VERSION "FL_EP_CANFD"

NS_ :

BS_:

BU_: BMS CDU DCB EAC EVCC FLZCU LBMS RXCU

BO_ 258 BMS_1: 48 BMS
 SG_ BMS_1_CRC1 : 7|8@0+ (1,0) [0|255] "" RXCU
 SG_ BMS_1_RollgCntr1 : 11|4@0+ (1,0) [0|14] "" RXCU
 SG_ BMS_1_Resd1 : 15|4@0+ (1,0) [0|15] "" RXCU
 SG_ BMS_PackVoltage : 23|16@0+ (0.1,0) [0|1000] "volt(V)" RXCU
 SG_ BMS_PackCurrent : 39|16@0+ (0.1,-2047) [-2047|2047] "ampere(A)" RXCU
 SG_ BMS_HvBattSts : 51|4@0+ (1,0) [0|15] "" RXCU
 SG_ BMS_SysSelfCheck : 53|2@0+ (1,0) [0|3] "" RXCU
 SG_ BMS_HVBattThermRunaway : 55|2@0+ (1,0) [0|3] "" RXCU
 SG_ BMS_1_CRC2 : 71|8@0+ (1,0) [0|255] "" RXCU
 SG_ BMS_1_RollgCntr2 : 75|4@0+ (1,0) [0|14] "" RXCU
 SG_ BMS_1_Resd2 : 79|4@0+ (1,0) [0|15] "" RXCU
 SG_ BMS_ChargeVoltageReq : 87|14@0+ (0.1,0) [0|1024] "volt(V)" RXCU
 SG_ BMS_ChgCurrReq : 103|14@0+ (0.1,-1024) [-1024|0] "ampere(A)" RXCU
 SG_ BMS_InfraDcUActDc : 119|14@0+ (0.1,0) [0|1024] "volt(V)" RXCU
 SG_ BMS_1_CRC3 : 135|8@0+ (1,0) [0|255] "" RXCU
 SG_ BMS_1_RollgCntr3 : 139|4@0+ (1,0) [0|14] "" RXCU
 SG_ BMS_1_Resd3 : 143|4@0+ (1,0) [0|15] "" RXCU
 SG_ BMS_InfraDcIActDc : 151|14@0+ (0.1,-1024) [-1024|0] "ampere(A)" RXCU
 SG_ BMS_HvBattDynChrgnILim : 167|14@0+ (0.1,-1024) [-1024|0] "ampere(A)" RXCU
 SG_ BMS_HvBattUChrgnLim : 183|14@0+ (0.1,0) [0|1024] "volt(V)" RXCU
 SG_ BMS_1_CRC4 : 199|8@0+ (1,0) [0|255] "" RXCU
 SG_ BMS_1_RollgCntr4 : 203|4@0+ (1,0) [0|14] "" RXCU
 SG_ BMS_1_Resd4 : 207|4@0+ (1,0) [0|15] "" RXCU
 SG_ BMS_ChrgDcIAvl : 215|14@0+ (0.1,-1024) [-1024|0] "ampere(A)" RXCU
 SG_ BMS_DChrgAPlusSt : 217|1@0+ (1,0) [0|1] "" RXCU
 SG_ BMS_Insulation_R : 231|16@0+ (1,0) [0|60000] "kiloohm(kΩ)" RXCU
 SG_ BMS_ChrgDcCnctrDetd : 241|2@0+ (1,0) [0|3] "" RXCU
 SG_ BMS_DCChgMode : 244|3@0+ (1,0) [0|7] "" RXCU
 SG_ BMS_ChrgDcChrgnFltStopReas : 247|3@0+ (1,0) [0|7] "" RXCU
 SG_ BMS_1_CRC5 : 263|8@0+ (1,0) [0|255] "" RXCU
 SG_ BMS_1_RollgCntr5 : 267|4@0+ (1,0) [0|14] "" RXCU
 SG_ BMS_1_Resd5 : 271|4@0+ (1,0) [0|15] "" RXCU
 SG_ BMS_ChgRemTime : 279|11@0+ (1,0) [0|1440] "min" RXCU
 SG_ BMS_ChargeRequest_Mode : 284|4@0+ (1,0) [0|15] "" RXCU
 SG_ BMS_StateOfEnergy : 311|16@0+ (0.1,0) [0|999.9] "kWh" RXCU
 SG_ BMS_1_CRC6 : 327|8@0+ (1,0) [0|255] "" RXCU
 SG_ BMS_1_RollgCntr6 : 331|4@0+ (1,0) [0|14] "" RXCU
 SG_ BMS_1_Resd6 : 335|4@0+ (1,0) [0|15] "" RXCU
 SG_ BMS_StateOfHealth : 342|7@0+ (1,0) [0|100] "" RXCU
 SG_ BMS_BlanceState : 343|1@0+ (1,0) [0|1] "" RXCU
 SG_ BMS_IsolationFault : 345|2@0+ (1,0) [0|3] "" RXCU
 SG_ BMS_HVILFault_DC : 346|1@0+ (1,0) [0|1] "" RXCU
 SG_ BMS_SOCDis : 359|14@0+ (0.01,0) [0|100] "%" RXCU
 SG_ BMS_InfraDcIActDcMin : 375|14@0+ (0.1,-1024) [-1024|0] "ampere(A)" RXCU

BO_ 369 VCU_COM_1: 16 RXCU
 SG_ VCU_1_CRC1 : 7|8@0+ (1,0) [0|255] "" BMS
 SG_ VCU_1_RollgCntr1 : 11|4@0+ (1,0) [0|14] "" BMS
 SG_ VCU_1_Resd1 : 15|4@0+ (1,0) [0|15] "" BMS
 SG_ VCU_BMSPreheatKeepWarmAllow : 18|3@0+ (1,0) [0|7] "" BMS,CDU
 SG_ VCU_BMSAcChrgPerm : 19|1@0+ (1,0) [0|1] "" BMS,CDU
 SG_ VCU_BMSStsReq_Reserved : 23|4@0+ (1,0) [0|15] "" BMS
 SG_ VCU_ElectronicLockReq : 35|2@0+ (1,0) [0|3] "" Vector__XXX
 SG_ VCU_ErrLvl : 39|4@0+ (1,0) [0|15] "" Vector__XXX
 SG_ VCU_PwtCoolingLvl_171h : 42|3@0+ (1,0) [0|7] "" Vector__XXX
 SG_ HCU_BMSVehDcChrgnIDmd_171h : 55|14@0+ (0.1,-1024) [-1024|0] "A" BMS

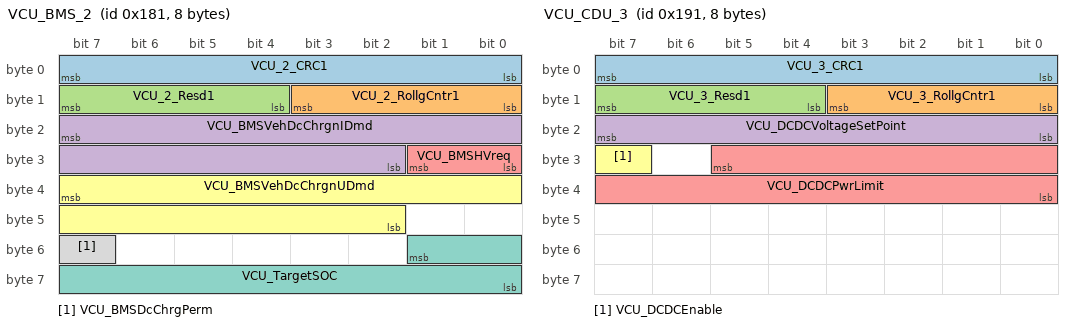
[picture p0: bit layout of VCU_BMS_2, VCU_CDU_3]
BO_ 385 VCU_BMS_2: 8 RXCU
 SG_ VCU_2_CRC1 : 7|8@0+ (1,0) [0|255] "" BMS,FLZCU
 SG_ VCU_2_RollgCntr1 : 11|4@0+ (1,0) [0|14] "" BMS,FLZCU
 SG_ VCU_2_Resd1 : 15|4@0+ (1,0) [0|15] "" BMS,FLZCU
 SG_ VCU_BMSVehDcChrgnIDmd : 23|14@0+ (0.1,-1024) [-1024|0] "ampere (A)" BMS,DCB,FLZCU
 SG_ VCU_BMSHVreq : 25|2@0+ (1,0) [0|3] "" BMS,FLZCU
 SG_ VCU_BMSVehDcChrgnUDmd : 39|14@0+ (0.1,0) [0|1024] "volt (V)" BMS,FLZCU
 SG_ VCU_TargetSOC : 49|10@0+ (0.1,0) [0|100] "%" BMS,FLZCU
 SG_ VCU_BMSDcChrgPerm : 55|1@0+ (1,0) [0|1] "" BMS,FLZCU

BO_ 401 VCU_CDU_3: 8 RXCU
 SG_ VCU_3_CRC1 : 7|8@0+ (1,0) [0|255] "" CDU
 SG_ VCU_3_RollgCntr1 : 11|4@0+ (1,0) [0|14] "" CDU
 SG_ VCU_3_Resd1 : 15|4@0+ (1,0) [0|15] "" CDU
 SG_ VCU_DCDCVoltageSetPoint : 23|8@0+ (0.1,0) [0|20] "V" CDU,LBMS
 SG_ VCU_DCDCPwrLimit : 29|14@0+ (1,0) [0|16382] "w" CDU
 SG_ VCU_DCDCEnable : 31|1@0+ (1,0) [0|1] "" CDU

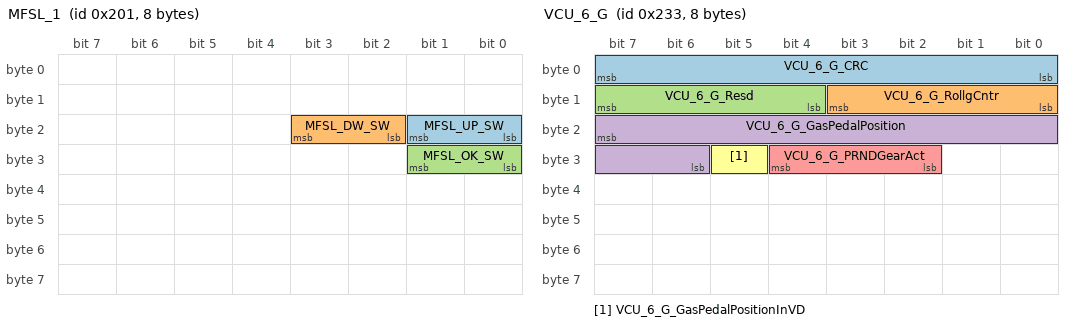
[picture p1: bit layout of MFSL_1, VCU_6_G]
BO_ 513 MFSL_1: 8 FLZCU
 SG_ MFSL_UP_SW : 17|2@0+ (1,0) [0|3] "" RXCU
 SG_ MFSL_DW_SW : 19|2@0+ (1,0) [0|3] "" RXCU
 SG_ MFSL_OK_SW : 25|2@0+ (1,0) [0|3] "" RXCU

BO_ 515 EVCC_1: 24 EVCC
 SG_ EVCC_1_CRC1 : 7|8@0+ (1,0) [0|255] "" RXCU
 SG_ EVCC_1_RollgCntr1 : 11|4@0+ (1,0) [0|14] "" RXCU
 SG_ EVCC_1_Resd1 : 15|4@0+ (1,0) [0|15] "" RXCU
 SG_ EVCC_ElectronicLockSts : 21|3@0+ (1,0) [0|7] "" RXCU
 SG_ EVCC_GunConnectSt_203h : 23|2@0+ (1,0) [0|3] "" RXCU
 SG_ EVCC_CC_RCR4_Sts : 30|13@0+ (1,0) [0|3400] "R" RXCU
 SG_ EVCC_COUNTRY_SUPPORT : 32|2@0+ (1,0) [0|3] "" RXCU
 SG_ EVCC_CP_DutyCycleFault : 33|1@0+ (1,0) [0|1] "" RXCU
 SG_ EVCC_CC_ConnectSts : 49|2@0+ (1,0) [0|3] "" RXCU
 SG_ EVCC_S2Swtsts : 51|2@0+ (1,0) [0|3] "" RXCU
 SG_ EVCC_CPSts : 54|3@0+ (1,0) [0|7] "" RXCU
 SG_ EVCC_ChargeType : 58|3@0+ (1,0) [0|7] "" RXCU
 SG_ EVCC_CC2_Alarm : 59|1@0+ (1,0) [0|1] "" RXCU
 SG_ EVCC_CC2_ConnectSts : 61|2@0+ (1,0) [0|3] "" RXCU
 SG_ EVCC_CC_ConnectDischarSts : 63|2@0+ (1,0) [0|3] "" RXCU
 SG_ EVCC_1_CRC2 : 71|8@0+ (1,0) [0|255] "" RXCU
 SG_ EVCC_1_RollgCntr2 : 75|4@0+ (1,0) [0|14] "" RXCU
 SG_ EVCC_1_Resd2 : 79|4@0+ (1,0) [0|15] "" RXCU
 SG_ EVCC_CPMaxVolt : 84|10@0+ (0.1,0) [0|102.2] "V" RXCU
 SG_ EVCC_FaultLevel : 87|3@0+ (1,0) [0|7] "" RXCU
 SG_ EVCC_DCPlusTemp : 90|8@0+ (1,-40) [-40|213] "℃" RXCU
 SG_ EVCC_DCMinusTemp : 98|8@0+ (1,-40) [-40|213] "℃" RXCU
 SG_ EVCC_TotalFaultNum : 106|8@0+ (1,0) [0|63] "" RXCU
 SG_ EVCC_FaultNum1 : 114|8@0+ (1,0) [0|255] "" RXCU
 SG_ EVCC_FaultNum2 : 151|8@0+ (1,0) [0|255] "" RXCU

BO_ 520 BMS_2: 48 BMS
 SG_ BMS_2_CRC1 : 7|8@0+ (1,0) [0|255] "" RXCU
 SG_ BMS_2_RollgCntr1 : 11|4@0+ (1,0) [0|14] "" RXCU
 SG_ BMS_2_Resd1 : 15|4@0+ (1,0) [0|15] "" RXCU
 SG_ BMS_C2Target_Chg_Voltage : 23|16@0+ (0.1,0) [0|1000] "V" RXCU
 SG_ BMS_CHGstation_MAXPwr : 39|8@0+ (2,0) [0|510] "KW" RXCU
 SG_ BMS_2_CRC2 : 71|8@0+ (1,0) [0|255] "" RXCU
 SG_ BMS_2_RollgCntr2 : 75|4@0+ (1,0) [0|14] "" RXCU
 SG_ BMS_2_Resd2 : 79|4@0+ (1,0) [0|15] "" RXCU
 SG_ BMS_HvBattThermReqLevel : 81|4@0+ (1,0) [0|15] "" RXCU
 SG_ BMS_NV_relay_Sts : 84|3@0+ (1,0) [0|7] "" RXCU
 SG_ BMS_PV_relay_Sts : 87|3@0+ (1,0) [0|7] "" RXCU
 SG_ BMS_QCP_relay_Sts : 90|3@0+ (1,0) [0|7] "" RXCU
 SG_ BMS_QCN_relay_Sts : 93|3@0+ (1,0) [0|7] "" RXCU
 SG_ BMS_Prechage_relay_Sts : 98|3@0+ (1,0) [0|7] "" RXCU
 SG_ BMS_HvBattThermReqMode : 103|4@0+ (1,0) [0|15] "" RXCU
 SG_ BMS_ClntTHvBattIn : 111|8@0+ (1,-40) [-40|120] "gradcelsius(°C)" RXCU
 SG_ BMS_ClntTHvBattOut : 119|8@0+ (1,-40) [-40|120] "gradcelsius(°C)" RXCU
 SG_ BMS_HvBattClntInTReq : 127|7@0+ (1,-40) [-40|53] "gradcelsius(°C)" RXCU
 SG_ BMS_2_CRC3 : 135|8@0+ (1,0) [0|255] "" RXCU
 SG_ BMS_2_RollgCntr3 : 139|4@0+ (1,0) [0|14] "" RXCU
 SG_ BMS_2_Resd3 : 143|4@0+ (1,0) [0|15] "" RXCU
 SG_ BMS_HvBattClntFlowReq : 151|7@0+ (0.25,0) [0|31] "flow-rate(l/min)" RXCU
 SG_ BMS_HvBattAvgT : 159|8@0+ (1,-40) [-40|120] "gradcelsius(°C)" RXCU
 SG_ BMS_HvBattMaxT : 167|8@0+ (1,-40) [-40|210] "gradcelsius(°C)" RXCU
 SG_ BMS_HvBattMinT : 175|8@0+ (1,-40) [-40|210] "gradcelsius(°C)" RXCU
 SG_ BMS_HvBattTdiff : 183|7@0+ (1,0) [0|127] "gradcelsius(°C)" RXCU
 SG_ BMS_2_CRC4 : 199|8@0+ (1,0) [0|255] "" RXCU
 SG_ BMS_2_RollgCntr4 : 203|4@0+ (1,0) [0|14] "" RXCU
 SG_ BMS_2_Resd4 : 207|4@0+ (1,0) [0|15] "" RXCU
 SG_ BMS_OutPosU : 223|14@0+ (0.1,0) [0|1023.0] "volt(V)" RXCU
 SG_ BMS_OutNegU : 239|14@0+ (0.1,0) [0|1023.0] "volt(V)" RXCU
 SG_ BMS_2_CRC5 : 263|8@0+ (1,0) [0|255] "" RXCU
 SG_ BMS_2_RollgCntr5 : 267|4@0+ (1,0) [0|14] "" RXCU
 SG_ BMS_2_Resd5 : 271|4@0+ (1,0) [0|15] "" RXCU
 SG_ BMS_outQCPosU : 279|14@0+ (0.1,0) [0|1023.0] "volt(V)" RXCU
 SG_ BMS_outQCNegU : 295|14@0+ (0.1,0) [0|1023.0] "volt(V)" RXCU
 SG_ BMS_Middlesplit_relay_Sts : 311|3@0+ (1,0) [0|7] "" RXCU

BO_ 523 BMS_3: 48 BMS
 SG_ BMS_3_CRC1 : 7|8@0+ (1,0) [0|255] "" RXCU
 SG_ BMS_3_RollgCntr1 : 11|4@0+ (1,0) [0|14] "" RXCU
 SG_ BMS_3_Resd1 : 15|4@0+ (1,0) [0|15] "" RXCU
 SG_ BMS_HvBattPMaxReChrgLim : 39|14@0+ (0.1,0) [0|1024] "kW" RXCU
 SG_ BMS_3_CRC2 : 71|8@0+ (1,0) [0|255] "" RXCU
 SG_ BMS_3_RollgCntr2 : 75|4@0+ (1,0) [0|14] "" RXCU
 SG_ BMS_3_Resd2 : 79|4@0+ (1,0) [0|15] "" RXCU
 SG_ BMS_HvBattIMaxReChrgLim : 87|11@0+ (1,-2047) [-2047|0] "ampere(A)" RXCU
 SG_ BMS_HvBattPMaxDchaLim : 119|14@0+ (0.1,0) [0|1024] "kW" RXCU
 SG_ BMS_3_CRC3 : 135|8@0+ (1,0) [0|255] "" RXCU
 SG_ BMS_3_RollgCntr3 : 139|4@0+ (1,0) [0|14] "" RXCU
 SG_ BMS_3_Resd3 : 143|4@0+ (1,0) [0|15] "" RXCU
 SG_ BMS_HvBattIMaxDchaLim : 167|11@0+ (1,0) [0|2047] "ampere(A)" RXCU
 SG_ BMS_3_CRC4 : 199|8@0+ (1,0) [0|255] "" RXCU
 SG_ BMS_3_RollgCntr4 : 203|4@0+ (1,0) [0|14] "" RXCU
 SG_ BMS_3_Resd4 : 207|4@0+ (1,0) [0|15] "" RXCU
 SG_ BMS_3_CRC5 : 263|8@0+ (1,0) [0|255] "" RXCU
 SG_ BMS_3_RollgCntr5 : 267|4@0+ (1,0) [0|14] "" RXCU
 SG_ BMS_3_Resd5 : 271|4@0+ (1,0) [0|15] "" RXCU
 SG_ BMS_KL30Volt : 279|11@0+ (0.01,0) [0|20] "volt(V)" RXCU
 SG_ BMS_kL87Volt : 295|11@0+ (0.01,0) [0|20] "volt(V)" RXCU
 SG_ BMS_HvBattUDchaLim : 311|14@0+ (0.1,0) [0|1024] "volt(V)" RXCU
 SG_ BMS_3_CRC6 : 327|8@0+ (1,0) [0|255] "" RXCU
 SG_ BMS_3_RollgCntr6 : 331|4@0+ (1,0) [0|14] "" RXCU
 SG_ BMS_3_Resd6 : 335|4@0+ (1,0) [0|15] "" RXCU
 SG_ BMSH_MaxChgPwrPeak : 343|12@0+ (0.1,0) [0|320] "KW" RXCU
 SG_ BMSH_MaxDchgPwrPeak : 347|12@0+ (0.1,0) [0|320] "KW" RXCU

BO_ 563 VCU_6_G: 8 RXCU
 SG_ VCU_6_G_CRC : 7|8@0+ (1,0) [0|255] "" FLZCU
 SG_ VCU_6_G_RollgCntr : 11|4@0+ (1,0) [0|14] "" FLZCU
 SG_ VCU_6_G_Resd : 15|4@0+ (1,0) [0|15] "" FLZCU
 SG_ VCU_6_G_GasPedalPosition : 23|10@0+ (0.1,0) [0|100] "%" FLZCU
 SG_ VCU_6_G_PRNDGearAct : 28|3@0+ (1,0) [0|7] "" FLZCU
 SG_ VCU_6_G_GasPedalPositionInVD : 29|1@0+ (1,0) [0|1] "" FLZCU

BO_ 638 FRZCU_9: 16 FLZCU
 SG_ FRZCU_HoodSts : 45|2@0+ (1,0) [0|3] "" RXCU

BO_ 644 ICC_REEV_17: 8 FLZCU
 SG_ ICM_5_FuelLevel_284h : 23|8@0+ (1,0) [0|100] "%" RXCU

BO_ 683 FRZCU_1: 8 FLZCU
 SG_ PassDoorSts_2ABh : 22|2@0+ (1,0) [0|3] "" RXCU
 SG_ PassRearDoorSts_2ABh : 49|2@0+ (1,0) [0|3] "" RXCU

BO_ 745 DCB_1: 32 DCB
 SG_ DCB_1_HVILSts : 17|2@0+ (1,0) [0|3] "" RXCU
 SG_ DCB_1_BoostNegRelaySts : 20|3@0+ (1,0) [0|7] "" RXCU
 SG_ DCB_1_WorkingSts : 23|3@0+ (1,0) [0|7] "" RXCU
 SG_ DCB_1_NegFastChgRelaySts : 28|3@0+ (1,0) [0|7] "" RXCU
 SG_ DCB_1_C2RelaySts : 31|3@0+ (1,0) [0|7] "" RXCU
 SG_ DCB_1_ErrorLevel : 36|3@0+ (1,0) [0|7] "" RXCU
 SG_ DCB_1_PosFastChgRelaySts : 39|3@0+ (1,0) [0|7] "" RXCU
 SG_ DCB_1_ChrgDerate : 63|8@0+ (1,0) [0|100] "%" RXCU
 SG_ DCB_1_C2RearVolt : 103|16@0+ (0.05,0) [0|1000] "V" RXCU
 SG_ DCB_1_InputVolt : 119|16@0+ (0.05,0) [0|1000] "V" RXCU
 SG_ DCB_1_BoostNegFrontVolt : 151|16@0+ (0.05,0) [0|1000] "V" RXCU
 SG_ DCB_1_NegFastChgFrontVolt : 167|16@0+ (0.05,0) [0|1000] "V" RXCU
 SG_ DCB_1_BoostPosFastChgRearVolt : 183|16@0+ (0.05,0) [0|1000] "V" RXCU
 SG_ DCB_1_BoostPosRelaySts : 223|3@0+ (1,0) [0|7] "" RXCU

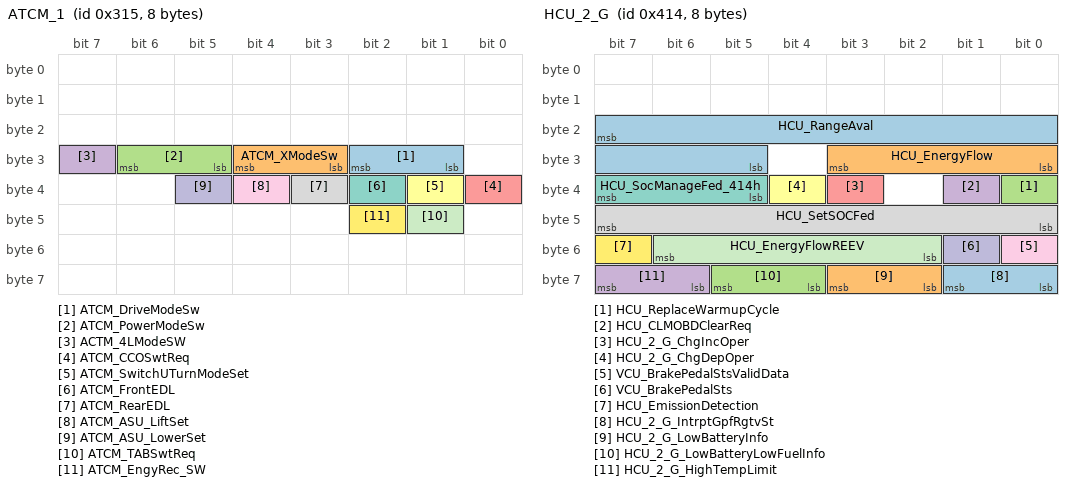
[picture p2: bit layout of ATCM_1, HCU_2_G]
BO_ 789 ATCM_1: 8 FLZCU
 SG_ ATCM_DriveModeSw : 26|2@0+ (1,0) [0|3] "" RXCU
 SG_ ATCM_XModeSw : 28|2@0+ (1,0) [0|3] "" RXCU
 SG_ ATCM_PowerModeSw : 30|2@0+ (1,0) [0|3] "" RXCU
 SG_ ACTM_4LModeSW : 31|1@0+ (1,0) [0|1] "" RXCU
 SG_ ATCM_CCOSwtReq : 32|1@0+ (1,0) [0|1] "" RXCU
 SG_ ATCM_SwitchUTurnModeSet : 33|1@0+ (1,0) [0|1] "" RXCU
 SG_ ATCM_FrontEDL : 34|1@0+ (1,0) [0|1] "" RXCU
 SG_ ATCM_RearEDL : 35|1@0+ (1,0) [0|1] "" RXCU
 SG_ ATCM_ASU_LiftSet : 36|1@0+ (1,0) [0|1] "" RXCU
 SG_ ATCM_ASU_LowerSet : 37|1@0+ (1,0) [0|1] "" RXCU
 SG_ ATCM_TABSwtReq : 41|1@0+ (1,0) [0|1] "" RXCU
 SG_ ATCM_EngyRec_SW : 42|1@0+ (1,0) [0|1] "" RXCU

BO_ 859 FLZCU_5: 8 FLZCU
 SG_ FLZCU_IRCHV_Req : 31|2@0+ (1,0) [0|3] "" RXCU

BO_ 961 IMMO_VCU_1: 8 FLZCU
 SG_ IMMO_Auth_VCU : 7|64@0+ (1,0) [0|18446744073709551615] "" RXCU

BO_ 962 VCU_IMMO_1: 8 RXCU
 SG_ VCU_Chall_IMMO : 7|64@0+ (1,0) [0|18446744073709551615] "" FLZCU

BO_ 964 IMMO_VCU_3: 8 FLZCU
 SG_ IMMO_Teach_VCU : 7|64@0+ (1,0) [0|18446744073709551615] "" RXCU

BO_ 966 VCU_IMMO_3: 8 RXCU
 SG_ VCU_Teach_IMMO : 7|64@0+ (1,0) [0|18446744073709551615] "" FLZCU

BO_ 991 TMS_2: 24 FLZCU
 SG_ ErrorLevel : 91|2@0+ (1,0) [0|3] "" RXCU
 SG_ TMS_HV_Req : 94|2@0+ (1,0) [0|3] "" RXCU
 SG_ TMS_EngingstartReq : 127|1@0+ (1,0) [0|1] "" RXCU

BO_ 1024 FRZCU_13: 64 FLZCU
 SG_ FRZCU_OnekeyHVoffSwtst : 41|2@0+ (1,0) [0|3] "" RXCU

BO_ 1029 LBMS_SysSt1: 32 LBMS
 SG_ LBMS_PackExtU : 91|15@0+ (0.001,0) [0|20] "V" RXCU
 SG_ LBMS_PackT1 : 106|8@0+ (1,-40) [-40|125] "degC" RXCU
 SG_ LBMS_PackExtUVld : 107|1@0+ (1,0) [0|1] "" RXCU
 SG_ LBMS_PackT2 : 114|8@0+ (1,-40) [-40|125] "degC" RXCU
 SG_ LBMS_PackT3 : 122|8@0+ (1,-40) [-40|125] "degC" RXCU
 SG_ LBMS_PackTVld : 130|1@0+ (1,0) [0|1] "" RXCU

BO_ 1034 HCU_1_G: 8 RXCU
 SG_ HCU_1_G_CRC1 : 7|8@0+ (1,0) [0|255] "" Vector__XXX
 SG_ HCU_1_G_RollgCntr1 : 11|4@0+ (1,0) [0|14] "" Vector__XXX
 SG_ HCU_1_G_Resd1 : 15|4@0+ (1,0) [0|15] "" Vector__XXX
 SG_ HCU_EmPwr : 23|8@0+ (1,-128) [-100|100] "%" Vector__XXX
 SG_ HCU_VehicleState : 27|4@0+ (1,0) [0|15] "" Vector__XXX
 SG_ HCU_RunMode : 29|2@0+ (1,0) [0|3] "" Vector__XXX
 SG_ HCU_TMNumber : 31|2@0+ (1,0) [0|3] "" Vector__XXX
 SG_ HCU_PwrTrnModeDisp : 34|3@0+ (1,0) [0|7] "" Vector__XXX
 SG_ HCU_IntelligentPowerSupply : 37|3@0+ (1,0) [0|7] "" Vector__XXX
 SG_ HCU_PowerModeFed : 39|2@0+ (1,0) [0|3] "" BMS
 SG_ HCU_LimpHomeMode : 41|2@0+ (1,0) [0|3] "" Vector__XXX
 SG_ HCU_ISGRegenerateSts : 42|1@0+ (1,0) [0|1] "" Vector__XXX
 SG_ HCU_EmOverSpdWarn : 43|1@0+ (1,0) [0|1] "" Vector__XXX
 SG_ HCU_PowertrainFault : 44|1@0+ (1,0) [0|1] "" Vector__XXX
 SG_ HCU_PrePTReady : 45|1@0+ (1,0) [0|1] "" Vector__XXX
 SG_ HCU_PowerModeChangeFail : 46|1@0+ (1,0) [0|1] "" Vector__XXX
 SG_ BMSH_MILReq : 47|1@0+ (1,0) [0|1] "" Vector__XXX
 SG_ TMF_EngMilLampReq : 48|1@0+ (1,0) [0|1] "" Vector__XXX
 SG_ TMR_EngMilLampReq : 49|1@0+ (1,0) [0|1] "" Vector__XXX
 SG_ HCU_MILReq : 50|1@0+ (1,0) [0|1] "" Vector__XXX
 SG_ HCU_HVReady : 51|1@0+ (1,0) [0|1] "" BMS
 SG_ HCU_PTReady : 52|1@0+ (1,0) [0|1] "" BMS
 SG_ HCU_ChargingSts : 54|2@0+ (1,0) [0|3] "" Vector__XXX
 SG_ HCU_PtSts : 59|4@0+ (1,0) [0|15] "" Vector__XXX
 SG_ HCU_InHbStrtRes : 63|4@0+ (1,0) [0|15] "" Vector__XXX

BO_ 1035 VCC_1: 8 FLZCU
 SG_ VCC_1_OTASts : 17|2@0+ (1,0) [0|3] "" RXCU

BO_ 1038 LBMS_SysSt2: 48 LBMS
 SG_ LBMS_SOC : 31|7@0+ (1,0) [0|100] "%" RXCU
 SG_ LBMS_ReChrgReq : 33|3@0+ (1,0) [0|7] "" RXCU
 SG_ LBMS_ReqChrgU : 80|15@0+ (0.001,0) [0|20] "V" RXCU

BO_ 1039 LBMS_SysSt3: 32 LBMS
 SG_ LBMS_ChargeSts : 48|4@0+ (1,0) [0|15] "" RXCU
 SG_ LBMS_ChargeFlt : 49|1@0+ (1,0) [0|1] "" RXCU
 SG_ LBMS_ChargeEnable : 51|1@0+ (1,0) [0|1] "" RXCU

BO_ 1043 FLZCU_8: 8 FLZCU
 SG_ EBS_U_BATT : 7|14@0+ (0.0009765625,3) [3|18] "V" RXCU

BO_ 1044 HCU_2_G: 8 RXCU
 SG_ HCU_RangeAval : 23|11@0+ (1,0) [0|2046] "KM" FLZCU
 SG_ HCU_EnergyFlow : 27|4@0+ (1,0) [0|15] "" FLZCU
 SG_ HCU_ReplaceWarmupCycle : 32|1@0+ (1,0) [0|1] "" BMS,FLZCU
 SG_ HCU_CLMOBDClearReq : 33|1@0+ (1,0) [0|1] "" FLZCU
 SG_ HCU_2_G_ChgIncOper : 35|1@0+ (1,0) [0|1] "" FLZCU
 SG_ HCU_2_G_ChgDepOper : 36|1@0+ (1,0) [0|1] "" FLZCU
 SG_ HCU_SocManageFed_414h : 39|3@0+ (1,0) [0|7] "" FLZCU
 SG_ HCU_SetSOCFed : 47|8@0+ (1,0) [0|100] "" FLZCU
 SG_ VCU_BrakePedalStsValidData : 48|1@0+ (1,0) [0|1] "" FLZCU
 SG_ VCU_BrakePedalSts : 49|1@0+ (1,0) [0|1] "" FLZCU
 SG_ HCU_EnergyFlowREEV : 54|5@0+ (1,0) [0|31] "" FLZCU
 SG_ HCU_EmissionDetection : 55|1@0+ (1,0) [0|1] "" FLZCU
 SG_ HCU_2_G_IntrptGpfRgtvSt : 57|2@0+ (1,0) [0|3] "" FLZCU
 SG_ HCU_2_G_LowBatteryInfo : 59|2@0+ (1,0) [0|3] "" FLZCU
 SG_ HCU_2_G_LowBatteryLowFuelInfo : 61|2@0+ (1,0) [0|3] "" FLZCU
 SG_ HCU_2_G_HighTempLimit : 63|2@0+ (1,0) [0|3] "" FLZCU

BO_ 1045 TBOX_HW_415h: 32 FLZCU
 SG_ TBOX_OTAHV_Req_415h : 20|2@0+ (1,0) [0|3] "" RXCU

BO_ 1055 BMS_4: 16 BMS
 SG_ BMS_4_CRC1 : 7|8@0+ (1,0) [0|255] "" RXCU
 SG_ BMS_4_RollgCntr1 : 11|4@0+ (1,0) [0|14] "" RXCU
 SG_ BMS_4_Resd1 : 15|4@0+ (1,0) [0|15] "" RXCU
 SG_ BMS_ErrorNumber : 47|8@0+ (1,0) [0|255] "" RXCU
 SG_ BMS_ErrorCode : 55|16@0+ (1,0) [0|65535] "" RXCU
 SG_ BMS_4_CRC2 : 71|8@0+ (1,0) [0|255] "" RXCU
 SG_ BMS_4_RollgCntr2 : 75|4@0+ (1,0) [0|14] "" RXCU
 SG_ BMS_4_Resd2 : 79|4@0+ (1,0) [0|15] "" RXCU
 SG_ BMSH_MILReq_41Fh : 80|1@0+ (1,0) [0|1] "" RXCU
 SG_ BMS_HvBattUnderTemperature : 83|1@0+ (1,0) [0|1] "" RXCU
 SG_ BMS_ErrorLevel : 87|4@0+ (1,0) [0|15] "" RXCU
 SG_ BMS_ThermRunCode : 95|8@0+ (1,0) [0|255] "" RXCU
 SG_ BMS_DChrgEndCode : 103|8@0+ (1,0) [0|255] "" RXCU
 SG_ BMS_PwrDerateFlg : 111|2@0+ (1,0) [0|3] "" RXCU

BO_ 1057 VCU_7_G: 32 RXCU
 SG_ VCU_shfChk : 16|1@0+ (1,0) [0|1] "" FLZCU
 SG_ VCU_PowerLimitSOCLow : 19|3@0+ (1,0) [0|7] "" FLZCU
 SG_ VCU_MCU_MilLampReq : 20|1@0+ (1,0) [0|1] "" FLZCU
 SG_ VCU_OPDinfo : 23|3@0+ (1,0) [0|7] "" FLZCU
 SG_ VCU_ePTDrvPowerPcent : 31|8@0+ (1,-100) [-100|100] "%" FLZCU
 SG_ VCU_TowingMode : 33|2@0+ (1,0) [0|3] "" FLZCU
 SG_ VCU_EgyRegenLevelHighAllowed : 35|2@0+ (1,0) [0|3] "" FLZCU
 SG_ VCU_SportDriveModeAvailable : 36|1@0+ (1,0) [0|1] "" FLZCU
 SG_ VCU_RainSnowDriveModeAvailable : 37|1@0+ (1,0) [0|1] "" FLZCU
 SG_ VCU_OffRoadDriveModeAvailable : 38|1@0+ (1,0) [0|1] "" FLZCU
 SG_ VCU_CampAvailable : 39|1@0+ (1,0) [0|1] "" FLZCU
 SG_ VCU_DisChgSOCHighLim : 47|8@0+ (1,0) [1|100] "%" FLZCU
 SG_ VCU_DisChgSOCLowLim : 55|8@0+ (1,0) [1|50] "%" FLZCU
 SG_ VCU_ChgSocSetFed : 63|8@0+ (1,0) [50|100] "%" FLZCU
 SG_ VCU_EngyConsuPer10Km : 87|12@0+ (0.1,-100) [-100|100] "" FLZCU
 SG_ VCU_EngyConsuPer25Km : 91|12@0+ (0.1,-100) [-100|100] "" FLZCU
 SG_ VCU_EngyConsuPer50Km : 111|12@0+ (0.1,-100) [-100|100] "" FLZCU
 SG_ VCU_EngyConsuPer100m : 115|12@0+ (0.1,-100) [-100|100] "" FLZCU
 SG_ VCU_DisChrgPwr : 151|8@0+ (0.1,0) [0|25.5] "kW" FLZCU
 SG_ VCU_BookChrgSetFailRes : 154|3@0+ (1,0) [0|7] "" FLZCU
 SG_ VCU_BookChrgFailRes : 158|4@0+ (1,0) [0|15] "" FLZCU
 SG_ VCU_HVILFault : 159|1@0+ (1,0) [0|1] "" FLZCU
 SG_ VCUExtendRang : 167|10@0+ (1,0) [0|1022] "KM" FLZCU
 SG_ VCU_KeepWarmFailReason : 171|4@0+ (1,0) [0|15] "" FLZCU
 SG_ VCU_ExtremeEnergySavingModeAv : 173|1@0+ (1,0) [0|1] "" FLZCU
 SG_ VCU_TowModeAvailable : 176|1@0+ (1,0) [0|1] "" FLZCU
 SG_ VCU_StopModeSWStsResp : 178|2@0+ (1,0) [0|3] "" FLZCU
 SG_ VCU_StopModeSWAllowed : 179|1@0+ (1,0) [0|1] "" FLZCU
 SG_ VCU_ChgDisChgLedCtrl : 183|4@0+ (1,0) [0|15] "" FLZCU
 SG_ VCU_CPMaxVolt : 191|8@0+ (0.1,0) [0|20] "V" FLZCU
 SG_ VCUExtremeEnergySavingModeReq : 211|2@0+ (1,0) [0|3] "" FLZCU
 SG_ VCU_EpedalModeSts : 213|1@0+ (1,0) [0|1] "" FLZCU
 SG_ VCU_BookChrgStsFb : 215|2@0+ (1,0) [0|3] "" FLZCU
 SG_ VCU_HVNM : 219|2@0+ (1,0) [0|3] "" FLZCU
 SG_ VCU_DriveMode : 223|3@0+ (1,0) [0|7] "" FLZCU
 SG_ HCU_EnterForceEVFailRes : 229|3@0+ (1,0) [0|7] "" FLZCU
 SG_ HCU_EngineSelfMaintain : 231|2@0+ (1,0) [0|3] "" FLZCU
 SG_ HCU_EnterForceChrgFailRes : 234|3@0+ (1,0) [0|7] "" FLZCU
 SG_ HCU_InStartRes : 242|3@0+ (1,0) [0|7] "" FLZCU
 SG_ HCU_EnergyRegSetFed : 255|8@0+ (1,0) [0|100] "%" FLZCU

BO_ 1078 PLG_1: 8 FLZCU
 SG_ PLG_LatchSts : 33|2@0+ (1,0) [0|3] "" RXCU

BO_ 1086 VCU_CDU_8: 16 RXCU
 SG_ VCU_8_CRC1 : 7|8@0+ (1,0) [0|255] "" CDU
 SG_ VCU_8_RollgCntr1 : 11|4@0+ (1,0) [0|14] "" CDU
 SG_ VCU_8_Resd1 : 15|4@0+ (1,0) [0|15] "" CDU
 SG_ VCU_OBCChgCurrentReq : 23|16@0+ (0.1,0) [0|400] "A" CDU
 SG_ VCU_OBCChgVoltageReq : 39|16@0+ (0.1,0) [0|1000] "V" CDU
 SG_ VCU_OBCDischgPwrLimit : 55|8@0+ (0.1,0) [0|20] "kw" CDU
 SG_ VCU_OBCDischgReq : 63|1@0+ (1,0) [0|1] "" CDU
 SG_ VCU_8_CRC2 : 71|8@0+ (1,0) [0|255] "" CDU
 SG_ VCU_8_RollgCntr2 : 75|4@0+ (1,0) [0|14] "" CDU
 SG_ VCU_8_Resd2 : 79|4@0+ (1,0) [0|15] "" CDU
 SG_ VCU_OBCInnerDischgPwrLimit : 87|8@0+ (0.1,0) [0|20] "kw" CDU
 SG_ VCU_OBCInnerDischgAllow : 88|1@0+ (1,0) [0|1] "" CDU
 SG_ VCU_CLMSystemPowerLimit_43Eh : 119|10@0+ (0.04,0) [0|40] "Kw" Vector__XXX
 SG_ VCU_CLMEACAllow_43Eh : 123|1@0+ (1,0) [0|1] "" Vector__XXX
 SG_ VCU_CLMHVHAllow_43Eh : 124|1@0+ (1,0) [0|1] "" Vector__XXX
 SG_ VCU_CLMHVReady_43Eh : 125|1@0+ (1,0) [0|1] "" Vector__XXX

BO_ 1092 BNCM_11: 8 FLZCU
 SG_ BNCM_11_EVSEConnectSts : 17|2@0+ (1,0) [0|3] "" RXCU

BO_ 1096 TMS_11: 32 FLZCU
 SG_ TMS_ICAstsFed_448h : 111|2@0+ (1,0) [0|3] "" RXCU
 SG_ TMS_RemotekeyReq : 148|3@0+ (1,0) [0|7] "" RXCU
 SG_ TMS_TimedVentilationReq : 151|3@0+ (1,0) [0|7] "" RXCU

BO_ 1111 EAC_Rsp_1: 16 EAC
 SG_ EAC_HVILSts : 41|2@0+ (1,0) [0|3] "" RXCU
 SG_ EAC_ErrorLevel : 122|3@0+ (1,0) [0|7] "" RXCU

BO_ 1117 HVH_Rsp_1: 8 FLZCU
 SG_ HVH_ErrorLevel : 63|3@0+ (1,0) [0|7] "" RXCU

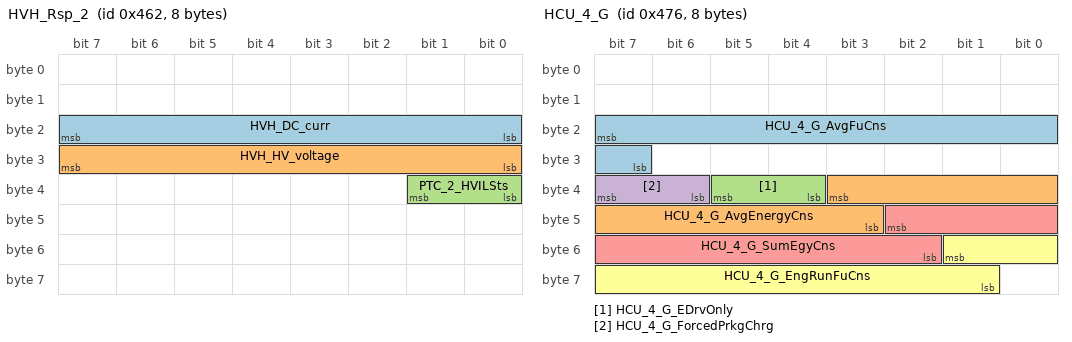
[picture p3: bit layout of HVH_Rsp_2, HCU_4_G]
BO_ 1122 HVH_Rsp_2: 8 FLZCU
 SG_ HVH_DC_curr : 23|8@0+ (0.25,0) [0|50] "A" RXCU
 SG_ HVH_HV_voltage : 31|8@0+ (4,0) [0|1016] "V" RXCU
 SG_ PTC_2_HVILSts : 33|2@0+ (1,0) [0|3] "" RXCU

BO_ 1127 CDU_DCDC_1: 24 CDU
 SG_ CDU_1_CRC1 : 7|8@0+ (1,0) [0|255] "" RXCU
 SG_ CDU_1_RollgCntr1 : 11|4@0+ (1,0) [0|14] "" RXCU
 SG_ CDU_1_Resd1 : 15|4@0+ (1,0) [0|15] "" RXCU
 SG_ DCDC_HvVolt : 23|16@0+ (0.1,0) [0|1000] "V" RXCU
 SG_ DCDC_HVCurr : 39|16@0+ (0.1,0) [0|1000] "A" RXCU
 SG_ DCDC_FaultCode : 55|8@0+ (1,0) [0|255] "" RXCU
 SG_ CDU_1_CRC2 : 71|8@0+ (1,0) [0|255] "" RXCU
 SG_ CDU_1_RollgCntr2 : 75|4@0+ (1,0) [0|14] "" RXCU
 SG_ CDU_1_Resd2 : 79|4@0+ (1,0) [0|15] "" RXCU
 SG_ DCDC_LvSideCurr : 87|12@0+ (1,0) [0|510] "A" RXCU
 SG_ DCDC_OverTemp : 88|1@0+ (1,0) [0|1] "" RXCU
 SG_ DCDC_LvSideVolt : 103|11@0+ (0.1,0) [0|25.3] "V" RXCU
 SG_ DCDC_EnableSts : 104|1@0+ (1,0) [0|1] "" RXCU
 SG_ DCDC_FaultLevelSts : 107|3@0+ (1,0) [0|7] "" RXCU
 SG_ DCDC_LvSideCurrMax : 119|12@0+ (1,0) [0|510] "A" RXCU

BO_ 1137 ICC_TBOX_27: 32 FLZCU
 SG_ ICC_BookChrgSetReq : 23|2@0+ (1,0) [0|3] "" RXCU
 SG_ ICC_BkChrgStartTimeYear : 31|16@0+ (1,1900) [1900|9999] "年" RXCU
 SG_ ICC_BkChrgStartTimeDay : 47|5@0+ (1,0) [1|31] "日" RXCU
 SG_ ICC_BkChrgStartTimeHour : 55|5@0+ (1,0) [0|23] "小时" RXCU
 SG_ ICC_BkChrgStartTimemMin : 63|6@0+ (1,0) [0|59] "分钟" RXCU
 SG_ ICC_BkChrgDuration : 83|11@0+ (1,0) [0|1440] "min" RXCU
 SG_ ICC_BkChrgStartTimeMonth : 87|4@0+ (1,0) [1|12] "月" RXCU
 SG_ ICC_BkChrgCycleMon : 98|2@0+ (1,0) [0|3] "" RXCU
 SG_ ICC_StopChrgReq : 100|2@0+ (1,0) [0|3] "" RXCU
 SG_ ICC_BkChrgCycleType : 103|3@0+ (1,0) [0|7] "" RXCU
 SG_ ICC_BkChrgCycleFri : 105|2@0+ (1,0) [0|3] "" RXCU
 SG_ ICC_BkChrgCycleThur : 107|2@0+ (1,0) [0|3] "" RXCU
 SG_ ICC_BkChrgCycleWen : 109|2@0+ (1,0) [0|3] "" RXCU
 SG_ ICC_BkChrgCycleTues : 111|2@0+ (1,0) [0|3] "" RXCU
 SG_ ICC_BkChrgCycleSun : 117|2@0+ (1,0) [0|3] "" RXCU
 SG_ ICC_BkChrgCycleSat : 119|2@0+ (1,0) [0|3] "" RXCU
 SG_ ICC_KeepWarmStrt : 124|5@0+ (1,0) [1|31] "日" RXCU
 SG_ ICC_KeepWarmStrtHour : 148|5@0+ (1,0) [0|23] "小时" RXCU
 SG_ ICC_KeepWarmStrtMin : 157|6@0+ (1,0) [0|59] "分钟" RXCU
 SG_ ICC_PetmodeFb : 159|2@0+ (1,0) [0|3] "" RXCU
 SG_ ICC_SentinelModeFaultSts : 161|2@0+ (1,0) [0|3] "" RXCU
 SG_ ICC_SentinelModeWorkingSts : 165|4@0+ (1,0) [0|15] "" RXCU
 SG_ ICC_SentinelModeSwitchSts : 167|2@0+ (1,0) [0|3] "" RXCU
 SG_ ICC_SentinelModeExitReason : 173|3@0+ (1,0) [0|7] "" RXCU
 SG_ ICC_SentinelModeAlarmSts : 175|2@0+ (1,0) [0|3] "" RXCU
 SG_ ICC_PetModeWarn_2 : 183|5@0+ (1,0) [0|31] "" RXCU
 SG_ ICM_FuelLevel : 215|8@0+ (1,0) [0|255] "L" RXCU
 SG_ ICM_AverageVehicleSpeed : 223|8@0+ (1,0) [0|255] "Km/h" RXCU
 SG_ ICM_DistenceToEmpty_Km : 231|11@0+ (1,0) [0|2047] "km" RXCU
 SG_ ICM_Maintenance_tips : 234|1@0+ (1,0) [0|1] "" RXCU
 SG_ ICM_FuelLevelFailSts : 235|1@0+ (1,0) [0|1] "" RXCU
 SG_ ICM_SumTrip : 247|14@0+ (1,0) [0|16383] "km" RXCU

BO_ 1142 HCU_4_G: 8 RXCU
 SG_ HCU_4_G_AvgFuCns : 23|9@0+ (0.1,0) [0|50] "L/100km" FLZCU
 SG_ HCU_4_G_AvgEnergyCns : 35|9@0+ (0.1,0) [0|50] "L/100km" FLZCU
 SG_ HCU_4_G_EDrvOnly : 37|2@0+ (1,0) [0|3] "" FLZCU
 SG_ HCU_4_G_ForcedPrkgChrg : 39|2@0+ (1,0) [0|3] "" FLZCU
 SG_ HCU_4_G_SumEgyCns : 42|9@0+ (0.1,0) [0|50] "L/100km" FLZCU
 SG_ HCU_4_G_EngRunFuCns : 49|9@0+ (0.1,0) [0|50] "L/100km" FLZCU

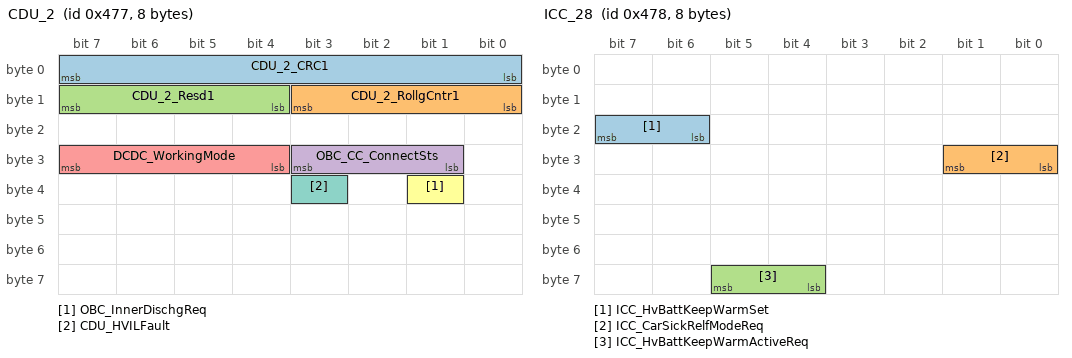
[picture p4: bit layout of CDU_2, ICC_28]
BO_ 1143 CDU_2: 8 CDU
 SG_ CDU_2_CRC1 : 7|8@0+ (1,0) [0|255] "" RXCU
 SG_ CDU_2_RollgCntr1 : 11|4@0+ (1,0) [0|14] "" RXCU
 SG_ CDU_2_Resd1 : 15|4@0+ (1,0) [0|15] "" RXCU
 SG_ OBC_CC_ConnectSts : 27|3@0+ (1,0) [0|7] "" RXCU
 SG_ DCDC_WorkingMode : 31|4@0+ (1,0) [0|15] "" RXCU
 SG_ OBC_InnerDischgReq : 33|1@0+ (1,0) [0|1] "" RXCU
 SG_ CDU_HVILFault : 35|1@0+ (1,0) [0|1] "" RXCU

BO_ 1144 ICC_28: 8 FLZCU
 SG_ ICC_HvBattKeepWarmSet : 23|2@0+ (1,0) [0|3] "" RXCU
 SG_ ICC_CarSickRelfModeReq : 25|2@0+ (1,0) [0|3] "" RXCU
 SG_ ICC_HvBattKeepWarmActiveReq : 61|2@0+ (1,0) [0|3] "" RXCU

BO_ 1155 ASU_3: 16 FLZCU
 SG_ ASU_3_LvlAdj_Restriction : 47|2@0+ (1,0) [0|3] "" RXCU

BO_ 1167 ICC_35: 32 FLZCU
 SG_ ICC_KeyDriveModememory : 17|2@0+ (1,0) [0|3] "" RXCU
 SG_ ICC_DriveModeSet : 22|5@0+ (1,0) [0|31] "" RXCU
 SG_ ICC_DRIFTModeSetReq : 25|2@0+ (1,0) [0|3] "" RXCU
 SG_ ICC_EXPERTEIPBESPSet : 27|2@0+ (1,0) [0|3] "" RXCU
 SG_ ICC_EXPERTEcoSet : 29|2@0+ (1,0) [0|3] "" RXCU
 SG_ ICC_EXPERTNormSet : 31|2@0+ (1,0) [0|3] "" RXCU
 SG_ ICC_EXPERTSportSet : 33|2@0+ (1,0) [0|3] "" RXCU
 SG_ ICC_CrossaxisSet : 35|2@0+ (1,0) [0|3] "" RXCU
 SG_ ICC_EXPERTRWDSet : 37|2@0+ (1,0) [0|3] "" RXCU
 SG_ ICC_EXPERTAWDSet : 39|2@0+ (1,0) [0|3] "" RXCU
 SG_ ICC_EXPERTAutoSet : 41|2@0+ (1,0) [0|3] "" RXCU
 SG_ ICC_CLIMBSet : 43|2@0+ (1,0) [0|3] "" RXCU
 SG_ ICC_DriveModeExitSet : 45|2@0+ (1,0) [0|3] "" RXCU
 SG_ ICC_CCOSwtReq : 49|2@0+ (1,0) [0|3] "" RXCU
 SG_ ICC_TABSwtReq : 51|2@0+ (1,0) [0|3] "" RXCU
 SG_ ICC_Confidencelevel : 62|7@0+ (1,-1) [0|100] "%" RXCU
 SG_ ICC_V2L_IntlDisChg : 81|2@0+ (1,0) [0|3] "" RXCU
 SG_ ICC_ExhibitionModeSwitch : 83|2@0+ (1,0) [0|3] "" RXCU
 SG_ ICC_TrailerMode : 85|2@0+ (1,0) [0|3] "" RXCU
 SG_ ICC_V2L_DisChgMem : 87|2@0+ (1,0) [0|3] "" RXCU
 SG_ ICC_DrivePowerDispSet : 89|2@0+ (1,0) [0|3] "" RXCU
 SG_ ICC_WLTC_to_CLTC_Mode : 91|2@0+ (1,0) [0|3] "" RXCU
 SG_ ICC_StopChrgnSwitch : 93|2@0+ (1,0) [0|3] "" RXCU
 SG_ ICC_StopChrgnMode : 95|2@0+ (1,0) [0|3] "" RXCU
 SG_ ICC_RegenerateLevelCtrl : 98|3@0+ (1,0) [0|7] "" RXCU
 SG_ ICC_SinglePedalMem : 100|2@0+ (1,0) [0|3] "" RXCU
 SG_ ICC_FuelDetnSwt : 102|2@0+ (1,0) [0|3] "" RXCU
 SG_ ICC_FuelDetnState : 105|2@0+ (1,0) [0|3] "" RXCU
 SG_ ICC_FuelDetnOpDefeated : 107|2@0+ (1,0) [0|3] "" RXCU
 SG_ ICC_HVDownRepairMode : 109|2@0+ (1,0) [0|3] "" RXCU
 SG_ ICC_UTURNSnowSet : 111|2@0+ (1,0) [0|3] "" RXCU
 SG_ ICC_UTURNSandSet : 113|2@0+ (1,0) [0|3] "" RXCU
 SG_ ICC_UTURNMudSet : 115|2@0+ (1,0) [0|3] "" RXCU
 SG_ ICC_UTURNGrassSet : 117|2@0+ (1,0) [0|3] "" RXCU
 SG_ ICC_DeepSnowSet_48Fh : 121|2@0+ (1,0) [0|3] "" RXCU
 SG_ ICC_LTCDispSet2 : 124|2@0+ (1,0) [0|3] "" RXCU
 SG_ ICC_SetSocManage : 127|3@0+ (1,0) [0|7] "" RXCU
 SG_ ICC_WadeModeSet_48Fh : 146|3@0+ (1,0) [0|7] "" RXCU
 SG_ ICC_LightSandSet_48Fh : 149|2@0+ (1,0) [0|3] "" RXCU

CM_ BO_ 745 "该报文为5.1平台上捷途申请";
CM_ BO_ 991 "VCU测试报文";
CM_ BO_ 1043 "LIN转CAN";
CM_ BO_ 1117 "捷途新增（WPTC发）";
CM_ BO_ 1122 "捷途新增(WPTC发)";
CM_ BO_ 1167 "捷途新增ID开始";
CM_ SG_ 258 BMS_1_CRC1 "Profile1A:E2E CRC (SAE J1850 CRC-8) for 8 Bytes
DataID:0x0014";
CM_ SG_ 258 BMS_1_RollgCntr1 "Profile1A:E2E Rolling message counter(the maximum value of Alive counter is 14)";
CM_ SG_ 258 BMS_1_Resd1 "Profile1A:E2E Reserved";
CM_ SG_ 258 BMS_PackVoltage "电池包电压（实际电压）
Battery Voltage";
CM_ SG_ 258 BMS_PackCurrent "电池包电流
Baattery Current(direction:discharge+ charge -)";
CM_ SG_ 258 BMS_HvBattSts "BMS实际状态
Battery State
拆帧至GL 网段
ID 0x397(FLZCU_16)20-23Bit";
CM_ SG_ 258 BMS_SysSelfCheck "系统自检
BMS Self Check State";
CM_ SG_ 258 BMS_HVBattThermRunaway "热失控
Thermal Run-away
拆帧至ID 0x397(FLZCU_16)18-19Bit";
CM_ SG_ 258 BMS_1_CRC2 "Profile1A:E2E CRC (SAE J1850 CRC-8) for 8 Bytes
DataID:No ASIL requirements.Not configure
CRC Reserved.";
CM_ SG_ 258 BMS_1_RollgCntr2 "Profile1A:E2E Rolling message counter(the maximum value of Alive counter is 14)";
CM_ SG_ 258 BMS_1_Resd2 "Profile1A:E2E Reserved";
CM_ SG_ 258 BMS_ChargeVoltageReq "充电请求电压（快充）
Chagre Voltage Request indiction(only for BMS internal analysis)";
CM_ SG_ 258 BMS_ChgCurrReq "充电请求电流（快充）
Chagre Current Request t indiction(only for BMS internal analysis)";
CM_ SG_ 258 BMS_InfraDcUActDc "快充桩的实际输出电压
DC-charge station actual ouput voltage(only for BMS internal analysis)";
CM_ SG_ 258 BMS_1_CRC3 "Profile1A:E2E CRC (SAE J1850 CRC-8) for 8 Bytes
DataID:0x0015";
CM_ SG_ 258 BMS_1_RollgCntr3 "Profile1A:E2E Rolling message counter(the maximum value of Alive counter is 14)";
CM_ SG_ 258 BMS_1_Resd3 "Profile1A:E2E Reserved";
CM_ SG_ 258 BMS_InfraDcIActDc "快充桩的实际输出电流
DC-charge station actual ouput current(only for BMS internal analysis)";
CM_ SG_ 258 BMS_HvBattDynChrgnILim "最大允许充电电流（快慢充共用）
battery chagre current limit";
CM_ SG_ 258 BMS_HvBattUChrgnLim "最大允许充电电压（快慢充共用）
battery chagre voltage limit";
CM_ SG_ 258 BMS_1_CRC4 "Profile1A:E2E CRC (SAE J1850 CRC-8) for 8 Bytes
DataID:0x0016";
CM_ SG_ 258 BMS_1_RollgCntr4 "Profile1A:E2E Rolling message counter(the maximum value of Alive counter is 14)";
CM_ SG_ 258 BMS_1_Resd4 "Profile1A:E2E Reserved";
CM_ SG_ 258 BMS_ChrgDcIAvl "桩最大输出电流
DC-charge station charging current limit";
CM_ SG_ 258 BMS_DChrgAPlusSt "A+状态  边沿检测
DC A+ status";
CM_ SG_ 258 BMS_Insulation_R "绝缘阻值(取双边中较小值)
insulation resistance";
CM_ SG_ 258 BMS_ChrgDcCnctrDetd "CC2连接状态
CC2 connect state
拆帧至DK 网段ID 0x4E9(FLZCU_28)14-15Bit";
CM_ SG_ 258 BMS_DCChgMode "快充模式
DC charge mode
0x0:Default 默认值
0x1:HandOver 握手
0x2:ParaConfig充电配置
0x3:Chging充电中
0x4:ChgEnd充电结束
0x5:ChgWaring充电警告
0x6:ChgFault充电错误
CATL无0x5状态，可以不进行配置。";
CM_ SG_ 258 BMS_ChrgDcChrgnFltStopReas "Dc charge stop reason";
CM_ SG_ 258 BMS_1_CRC5 "Profile1A:E2E CRC (SAE J1850 CRC-8) for 8 Bytes
DataID:0x0017";
CM_ SG_ 258 BMS_1_RollgCntr5 "Profile1A:E2E Rolling message counter(the maximum value of Alive counter is 14)";
CM_ SG_ 258 BMS_1_Resd5 "Profile1A:E2E Reserved";
CM_ SG_ 258 BMS_ChgRemTime "剩余充电时间
remain charging time
BMS以实际充电电流进行测算剩余充电时间，快慢充共用信号。充电状态发正常计算值，非充电状态发0。";
CM_ SG_ 258 BMS_ChargeRequest_Mode "充电模式请求
charge request mode
0x0:没有请求
0x1: 慢充请求
0x2:升压模式请求
0x3:快充请求
0x4:充电预充请求
0x5~0xE:Reserved预留
0xF:init无效值
快充与慢充流程需使用该信号
0x2，0x4，0xF无定义";
CM_ SG_ 258 BMS_StateOfEnergy "电池SOEbattery SOE";
CM_ SG_ 258 BMS_1_CRC6 "Profile1A:E2E CRC (SAE J1850 CRC-8) for 8 Bytes
DataID:0x0018";
CM_ SG_ 258 BMS_1_RollgCntr6 "Profile1A:E2E Rolling message counter(the maximum value of Alive counter is 14)";
CM_ SG_ 258 BMS_1_Resd6 "Profile1A:E2E Reserved";
CM_ SG_ 258 BMS_StateOfHealth "电池SOH
battery SOH
0x7E: Error
0x7F: Init";
CM_ SG_ 258 BMS_BlanceState "电池均衡状态
battery balance state";
CM_ SG_ 258 BMS_IsolationFault "电池绝缘故障
battery insulation fault state";
CM_ SG_ 258 BMS_HVILFault_DC "DC internal HVIL fault
捷途使用该信号发送BMS电池包内部高压互锁故障状态";
CM_ SG_ 258 BMS_SOCDis "发送显示SOC
battery indication SOC";
CM_ SG_ 258 BMS_InfraDcIActDcMin "桩最小输出电流
DC-charge station actual ouput current(only for BMS internal analysis)";
CM_ SG_ 369 VCU_1_CRC1 "Profile1A:E2E CRC (SAE J1850 CRC-8) for 8 Bytes
DataID:0x005E";
CM_ SG_ 369 VCU_1_RollgCntr1 "Profile1A:E2E Rolling message counter(the maximum value of Alive counter is 14)";
CM_ SG_ 369 VCU_1_Resd1 "Profile1A:E2E Reserved";
CM_ SG_ 369 VCU_BMSPreheatKeepWarmAllow "Preheating and Keep warm request from VCU";
CM_ SG_ 369 VCU_BMSAcChrgPerm "VCU enable AC charge";
CM_ SG_ 369 VCU_BMSStsReq_Reserved "VCU request BMS sates";
CM_ SG_ 369 VCU_ElectronicLockReq "ElectronicLockReq";
CM_ SG_ 369 VCU_ErrLvl "Error Level";
CM_ SG_ 369 VCU_PwtCoolingLvl_171h "electric drive Cooling level";
CM_ SG_ 369 HCU_BMSVehDcChrgnIDmd_171h "Fast chagring current request（battery power limitation and accessary comsumption）";
CM_ SG_ 385 VCU_2_CRC1 "Profile1A:E2E CRC (SAE J1850 CRC-8) for 8 Bytes
DataID:0x005F";
CM_ SG_ 385 VCU_2_RollgCntr1 "Profile1A:E2E Rolling message counter(the maximum value of Alive counter is 14)";
CM_ SG_ 385 VCU_2_Resd1 "Profile1A:E2E Reserved";
CM_ SG_ 385 VCU_BMSVehDcChrgnIDmd "Fast chagring current request（battery power limitation and accessary comsumption）";
CM_ SG_ 385 VCU_BMSHVreq "Battery Main Cycle Rely connection request from  VCU";
CM_ SG_ 385 VCU_BMSVehDcChrgnUDmd "Fast chagring voltage request（battery power limitation and accessary comsumption）";
CM_ SG_ 385 VCU_TargetSOC "VCU target SOC";
CM_ SG_ 385 VCU_BMSDcChrgPerm "VCU enable DC charge";
CM_ SG_ 401 VCU_3_CRC1 "Profile1A:E2E CRC (SAE J1850 CRC-8) for 8 Bytes
DataID:0x0060";
CM_ SG_ 401 VCU_3_RollgCntr1 "Profile1A:E2E Rolling message counter(the maximum value of Alive counter is 14)";
CM_ SG_ 401 VCU_3_Resd1 "Profile1A:E2E Reserved";
CM_ SG_ 401 VCU_DCDCVoltageSetPoint "DCDC output voltage set";
CM_ SG_ 401 VCU_DCDCPwrLimit "Maximum Power limit for DCDC（股份为12个Bit,捷途调整为14个BIt）";
CM_ SG_ 513 MFSL_UP_SW "上调节开关";
CM_ SG_ 513 MFSL_DW_SW "下调节开关";
CM_ SG_ 513 MFSL_OK_SW "确认";
CM_ SG_ 515 EVCC_1_CRC1 "Profile1A:E2E CRC (SAE J1850 CRC-8) for 8 Bytes
DataID:0x007B";
CM_ SG_ 515 EVCC_1_RollgCntr1 "Profile1A:E2E Rolling message counter(the maximum value of Alive counter is 14)";
CM_ SG_ 515 EVCC_1_Resd1 "Profile1A:E2E Reserved";
CM_ SG_ 515 EVCC_GunConnectSt_203h "充电枪连接状态
0-未连接
1-已连接
2-连接异常";
CM_ SG_ 515 EVCC_COUNTRY_SUPPORT "欧标美标充电支持";
CM_ SG_ 515 EVCC_CP_DutyCycleFault "CP pwm fault";
CM_ SG_ 515 EVCC_CC_ConnectSts "CC连接状态
 0x0:CC未连接
0x1:CC已连接
0x2:CC半连接
0x3:无效";
CM_ SG_ 515 EVCC_S2Swtsts "S2状态
0-断开，1-闭合";
CM_ SG_ 515 EVCC_CPSts "CP类型";
CM_ SG_ 515 EVCC_ChargeType "充电类型
1-交流基础信号充电
2-15118交流充电
3-15118直流充电
4-70121直流充电
5-交流放电";
CM_ SG_ 515 EVCC_CC2_Alarm "CC2连接故障
0x0:无故障
0x1:有故障";
CM_ SG_ 515 EVCC_CC2_ConnectSts "CC2 connect state";
CM_ SG_ 515 EVCC_CC_ConnectDischarSts "V2L 放电枪connect states
0x0:CC未连接
0x1:CC已连接
0x2:CC半连接
0x3:无效";
CM_ SG_ 515 EVCC_1_CRC2 "Profile1A:E2E CRC (SAE J1850 CRC-8) for 8 Bytes
DataID:0x007C";
CM_ SG_ 515 EVCC_1_RollgCntr2 "Profile1A:E2E Rolling message counter(the maximum value of Alive counter is 14)";
CM_ SG_ 515 EVCC_1_Resd2 "Profile1A:E2E Reserved";
CM_ SG_ 515 EVCC_CPMaxVolt "charger CP MaxVolt value";
CM_ SG_ 515 EVCC_FaultLevel "故障等级";
CM_ SG_ 515 EVCC_DCPlusTemp "DC+ temperature";
CM_ SG_ 515 EVCC_DCMinusTemp "DC-temperature";
CM_ SG_ 515 EVCC_TotalFaultNum "故障数";
CM_ SG_ 515 EVCC_FaultNum1 "故障代码";
CM_ SG_ 515 EVCC_FaultNum2 "故障代码";
CM_ SG_ 520 BMS_2_CRC1 "Profile1A:E2E CRC (SAE J1850 CRC-8) for 8 Bytes
DataID:0x007E";
CM_ SG_ 520 BMS_2_RollgCntr1 "Profile1A:E2E Rolling message counter(the maximum value of Alive counter is 14)";
CM_ SG_ 520 BMS_2_Resd1 "Profile1A:E2E Reserved";
CM_ SG_ 520 BMS_C2Target_Chg_Voltage "BMS_C2Target_Chg_Voltage";
CM_ SG_ 520 BMS_CHGstation_MAXPwr "快充桩最大输出功率
BMS_CHGstation_MAXPwr";
CM_ SG_ 520 BMS_2_CRC2 "Profile1A:E2E CRC (SAE J1850 CRC-8) for 8 Bytes
DataID:0x0019";
CM_ SG_ 520 BMS_2_RollgCntr2 "Profile1A:E2E Rolling message counter(the maximum value of Alive counter is 14)";
CM_ SG_ 520 BMS_2_Resd2 "Profile1A:E2E Reserved";
CM_ SG_ 520 BMS_HvBattThermReqLevel "拆帧至GL CAN 0x397(bit32)";
CM_ SG_ 520 BMS_NV_relay_Sts "上报主负继电器状态
Main NEG Rely State";
CM_ SG_ 520 BMS_PV_relay_Sts "上报主正继电器状态
Main POS Rely State";
CM_ SG_ 520 BMS_QCP_relay_Sts "上报充正继电器状态
DC-CHG POS Rely State";
CM_ SG_ 520 BMS_QCN_relay_Sts "上报充负继电器状态
DC-CHG NEG Rely State";
CM_ SG_ 520 BMS_Prechage_relay_Sts "上报预充继电器状态
Pre-Charge Rely State";
CM_ SG_ 520 BMS_HvBattThermReqMode "电池热管理请求
Battery Thermal Management Request
拆帧至GL网段 (ID 0x397)Bit36-39";
CM_ SG_ 520 BMS_ClntTHvBattIn "battery inlet temperature
拆帧至GL网段 (ID 0x397)Bit40-47";
CM_ SG_ 520 BMS_ClntTHvBattOut "battery oulet temperature
拆帧至GL网段 (ID 0x397)Bit48-55";
CM_ SG_ 520 BMS_HvBattClntInTReq "电池进水口温度请求
battery inlet teperature request
拆帧至GL网段 (ID 0x397)Bit56-62";
CM_ SG_ 520 BMS_2_CRC3 "Profile1A:E2E CRC (SAE J1850 CRC-8) for 8 Bytes
DataID:0x001A";
CM_ SG_ 520 BMS_2_RollgCntr3 "Profile1A:E2E Rolling message counter(the maximum value of Alive counter is 14)";
CM_ SG_ 520 BMS_2_Resd3 "Profile1A:E2E Reserved";
CM_ SG_ 520 BMS_HvBattClntFlowReq "流量请求water flow request
拆帧至GL网段 (ID 0x397)Bit80-86";
CM_ SG_ 520 BMS_HvBattAvgT "电池平均温度battery average temperature
拆帧至GL网段 (ID 0x397)Bit88-95";
CM_ SG_ 520 BMS_HvBattMaxT "电池最高温度battery max temperature
发送逻辑做如下处理：
当温度值>=0，则CAN发送至向上取整（例如内部温度19.5℃则发送20℃)
当温度值<0，则CAN发送至向下取整（例如内部温度是-19.5℃则发送-20℃）
拆帧至GL网段 (ID 0x397)Bit96-103";
CM_ SG_ 520 BMS_HvBattMinT "电池最低温度battery min temperature
定义：电池最低温度  ，发送逻辑做如下处理：
当温度值>=0，则CAN发送至向上取整（例如内部温度19.5℃则发送20℃）
当温度值<0，则CAN发送至向下取整（例如内部温度是-19.5℃则发送-20℃）
拆帧至GL网段 (ID 0x397)Bit104-111";
CM_ SG_ 520 BMS_HvBattTdiff "电池温差battery temperature differences
0x7E: Init
0x7F: Error";
CM_ SG_ 520 BMS_2_CRC4 "Profile1A:E2E CRC (SAE J1850 CRC-8) for 8 Bytes
DataID:0x001B";
CM_ SG_ 520 BMS_2_RollgCntr4 "Profile1A:E2E Rolling message counter(the maximum value of Alive counter is 14)";
CM_ SG_ 520 BMS_2_Resd4 "Profile1A:E2E Reserved";
CM_ SG_ 520 BMS_OutPosU "主正继电器外侧电压对主负继电器内侧电压
POS Mian-rely outside voltage";
CM_ SG_ 520 BMS_OutNegU "主负继电器外侧电压对主正继电器外侧电压
NEG Mian-rely outside voltage";
CM_ SG_ 520 BMS_2_CRC5 "Profile1A:E2E CRC (SAE J1850 CRC-8) for 8 Bytes
DataID:0x001C";
CM_ SG_ 520 BMS_2_RollgCntr5 "Profile1A:E2E Rolling message counter(the maximum value of Alive counter is 14)";
CM_ SG_ 520 BMS_2_Resd5 "Profile1A:E2E Reserved";
CM_ SG_ 520 BMS_outQCPosU "快充正继电器外侧电压对主负继电器内侧电压
POS DC rely outside voltage";
CM_ SG_ 520 BMS_outQCNegU "快充负继电器外侧电压对主正继电器外侧电压
NEG DC rely outside voltage";
CM_ SG_ 520 BMS_Middlesplit_relay_Sts "Middlesplit Rely State";
CM_ SG_ 523 BMS_3_CRC1 "Profile1A:E2E CRC (SAE J1850 CRC-8) for 8 Bytes
DataID:0x001D";
CM_ SG_ 523 BMS_3_RollgCntr1 "Profile1A:E2E Rolling message counter(the maximum value of Alive counter is 14)";
CM_ SG_ 523 BMS_3_Resd1 "Profile1A:E2E Reserved";
CM_ SG_ 523 BMS_HvBattPMaxReChrgLim "BMS max recharge power (10s)";
CM_ SG_ 523 BMS_3_CRC2 "Profile1A:E2E CRC (SAE J1850 CRC-8) for 8 Bytes
DataID:0x001E";
CM_ SG_ 523 BMS_3_RollgCntr2 "Profile1A:E2E Rolling message counter(the maximum value of Alive counter is 14)";
CM_ SG_ 523 BMS_3_Resd2 "Profile1A:E2E Reserved";
CM_ SG_ 523 BMS_HvBattIMaxReChrgLim "BMS max recharge current  (10s)
0x7FE: Error
0x7FF: Init";
CM_ SG_ 523 BMS_HvBattPMaxDchaLim "BMS max discharge power (10s)";
CM_ SG_ 523 BMS_3_CRC3 "Profile1A:E2E CRC (SAE J1850 CRC-8) for 8 Bytes
DataID:0x001F";
CM_ SG_ 523 BMS_3_RollgCntr3 "Profile1A:E2E Rolling message counter(the maximum value of Alive counter is 14)";
CM_ SG_ 523 BMS_3_Resd3 "Profile1A:E2E Reserved";
CM_ SG_ 523 BMS_HvBattIMaxDchaLim "BMS max discharge current (10s)
0x7FE: Error";
CM_ SG_ 523 BMS_3_CRC4 "Profile1A:E2E CRC (SAE J1850 CRC-8) for 8 Bytes
DataID:No ASIL requirements.Not configure
CRC Reserved.";
CM_ SG_ 523 BMS_3_RollgCntr4 "Profile1A:E2E Rolling message counter(the maximum value of Alive counter is 14)";
CM_ SG_ 523 BMS_3_Resd4 "Profile1A:E2E Reserved";
CM_ SG_ 523 BMS_3_CRC5 "Profile1A:E2E CRC (SAE J1850 CRC-8) for 8 Bytes
DataID:0x0020";
CM_ SG_ 523 BMS_3_RollgCntr5 "Profile1A:E2E Rolling message counter(the maximum value of Alive counter is 14)";
CM_ SG_ 523 BMS_3_Resd5 "Profile1A:E2E Reserved";
CM_ SG_ 523 BMS_KL30Volt "KL30电压12V voltage";
CM_ SG_ 523 BMS_kL87Volt "继电器驱动电压KL87 voltage";
CM_ SG_ 523 BMS_HvBattUDchaLim "pack总电压截止电压lowest discharge voltage limitation";
CM_ SG_ 523 BMS_3_CRC6 "Profile1A:E2E CRC (SAE J1850 CRC-8) for 8 Bytes
DataID:No ASIL requirements.Not configure
CRC Reserved.";
CM_ SG_ 523 BMS_3_RollgCntr6 "Profile1A:E2E Rolling message counter(the maximum value of Alive counter is 14)";
CM_ SG_ 523 BMS_3_Resd6 "Profile1A:E2E Reserved";
CM_ SG_ 523 BMSH_MaxChgPwrPeak "Maximum Charge Power Peak
拆帧至IC CAN 0x3FC（bit52）";
CM_ SG_ 523 BMSH_MaxDchgPwrPeak "Maximum Discharge Power Peak
拆帧至IC CAN 0x3FC（bit56）";
CM_ SG_ 563 VCU_6_G_CRC "Profile1A:E2E CRC (SAE J1850 CRC-8) for 8 Bytes
DataID:No ASIL requirements.Not configure
CRC Reserved.";
CM_ SG_ 563 VCU_6_G_RollgCntr "Profile1A:E2E Rolling message counter(the maximum value of Alive counter is 14)";
CM_ SG_ 563 VCU_6_G_Resd "Profile1A:E2E Reserved";
CM_ SG_ 563 VCU_6_G_GasPedalPosition "Driver/Cruise control
This signal including compositive informations which are actual gas pedal position and dummy Cruise control gas pedal position";
CM_ SG_ 563 VCU_6_G_PRNDGearAct "Gear indication";
CM_ SG_ 638 FRZCU_HoodSts "前舱盖状态
源头FRZCU_HoodSts";
CM_ SG_ 644 ICM_5_FuelLevel_284h "国六项目EMS收，滤波后的燃油液位信息";
CM_ SG_ 683 PassDoorSts_2ABh "副驾门状态
RHFDoorSts";
CM_ SG_ 683 PassRearDoorSts_2ABh "副驾后门状态
RHRDoorSts";
CM_ SG_ 745 DCB_1_HVILSts "高压互锁状态";
CM_ SG_ 745 DCB_1_BoostNegRelaySts "升压负极接触器状态(K5)";
CM_ SG_ 745 DCB_1_WorkingSts "DCB工作状态";
CM_ SG_ 745 DCB_1_NegFastChgRelaySts "快充负极接触器状态(K7)";
CM_ SG_ 745 DCB_1_C2RelaySts "C2电容接触器状态";
CM_ SG_ 745 DCB_1_ErrorLevel "故障等级";
CM_ SG_ 745 DCB_1_PosFastChgRelaySts "快充正极接触器状态(K8)";
CM_ SG_ 745 DCB_1_ChrgDerate "充电降额百分比";
CM_ SG_ 745 DCB_1_C2RearVolt "C2电容后端电压";
CM_ SG_ 745 DCB_1_InputVolt "DCB输入母线电压";
CM_ SG_ 745 DCB_1_BoostNegFrontVolt "升压负极接触器前端电压";
CM_ SG_ 745 DCB_1_NegFastChgFrontVolt "快充负极接触电器前端电压";
CM_ SG_ 745 DCB_1_BoostPosFastChgRearVolt "快充正极接触电器后端电压";
CM_ SG_ 745 DCB_1_BoostPosRelaySts "升压正极接触器状态（K6）";
CM_ SG_ 789 ATCM_DriveModeSw "驾驶模式状态
";
CM_ SG_ 789 ATCM_XModeSw "X模式状态";
CM_ SG_ 789 ATCM_PowerModeSw "动力模式
";
CM_ SG_ 789 ACTM_4LModeSW "低速四驱
";
CM_ SG_ 789 ATCM_CCOSwtReq "蠕行模式
";
CM_ SG_ 789 ATCM_SwitchUTurnModeSet "极限掉头开关/坦克掉头
";
CM_ SG_ 789 ATCM_FrontEDL "前差速锁
";
CM_ SG_ 789 ATCM_RearEDL "后差速锁";
CM_ SG_ 789 ATCM_ASU_LiftSet "悬架升高";
CM_ SG_ 789 ATCM_ASU_LowerSet "悬架降低";
CM_ SG_ 789 ATCM_TABSwtReq "TAB开关";
CM_ SG_ 789 ATCM_EngyRec_SW "能量回收开关信号";
CM_ SG_ 859 FLZCU_IRCHV_Req "高压上下电";
CM_ SG_ 991 ErrorLevel "Error_Level
故障等级";
CM_ SG_ 991 TMS_HV_Req "Request_VCU_Ready
请求VCU上高压";
CM_ SG_ 991 TMS_EngingstartReq "Enging_Start_Request
发动机启动请求";
CM_ SG_ 1024 FRZCU_OnekeyHVoffSwtst "紧急下电开关状态反馈（法规要求，执行下高压，低压不变）";
CM_ SG_ 1029 LBMS_PackExtU "Pack电压(MOS外侧电压)";
CM_ SG_ 1029 LBMS_PackT1 "Pack温度1";
CM_ SG_ 1029 LBMS_PackExtUVld "Pack电压是否有效";
CM_ SG_ 1029 LBMS_PackT2 "Pack温度2";
CM_ SG_ 1029 LBMS_PackT3 "Pack温度3";
CM_ SG_ 1029 LBMS_PackTVld "Pack温度是否有效";
CM_ SG_ 1034 HCU_1_G_CRC1 "Profile1A:E2E CRC (SAE J1850 CRC-8) for 8 Bytes
DataID:0x009A";
CM_ SG_ 1034 HCU_1_G_RollgCntr1 "Profile1A:E2E Rolling message counter(the maximum value of Alive counter is 14)";
CM_ SG_ 1034 HCU_1_G_Resd1 "Profile1A:E2E Reserved";
CM_ SG_ 1034 HCU_EmPwr "E-Motor power indication";
CM_ SG_ 1034 HCU_PwrTrnModeDisp "Powertrain mode for displaying energy flow";
CM_ SG_ 1034 HCU_IntelligentPowerSupply "Intelligent Power Supply For small battery";
CM_ SG_ 1034 HCU_PowerModeFed "Power mode Feedback";
CM_ SG_ 1034 HCU_LimpHomeMode "HCU sends limphome function indication to ICM   REEV Only, for dual-clutch problem";
CM_ SG_ 1034 HCU_PowertrainFault "Powertrain fault";
CM_ SG_ 1034 HCU_PowerModeChangeFail "(Once triggered,send 5 frames 'Active 'immediately, then send 'No active')";
CM_ SG_ 1034 BMSH_MILReq "0x40A MIL request";
CM_ SG_ 1034 TMF_EngMilLampReq "MIL lamp on request(TMF)";
CM_ SG_ 1034 TMR_EngMilLampReq "MIL lamp on request(TMR)";
CM_ SG_ 1034 HCU_MILReq "MIL lamp on request(HCU)";
CM_ SG_ 1034 HCU_HVReady "HV Ready indication";
CM_ SG_ 1034 HCU_PTReady "Drive Ready indication";
CM_ SG_ 1034 HCU_ChargingSts "charge status";
CM_ SG_ 1034 HCU_PtSts "动力运行状态";
CM_ SG_ 1034 HCU_InHbStrtRes "禁止启动的原因";
CM_ SG_ 1035 VCC_1_OTASts "OTA status";
CM_ SG_ 1038 LBMS_SOC "SOC";
CM_ SG_ 1038 LBMS_ReChrgReq "低压蓄电池补电请求";
CM_ SG_ 1038 LBMS_ReqChrgU "充电请求电压";
CM_ SG_ 1039 LBMS_ChargeSts "智能补电状态";
CM_ SG_ 1039 LBMS_ChargeFlt "存在充电故障或断充放电MOS故障，则发1";
CM_ SG_ 1039 LBMS_ChargeEnable "智能补电使能";
CM_ SG_ 1043 EBS_U_BATT "Current measured battery voltage, max value is 18V.Invalid Raw Value:16383.";
CM_ SG_ 1044 HCU_RangeAval "Range Available";
CM_ SG_ 1044 HCU_EnergyFlow "Energy Flow（股份信号D01不使用)";
CM_ SG_ 1044 HCU_ReplaceWarmupCycle "Replace warm-up cycle 替代暖机循环（股份信号D01不使用)";
CM_ SG_ 1044 HCU_CLMOBDClearReq "Mode $04 clear OBD information request flag
当有$04 清故障码服务时，HCU周期发送0x1 Request，当收到CLM反馈的清故障码状态完成时，再发0x0 No Request（股份信号D01不使用)";
CM_ SG_ 1044 HCU_2_G_ChgIncOper "Charge Increasing Operation";
CM_ SG_ 1044 HCU_2_G_ChgDepOper "Charge Depleting Operation";
CM_ SG_ 1044 HCU_SocManageFed_414h "Soc Manage Feedback（股份信号D01不使用)";
CM_ SG_ 1044 HCU_SetSOCFed "Set SOC Feedback";
CM_ SG_ 1044 HCU_EnergyFlowREEV "REEV Energy Flow增程器能量流";
CM_ SG_ 1044 HCU_EmissionDetection "排放检测模式状态";
CM_ SG_ 1044 HCU_2_G_IntrptGpfRgtvSt "Interrupt GPF Regenerativestate";
CM_ SG_ 1044 HCU_2_G_LowBatteryInfo "0x1:No Request  无需显示
0x2:Request  弹窗提示动力电池电量过低，请立即插枪充电或切换到Ready充电（股份信号D01不使用)
0x3:Sail Request 航行模式下的低电量提示";
CM_ SG_ 1044 HCU_2_G_LowBatteryLowFuelInfo "No Request 无需显示
Request 弹窗提示“油量电量均过低，请立即加油或充电”（股份信号D01不使用)";
CM_ SG_ 1044 HCU_2_G_HighTempLimit "未限速
高温限速（股份信号D01不使用)";
CM_ SG_ 1055 BMS_4_CRC1 "Profile1A:E2E CRC (SAE J1850 CRC-8) for 8 Bytes
DataID:No ASIL requirements.Not configure
CRC Reserved.";
CM_ SG_ 1055 BMS_4_RollgCntr1 "Profile1A:E2E Rolling message counter(the maximum value of Alive counter is 14)";
CM_ SG_ 1055 BMS_4_Resd1 "Profile1A:E2E Reserved";
CM_ SG_ 1055 BMS_ErrorNumber "故障数（当前存在故障的数目）
BMS Error Numbers";
CM_ SG_ 1055 BMS_ErrorCode "BMS Error Code
BMS故障代码（内部故障）
若有多个故障，轮询发送。若故障触发后恢复，该故障信号还是需要发出。";
CM_ SG_ 1055 BMS_4_CRC2 "Profile1A:E2E CRC (SAE J1850 CRC-8) for 8 Bytes
DataID:0x0021";
CM_ SG_ 1055 BMS_4_RollgCntr2 "Profile1A:E2E Rolling message counter(the maximum value of Alive counter is 14)";
CM_ SG_ 1055 BMS_4_Resd2 "Profile1A:E2E Reserved";
CM_ SG_ 1055 BMSH_MILReq_41Fh "MIL request";
CM_ SG_ 1055 BMS_HvBattUnderTemperature "battery under temperature flag
当最低模组温度小于-30℃时该信号置1，最低模组温度大于等于-29℃时该信号置0；
Note：
1、所有温度都无效时，该信号维持上一时刻值；
2、-29℃到-30℃之间该信号维持上一状态；";
CM_ SG_ 1055 BMS_ErrorLevel "故障等级BMS Error Levels";
CM_ SG_ 1055 BMS_ThermRunCode "热失控原因编码
thermal runaway reason flag
将热失控诊断方案，即触发热失控的组合条件编码发送到这个信号。
发送诊断热失控组合条件编码对应的CaseMask（ScTRDM_ThermalRunawayFltCaseMask）的bit号，bit0置1则发1，bit1置1则发2，.......bit30置1则发31，最大发31。";
CM_ SG_ 1055 BMS_DChrgEndCode "DC charge end reason flag
快慢充共用，按平台内部充电停止原因编码发送。";
CM_ SG_ 1055 BMS_PwrDerateFlg "BMS功率闭环策略限功率标志位";
CM_ SG_ 1057 VCU_shfChk "上报N档文字提醒信息";
CM_ SG_ 1057 VCU_PowerLimitSOCLow "上报低电量提醒信息";
CM_ SG_ 1057 VCU_MCU_MilLampReq "上报防盗认证提醒信息";
CM_ SG_ 1057 VCU_OPDinfo "上报单踏板退出信息";
CM_ SG_ 1057 VCU_ePTDrvPowerPcent "上报功率占比信息";
CM_ SG_ 1057 VCU_TowingMode "上报拖车模式提醒信息";
CM_ SG_ 1057 VCU_EgyRegenLevelHighAllowed "强回收按钮是否可用";
CM_ SG_ 1057 VCU_SportDriveModeAvailable "运动驾驶模式是否可用";
CM_ SG_ 1057 VCU_RainSnowDriveModeAvailable "雨雪驾驶模式是否可用";
CM_ SG_ 1057 VCU_OffRoadDriveModeAvailable "越野模式是否可用";
CM_ SG_ 1057 VCU_CampAvailable "露营模式可用状态";
CM_ SG_ 1057 VCU_DisChgSOCHighLim "提供整车对外放电SOC调节上限";
CM_ SG_ 1057 VCU_DisChgSOCLowLim "提供整车对外放电SOC调节下限";
CM_ SG_ 1057 VCU_ChgSocSetFed "SOC设置反馈";
CM_ SG_ 1057 VCU_EngyConsuPer10Km "最近行驶10Km换算的平均百公里电耗";
CM_ SG_ 1057 VCU_EngyConsuPer25Km "最近行驶25Km换算的平均百公里电耗";
CM_ SG_ 1057 VCU_EngyConsuPer50Km "最近行驶50Km换算的平均百公里电耗";
CM_ SG_ 1057 VCU_EngyConsuPer100m "最近行驶100m换算的平均百公里电耗";
CM_ SG_ 1057 VCU_DisChrgPwr "对外供电功率";
CM_ SG_ 1057 VCU_BookChrgSetFailRes "预约失败原因反馈";
CM_ SG_ 1057 VCU_BookChrgFailRes "无法进入预约充电原因反馈";
CM_ SG_ 1057 VCU_HVILFault "高压互锁状态";
CM_ SG_ 1057 VCUExtendRang "极致节能模式增加里程值";
CM_ SG_ 1057 VCU_KeepWarmFailReason "保温失败原因";
CM_ SG_ 1057 VCU_ExtremeEnergySavingModeAv "极致节能模式状态";
CM_ SG_ 1057 VCU_TowModeAvailable "拖车模式是否可用";
CM_ SG_ 1057 VCU_StopModeSWStsResp "停止模式状态开关反馈";
CM_ SG_ 1057 VCU_StopModeSWAllowed "停止模式状态开关是否可用反馈";
CM_ SG_ 1057 VCU_ChgDisChgLedCtrl "车辆充电指示灯控制状态";
CM_ SG_ 1057 VCU_CPMaxVolt "慢充桩CP电压";
CM_ SG_ 1057 VCUExtremeEnergySavingModeReq "极致节能模式请求";
CM_ SG_ 1057 VCU_EpedalModeSts "E-Pedal实际开启/关闭状态";
CM_ SG_ 1057 VCU_BookChrgStsFb "预约充电状态";
CM_ SG_ 1057 VCU_HVNM "高压维持网络";
CM_ SG_ 1057 VCU_DriveMode "Driving modes";
CM_ SG_ 1057 HCU_EnterForceEVFailRes "不允许进入强制纯电模式原因";
CM_ SG_ 1057 HCU_EngineSelfMaintain "增程发动机自启维护";
CM_ SG_ 1057 HCU_EnterForceChrgFailRes "不允许进入强制发电模式原因";
CM_ SG_ 1057 HCU_InStartRes "无法启动的原因";
CM_ SG_ 1057 HCU_EnergyRegSetFed "能量回收强度调节设置反馈";
CM_ SG_ 1078 PLG_LatchSts "尾门门锁状态";
CM_ SG_ 1086 VCU_8_CRC1 "Profile1A:E2E CRC (SAE J1850 CRC-8) for 8 Bytes
DataID:0x0067";
CM_ SG_ 1086 VCU_8_RollgCntr1 "Profile1A:E2E Rolling message counter(the maximum value of Alive counter is 14)";
CM_ SG_ 1086 VCU_8_Resd1 "Profile1A:E2E Reserved";
CM_ SG_ 1086 VCU_OBCDischgPwrLimit "VCU request OBC discharge power";
CM_ SG_ 1086 VCU_OBCDischgReq "VCU request OBC discharge";
CM_ SG_ 1086 VCU_8_CRC2 "Profile1A:E2E CRC (SAE J1850 CRC-8) for 8 Bytes
DataID:No ASIL requirements.Not configure
CRC Reserved.";
CM_ SG_ 1086 VCU_8_RollgCntr2 "Profile1A:E2E Rolling message counter(the maximum value of Alive counter is 14)";
CM_ SG_ 1086 VCU_8_Resd2 "Profile1A:E2E Reserved";
CM_ SG_ 1086 VCU_OBCInnerDischgPwrLimit "VCU request OBC Internal discharge power";
CM_ SG_ 1086 VCU_OBCInnerDischgAllow "VCU Internal discharge allow";
CM_ SG_ 1086 VCU_CLMSystemPowerLimit_43Eh "HVH power limit股份新增该信号
T1J FL3/T1YA/G500 PHEV项目不发此信号";
CM_ SG_ 1086 VCU_CLMEACAllow_43Eh "Before?HV?power?off,VCU?will?send?Unable,EAC?will?prepare?for?HV?shut?down股份新增该信号
T1J FL3/T1YA/G500 PHEV项目不发此信号";
CM_ SG_ 1086 VCU_CLMHVHAllow_43Eh "Before?HV?power?off,VCU?will?send?Unable,HVH?will?prepare?for?HV?shut?down股份新增该信号";
CM_ SG_ 1086 VCU_CLMHVReady_43Eh "HV Ready股份新增该信号";
CM_ SG_ 1092 BNCM_11_EVSEConnectSts "BNCM与私有桩连接状态反馈,
BNCM发,VCU收（FLZCU CAN转ETH）";
CM_ SG_ 1096 TMS_ICAstsFed_448h "空调防水执行器状态反馈";
CM_ SG_ 1096 TMS_RemotekeyReq "遥控钥匙开空调请求信号";
CM_ SG_ 1096 TMS_TimedVentilationReq "定时换气功能请求信号";
CM_ SG_ 1111 EAC_HVILSts "压缩机高压互锁故障状态-捷途新增";
CM_ SG_ 1111 EAC_ErrorLevel "故障等级";
CM_ SG_ 1122 PTC_2_HVILSts "PTC高压互锁故障状态";
CM_ SG_ 1127 CDU_1_CRC1 "Profile1A:E2E CRC (SAE J1850 CRC-8) for 8 Bytes
DataID:No ASIL requirements.Not configure
CRC Reserved.";
CM_ SG_ 1127 CDU_1_RollgCntr1 "Profile1A:E2E Rolling message counter(the maximum value of Alive counter is 14)";
CM_ SG_ 1127 CDU_1_Resd1 "Profile1A:E2E Reserved";
CM_ SG_ 1127 DCDC_HvVolt "DCDC input voltage";
CM_ SG_ 1127 DCDC_FaultCode "Fault Code";
CM_ SG_ 1127 CDU_1_CRC2 "Profile1A:E2E CRC (SAE J1850 CRC-8) for 8 Bytes
DataID:0x0025";
CM_ SG_ 1127 CDU_1_RollgCntr2 "Profile1A:E2E Rolling message counter(the maximum value of Alive counter is 14)";
CM_ SG_ 1127 CDU_1_Resd2 "Profile1A:E2E Reserved";
CM_ SG_ 1127 DCDC_LvSideCurr "DCDC output current";
CM_ SG_ 1127 DCDC_OverTemp "DCDC over temperature";
CM_ SG_ 1127 DCDC_LvSideVolt "DCDC output voltage";
CM_ SG_ 1127 DCDC_EnableSts "DCDC enable states feedback";
CM_ SG_ 1127 DCDC_FaultLevelSts "DCDC故障等级状态（捷途新增等级4）";
CM_ SG_ 1127 DCDC_LvSideCurrMax "DCDC output current";
CM_ SG_ 1137 ICC_BookChrgSetReq "预约充电开启/取消设置请求";
CM_ SG_ 1137 ICC_BkChrgStartTimeYear "预约充电开始时间设置-年";
CM_ SG_ 1137 ICC_BkChrgStartTimeDay "预约充电开始时间设置-日";
CM_ SG_ 1137 ICC_BkChrgStartTimeHour "预约充电开始时间设置-时";
CM_ SG_ 1137 ICC_BkChrgStartTimemMin "预约充电开始时间设置-分";
CM_ SG_ 1137 ICC_BkChrgDuration "本地预约充电时长设置";
CM_ SG_ 1137 ICC_BkChrgStartTimeMonth "预约充电开始时间设置-月";
CM_ SG_ 1137 ICC_BkChrgCycleMon "预约充电周期循环_每周一循环";
CM_ SG_ 1137 ICC_StopChrgReq "结束充电请求";
CM_ SG_ 1137 ICC_BkChrgCycleType "本地预约充电周期循环方式";
CM_ SG_ 1137 ICC_BkChrgCycleFri "预约充电周期循环_每周五循环";
CM_ SG_ 1137 ICC_BkChrgCycleThur "预约充电周期循环_每周四循环";
CM_ SG_ 1137 ICC_BkChrgCycleWen "预约充电周期循环_每周三循环";
CM_ SG_ 1137 ICC_BkChrgCycleTues "预约充电周期循环_每周二循环";
CM_ SG_ 1137 ICC_BkChrgCycleSun "预约充电周期循环_每周日循环";
CM_ SG_ 1137 ICC_BkChrgCycleSat "预约充电周期循环_每周六循环";
CM_ SG_ 1137 ICC_KeepWarmStrt "插枪保温开始时间设置-日";
CM_ SG_ 1137 ICC_KeepWarmStrtHour "插枪保温开始时间设置-时";
CM_ SG_ 1137 ICC_KeepWarmStrtMin "插枪保温开始时间设置-分";
CM_ SG_ 1137 ICC_PetmodeFb "宠物模式反馈信号";
CM_ SG_ 1137 ICC_SentinelModeFaultSts "哨兵故障状态（摄像头被遮挡）
0x0:Not Warming
0x1:Artificial occlusion摄像头被人为遮挡
0x2 :Rain and snow cover摄像头被雨雪遮挡";
CM_ SG_ 1137 ICC_SentinelModeWorkingSts "哨兵工作状态
0x0: NoActive，哨兵模式未进入或未激活
0x1: Active，哨兵模式已进入或激活
0x2: LowSOC 动力电池 电量低
0x3:HVNotReady，高压系统未上电
0x4: HVFault，高压系统故障
0x5: MirrorUnFold，后视镜未展开
0x6: CameraFault，摄像头故障
0x7:LowBatVolt，蓄电池电压低
0x8:ICC主机OTA升级安装中";
CM_ SG_ 1137 ICC_SentinelModeSwitchSts "哨兵开关状态";
CM_ SG_ 1137 ICC_SentinelModeExitReason "哨兵模式异常退出原因
0x0: Normal正常
0x1:LowSOC动力电池电量低
0x2:HVNotReady高压系统未上电
0x3:HVFault高压系统故障
0x4:MirrorUnFold后视镜未展开
0x5:CameraFault，摄像头故障
0x6:LowBatVolt蓄电池电压低
0x7:ICC主机OTA升级安装中";
CM_ SG_ 1137 ICC_SentinelModeAlarmSts "哨兵模式报警状态
0x1: Level 1待命
0x2: Level 2警惕
0x3: Level 3警报";
CM_ SG_ 1137 ICC_PetModeWarn_2 "宠物模式异常关闭
0x0:Not Active
0x1:高压电池电量低
0x2:空调异常
0x3:高压异常
0x4:低压电池电量低
0x5:高压电池电量低于15%
0x6:高压电池电量低于12%
0x7:时间过长预警
0x8:车辆充电中
0x9:车辆未设防
0xA:车辆档位为非P档";
CM_ SG_ 1137 ICM_FuelLevel "燃油量";
CM_ SG_ 1137 ICM_AverageVehicleSpeed "平均车速 (仪表计算)";
CM_ SG_ 1137 ICM_DistenceToEmpty_Km "燃油续航里程";
CM_ SG_ 1137 ICM_Maintenance_tips "保养提示（仪表计算，可能上传到平台）";
CM_ SG_ 1137 ICM_FuelLevelFailSts "燃油故障";
CM_ SG_ 1137 ICM_SumTrip "小计里程";
CM_ SG_ 1142 HCU_4_G_AvgFuCns "Avg Fuel Consumption
近50km平均百公里油耗 L/100km";
CM_ SG_ 1142 HCU_4_G_AvgEnergyCns "Avg Energy Consumption
近50km平均百公里能耗 L/100km";
CM_ SG_ 1142 HCU_4_G_EDrvOnly "EDriveOnly";
CM_ SG_ 1142 HCU_4_G_ForcedPrkgChrg "Forced Parking Charge";
CM_ SG_ 1142 HCU_4_G_SumEgyCns "Sum Energy Consumption
自清零后累计百公里能耗 L/100km";
CM_ SG_ 1142 HCU_4_G_EngRunFuCns "Eng Run Fuel Consumption
近100km燃油里程平均油耗 L/100km";
CM_ SG_ 1143 CDU_2_CRC1 "Profile1A:E2E CRC (SAE J1850 CRC-8) for 8 Bytes
DataID:0x0028";
CM_ SG_ 1143 CDU_2_RollgCntr1 "Profile1A:E2E Rolling message counter(the maximum value of Alive counter is 14)";
CM_ SG_ 1143 CDU_2_Resd1 "Profile1A:E2E Reserved";
CM_ SG_ 1143 OBC_CC_ConnectSts "CC connect states";
CM_ SG_ 1143 OBC_InnerDischgReq "Internal discharge request";
CM_ SG_ 1143 CDU_HVILFault "CDU HVIL fault";
CM_ SG_ 1144 ICC_HvBattKeepWarmSet "中控插枪保温开关";
CM_ SG_ 1144 ICC_CarSickRelfModeReq "晕车舒缓模式
触发一次快发三帧有效，之后返回0x0:Not Active";
CM_ SG_ 1144 ICC_HvBattKeepWarmActiveReq "插枪保温开始请求";
CM_ SG_ 1155 ASU_3_LvlAdj_Restriction "禁止高度调节";
CM_ SG_ 1167 ICC_KeyDriveModememory "驾驶模式记忆开关";
CM_ SG_ 1167 ICC_DriveModeSet "大屏越野模式设置
0x1：经济
0x2：标准
0x3：运动
0x4：雪/草地
0x5: 泥地
0x6: 越野
0x7: 沙地
0x8: 岩石
0x9: 专家
0xA: 智能
0xB: 涉水
0xC: 极限掉头
0xD: 漂移
0xE: 拖挂
0xF: 越野竞速
0x10:攀爬";
CM_ SG_ 1167 ICC_DRIFTModeSetReq "通过大屏设置漂移模式灵敏度
0x0：不动作
0x1：入门
0x2：大师
0x3：专家";
CM_ SG_ 1167 ICC_EXPERTEIPBESPSet "关闭牵引力控制系统&车身稳定控制系统（TCS&VDC OFF）
全开（TCS、VDC等与ESP有关功能全部开启）
全关（TCS、VDC及RMI放侧翻、DTC发动机拖滞力矩管理）";
CM_ SG_ 1167 ICC_EXPERTEcoSet "专家模式动力设置柔和模式开关";
CM_ SG_ 1167 ICC_EXPERTNormSet "专家模式动力设置标准模式开关";
CM_ SG_ 1167 ICC_EXPERTSportSet "专家模式动力设置激进模式开关";
CM_ SG_ 1167 ICC_CrossaxisSet "专家模式交叉轴模式设置";
CM_ SG_ 1167 ICC_EXPERTRWDSet "专家模式驱动形式后驱设置";
CM_ SG_ 1167 ICC_EXPERTAWDSet "专家模式驱动形式四驱设置";
CM_ SG_ 1167 ICC_EXPERTAutoSet "专家模式驱动形式Auto设置";
CM_ SG_ 1167 ICC_CLIMBSet "防溜设置开关";
CM_ SG_ 1167 ICC_DriveModeExitSet "越野模式退出开关";
CM_ SG_ 1167 ICC_CCOSwtReq "ICC越野蠕行（CCO）软开关
0x0:Not Active 使能位
0x1:ON 开启
0x2:OFF 关闭";
CM_ SG_ 1167 ICC_TABSwtReq "ICC坦克转向（TAB）软开关
0x0:Not Active 使能位
0x1:ON 开启
0x2:OFF 关闭";
CM_ SG_ 1167 ICC_Confidencelevel "x模式的前端地形感知置信度（可靠度）";
CM_ SG_ 1167 ICC_V2L_IntlDisChg "放电记忆开关";
CM_ SG_ 1167 ICC_ExhibitionModeSwitch "展车模式开关";
CM_ SG_ 1167 ICC_TrailerMode "被拖模式开关";
CM_ SG_ 1167 ICC_V2L_DisChgMem "放电记忆开关";
CM_ SG_ 1167 ICC_DrivePowerDispSet "驱动系统功率显示方式开关";
CM_ SG_ 1167 ICC_WLTC_to_CLTC_Mode "驱动系统功率显示方式开关";
CM_ SG_ 1167 ICC_StopChrgnSwitch "驻车发电开关";
CM_ SG_ 1167 ICC_StopChrgnMode "驻车发电模式开关
0x1:静谧补电
0x2:快速补电";
CM_ SG_ 1167 ICC_RegenerateLevelCtrl "能量回馈设置开关
0x0:无效值
0x1:弱
0x2:强
0x3:中
0x4:单踏板";
CM_ SG_ 1167 ICC_SinglePedalMem "单踏板记忆开关";
CM_ SG_ 1167 ICC_FuelDetnSwt "燃油检测开关";
CM_ SG_ 1167 ICC_FuelDetnState "燃油检测模式状态";
CM_ SG_ 1167 ICC_FuelDetnOpDefeated "燃油检测开启失败提示";
CM_ SG_ 1167 ICC_HVDownRepairMode "断高压维修模式开关";
CM_ SG_ 1167 ICC_UTURNSnowSet "极限调头雪地场景开关";
CM_ SG_ 1167 ICC_UTURNSandSet "极限调头泥地场景开关";
CM_ SG_ 1167 ICC_UTURNMudSet "极限调头沙地场景开关";
CM_ SG_ 1167 ICC_UTURNGrassSet "极限调头草地场景开关";
CM_ SG_ 1167 ICC_DeepSnowSet_48Fh "深雪模式请求";
CM_ SG_ 1167 ICC_LTCDispSet2 "续航里程选择开关显示";
CM_ SG_ 1167 ICC_WadeModeSet_48Fh "ICC航行模式软开关
0x0:未使能
0x1:陆地模式开启
0x2:涉水状态开启
0x3:航行状态开启
0x4:上滩状态开启
0x5:应急浮水状态开启
0x6~0x7:预留";
CM_ SG_ 1167 ICC_LightSandSet_48Fh "0x0:Not Active 非使能
0x1:ON 浅沙模式开启
0x2:OFF 浅沙模式关闭
0x3:reserved 预留";

BA_DEF_ BU_ "ILused" ENUM "No","Yes";
BA_DEF_ BU_ "NodeLayerModules" STRING ;
BA_DEF_ "Baudrate" INT 0 1000000;
BA_DEF_ "BaudrateCANFD" INT 1000000 10000000;
BA_DEF_ "BusType" STRING ;
BA_DEF_ "DBName" STRING ;
BA_DEF_ "NmBaseAddress" HEX 1536 1663;
BA_DEF_ "NmMessageCount" INT 0 255;
BA_DEF_ "ProtocolType" STRING ;
BA_DEF_ SG_ "ASIL" ENUM "QM","A","B","C","D";
BA_DEF_ SG_ "E2EDataLength" INT 0 65535;
BA_DEF_ SG_ "GenSigInactiveValue" HEX 0 80000000;
BA_DEF_ SG_ "GenSigInvalidValue" HEX 0 281474976710655;
BA_DEF_ SG_ "GenSigStartValue" HEX 0 80000000;
BA_DEF_ SG_ "GenSigSendType" ENUM "Cyclic","OnWrite","OnWriteWithRepetition","OnChange","OnChangeWithRepetition","IfActive","IfActiveWithRepetition","NoSigSendType";
BA_DEF_ BO_ "CANFD_BRS" ENUM "0","1";
BA_DEF_ BO_ "DiagUudtResponse" ENUM "True","False";
BA_DEF_ BO_ "GRC_History" STRING ;
BA_DEF_ BO_ "GenMsgCycleTime" INT 0 65535;
BA_DEF_ BO_ "GenMsgCycleTimeFast" INT 0 65535;
BA_DEF_ BO_ "GenMsgDelayTime" INT 0 65535;
BA_DEF_ BO_ "GenMsgILSupport" ENUM "No","Yes";
BA_DEF_ BO_ "GenMsgNrOfRepetition" INT 0 255;
BA_DEF_ BO_ "GenMsgSendType" ENUM "Cyclic","Event","IfActive","CE","CA","NoMsgSendType";
BA_DEF_ BO_ "GenMsgStartDelayTime" INT 0 65535;
BA_DEF_ BO_ "MsgType" ENUM "IL","NM","DIAG","APPL";
BA_DEF_ BO_ "Msg_ASIL" ENUM "vector_leerstring","QM","A","B","C","D";
BA_DEF_ BO_ "NmAsrMessage" ENUM "No","Yes";
BA_DEF_ BO_ "NmMessage" ENUM "No","Yes";
BA_DEF_ BO_ "SCP_AuthInfoTxLength" INT 9 512;
BA_DEF_ BO_ "SCP_FreshnessValueLength" INT 0 512;
BA_DEF_ BO_ "SCP_FreshnessValueTxLength" INT 0 512;
BA_DEF_ BO_ "VFrameFormat" ENUM "StandardCAN","ExtendedCAN","reserved","J1939PG","reserved","reserved","reserved","reserved","reserved","reserved","reserved","reserved","reserved","reserved","StandardCAN_FD","ExtendedCAN_FD";
BA_DEF_DEF_ "ILused" "Yes";
BA_DEF_DEF_ "NodeLayerModules" "CANoeILNLSPA.dll";
BA_DEF_DEF_ "Baudrate" 500000;
BA_DEF_DEF_ "BaudrateCANFD" 2000000;
BA_DEF_DEF_ "BusType" "CAN";
BA_DEF_DEF_ "DBName" "CAN";
BA_DEF_DEF_ "NmBaseAddress" 1536;
BA_DEF_DEF_ "NmMessageCount" 128;
BA_DEF_DEF_ "ProtocolType" "CAN";
BA_DEF_DEF_ "ASIL" "QM";
BA_DEF_DEF_ "E2EDataLength" 64;
BA_DEF_DEF_ "GenSigInactiveValue" 0;
BA_DEF_DEF_ "GenSigInvalidValue" 0;
BA_DEF_DEF_ "GenSigStartValue" 0;
BA_DEF_DEF_ "GenSigSendType" "NoSigSendType";
BA_DEF_DEF_ "CANFD_BRS" "1";
BA_DEF_DEF_ "DiagUudtResponse" "True";
BA_DEF_DEF_ "GRC_History" "";
BA_DEF_DEF_ "GenMsgCycleTime" 0;
BA_DEF_DEF_ "GenMsgCycleTimeFast" 0;
BA_DEF_DEF_ "GenMsgDelayTime" 0;
BA_DEF_DEF_ "GenMsgILSupport" "Yes";
BA_DEF_DEF_ "GenMsgNrOfRepetition" 0;
BA_DEF_DEF_ "GenMsgSendType" "Cyclic";
BA_DEF_DEF_ "GenMsgStartDelayTime" 0;
BA_DEF_DEF_ "MsgType" "IL";
BA_DEF_DEF_ "Msg_ASIL" "vector_leerstring";
BA_DEF_DEF_ "NmAsrMessage" "No";
BA_DEF_DEF_ "NmMessage" "No";
BA_DEF_DEF_ "SCP_AuthInfoTxLength" 28;
BA_DEF_DEF_ "SCP_FreshnessValueLength" 48;
BA_DEF_DEF_ "SCP_FreshnessValueTxLength" 4;
BA_DEF_DEF_ "VFrameFormat" "J1939PG";
BA_ "BusType" "CAN FD";
BA_ "DBName" "FL_EP_CANFD";
BA_ "ILused" BU_ BMS 0;
BA_ "ILused" BU_ CDU 0;
BA_ "ILused" BU_ DCB 0;
BA_ "ILused" BU_ EAC 0;
BA_ "ILused" BU_ EVCC 0;
BA_ "ILused" BU_ FLZCU 0;
BA_ "ILused" BU_ LBMS 0;
BA_ "ILused" BU_ RXCU 0;
BA_ "GenMsgCycleTime" BO_ 258 10;
BA_ "VFrameFormat" BO_ 258 14;
BA_ "GenMsgCycleTime" BO_ 369 10;
BA_ "VFrameFormat" BO_ 369 14;
BA_ "GenMsgCycleTime" BO_ 385 10;
BA_ "VFrameFormat" BO_ 385 14;
BA_ "GenMsgCycleTime" BO_ 401 10;
BA_ "VFrameFormat" BO_ 401 14;
BA_ "GenMsgCycleTime" BO_ 513 20;
BA_ "VFrameFormat" BO_ 513 14;
BA_ "GenMsgCycleTime" BO_ 515 20;
BA_ "VFrameFormat" BO_ 515 14;
BA_ "GenMsgCycleTime" BO_ 520 20;
BA_ "VFrameFormat" BO_ 520 14;
BA_ "GenMsgCycleTime" BO_ 523 20;
BA_ "VFrameFormat" BO_ 523 14;
BA_ "GenMsgCycleTime" BO_ 563 20;
BA_ "VFrameFormat" BO_ 563 14;
BA_ "GenMsgCycleTime" BO_ 638 20;
BA_ "VFrameFormat" BO_ 638 14;
BA_ "GenMsgCycleTime" BO_ 644 20;
BA_ "VFrameFormat" BO_ 644 14;
BA_ "GenMsgCycleTime" BO_ 683 20;
BA_ "VFrameFormat" BO_ 683 14;
BA_ "GenMsgCycleTime" BO_ 745 20;
BA_ "VFrameFormat" BO_ 745 14;
BA_ "GenMsgNrOfRepetition" BO_ 789 3;
BA_ "GenMsgDelayTime" BO_ 789 5;
BA_ "GenMsgCycleTimeFast" BO_ 789 20;
BA_ "GenMsgSendType" BO_ 789 1;
BA_ "VFrameFormat" BO_ 789 14;
BA_ "GenMsgCycleTime" BO_ 859 50;
BA_ "VFrameFormat" BO_ 859 14;
BA_ "GenMsgSendType" BO_ 961 1;
BA_ "VFrameFormat" BO_ 961 14;
BA_ "GenMsgSendType" BO_ 962 1;
BA_ "VFrameFormat" BO_ 962 14;
BA_ "GenMsgSendType" BO_ 964 1;
BA_ "VFrameFormat" BO_ 964 14;
BA_ "GenMsgSendType" BO_ 966 1;
BA_ "VFrameFormat" BO_ 966 14;
BA_ "GenMsgCycleTime" BO_ 991 50;
BA_ "VFrameFormat" BO_ 991 14;
BA_ "GenMsgCycleTime" BO_ 1024 100;
BA_ "VFrameFormat" BO_ 1024 14;
BA_ "GenMsgCycleTime" BO_ 1029 100;
BA_ "VFrameFormat" BO_ 1029 14;
BA_ "GenMsgCycleTime" BO_ 1034 100;
BA_ "VFrameFormat" BO_ 1034 14;
BA_ "GenMsgCycleTime" BO_ 1035 100;
BA_ "VFrameFormat" BO_ 1035 14;
BA_ "GenMsgCycleTime" BO_ 1038 100;
BA_ "VFrameFormat" BO_ 1038 14;
BA_ "GenMsgCycleTime" BO_ 1039 100;
BA_ "VFrameFormat" BO_ 1039 14;
BA_ "GenMsgCycleTime" BO_ 1043 100;
BA_ "VFrameFormat" BO_ 1043 14;
BA_ "GenMsgCycleTime" BO_ 1044 100;
BA_ "VFrameFormat" BO_ 1044 14;
BA_ "GenMsgCycleTime" BO_ 1045 100;
BA_ "VFrameFormat" BO_ 1045 14;
BA_ "GenMsgCycleTime" BO_ 1055 100;
BA_ "VFrameFormat" BO_ 1055 14;
BA_ "GenMsgCycleTime" BO_ 1057 100;
BA_ "VFrameFormat" BO_ 1057 14;
BA_ "GenMsgCycleTime" BO_ 1078 100;
BA_ "VFrameFormat" BO_ 1078 14;
BA_ "GenMsgCycleTime" BO_ 1086 100;
BA_ "VFrameFormat" BO_ 1086 14;
BA_ "GenMsgCycleTime" BO_ 1092 100;
BA_ "VFrameFormat" BO_ 1092 14;
BA_ "GenMsgCycleTime" BO_ 1096 100;
BA_ "VFrameFormat" BO_ 1096 14;
BA_ "GenMsgCycleTime" BO_ 1111 100;
BA_ "VFrameFormat" BO_ 1111 14;
BA_ "GenMsgCycleTime" BO_ 1117 100;
BA_ "VFrameFormat" BO_ 1117 14;
BA_ "GenMsgCycleTime" BO_ 1122 100;
BA_ "VFrameFormat" BO_ 1122 14;
BA_ "GenMsgCycleTime" BO_ 1127 100;
BA_ "VFrameFormat" BO_ 1127 14;
BA_ "GenMsgNrOfRepetition" BO_ 1137 3;
BA_ "GenMsgCycleTime" BO_ 1137 100;
BA_ "GenMsgDelayTime" BO_ 1137 5;
BA_ "GenMsgCycleTimeFast" BO_ 1137 100;
BA_ "GenMsgSendType" BO_ 1137 3;
BA_ "VFrameFormat" BO_ 1137 14;
BA_ "GenMsgCycleTime" BO_ 1142 100;
BA_ "VFrameFormat" BO_ 1142 14;
BA_ "GenMsgCycleTime" BO_ 1143 100;
BA_ "VFrameFormat" BO_ 1143 14;
BA_ "GenMsgNrOfRepetition" BO_ 1144 3;
BA_ "GenMsgCycleTime" BO_ 1144 100;
BA_ "GenMsgDelayTime" BO_ 1144 5;
BA_ "GenMsgCycleTimeFast" BO_ 1144 100;
BA_ "GenMsgSendType" BO_ 1144 3;
BA_ "VFrameFormat" BO_ 1144 14;
BA_ "GenMsgCycleTime" BO_ 1155 100;
BA_ "VFrameFormat" BO_ 1155 14;
BA_ "GenMsgNrOfRepetition" BO_ 1167 3;
BA_ "GenMsgDelayTime" BO_ 1167 5;
BA_ "GenMsgCycleTimeFast" BO_ 1167 50;
BA_ "GenMsgSendType" BO_ 1167 1;
BA_ "VFrameFormat" BO_ 1167 14;
BA_ "GenSigSendType" SG_ 258 BMS_1_CRC1 0;
BA_ "GenSigSendType" SG_ 258 BMS_1_RollgCntr1 0;
BA_ "GenSigSendType" SG_ 258 BMS_1_Resd1 0;
BA_ "GenSigInvalidValue" SG_ 258 BMS_PackVoltage 65535;
BA_ "GenSigStartValue" SG_ 258 BMS_PackVoltage 65535;
BA_ "GenSigSendType" SG_ 258 BMS_PackVoltage 0;
BA_ "GenSigInvalidValue" SG_ 258 BMS_PackCurrent 65535;
BA_ "GenSigStartValue" SG_ 258 BMS_PackCurrent 65535;
BA_ "GenSigSendType" SG_ 258 BMS_PackCurrent 0;
BA_ "GenSigSendType" SG_ 258 BMS_HvBattSts 0;
BA_ "GenSigSendType" SG_ 258 BMS_SysSelfCheck 0;
BA_ "GenSigInvalidValue" SG_ 258 BMS_HVBattThermRunaway 2;
BA_ "GenSigSendType" SG_ 258 BMS_HVBattThermRunaway 0;
BA_ "GenSigSendType" SG_ 258 BMS_1_CRC2 0;
BA_ "GenSigSendType" SG_ 258 BMS_1_RollgCntr2 0;
BA_ "GenSigSendType" SG_ 258 BMS_1_Resd2 0;
BA_ "GenSigStartValue" SG_ 258 BMS_ChargeVoltageReq 16382;
BA_ "GenSigSendType" SG_ 258 BMS_ChargeVoltageReq 0;
BA_ "GenSigStartValue" SG_ 258 BMS_ChgCurrReq 16382;
BA_ "GenSigSendType" SG_ 258 BMS_ChgCurrReq 0;
BA_ "GenSigStartValue" SG_ 258 BMS_InfraDcUActDc 16382;
BA_ "GenSigSendType" SG_ 258 BMS_InfraDcUActDc 0;
BA_ "GenSigSendType" SG_ 258 BMS_1_CRC3 0;
BA_ "GenSigSendType" SG_ 258 BMS_1_RollgCntr3 0;
BA_ "GenSigSendType" SG_ 258 BMS_1_Resd3 0;
BA_ "GenSigStartValue" SG_ 258 BMS_InfraDcIActDc 16382;
BA_ "GenSigSendType" SG_ 258 BMS_InfraDcIActDc 0;
BA_ "GenSigStartValue" SG_ 258 BMS_HvBattDynChrgnILim 16382;
BA_ "GenSigSendType" SG_ 258 BMS_HvBattDynChrgnILim 0;
BA_ "GenSigStartValue" SG_ 258 BMS_HvBattUChrgnLim 16382;
BA_ "GenSigSendType" SG_ 258 BMS_HvBattUChrgnLim 0;
BA_ "GenSigSendType" SG_ 258 BMS_1_CRC4 0;
BA_ "GenSigSendType" SG_ 258 BMS_1_RollgCntr4 0;
BA_ "GenSigSendType" SG_ 258 BMS_1_Resd4 0;
BA_ "GenSigStartValue" SG_ 258 BMS_ChrgDcIAvl 16382;
BA_ "GenSigSendType" SG_ 258 BMS_ChrgDcIAvl 0;
BA_ "GenSigSendType" SG_ 258 BMS_DChrgAPlusSt 0;
BA_ "GenSigSendType" SG_ 258 BMS_Insulation_R 0;
BA_ "GenSigSendType" SG_ 258 BMS_ChrgDcCnctrDetd 0;
BA_ "GenSigSendType" SG_ 258 BMS_DCChgMode 0;
BA_ "GenSigSendType" SG_ 258 BMS_ChrgDcChrgnFltStopReas 0;
BA_ "GenSigSendType" SG_ 258 BMS_1_CRC5 0;
BA_ "GenSigSendType" SG_ 258 BMS_1_RollgCntr5 0;
BA_ "GenSigSendType" SG_ 258 BMS_1_Resd5 0;
BA_ "GenSigStartValue" SG_ 258 BMS_ChgRemTime 2047;
BA_ "GenSigSendType" SG_ 258 BMS_ChgRemTime 0;
BA_ "GenSigStartValue" SG_ 258 BMS_ChargeRequest_Mode 15;
BA_ "GenSigSendType" SG_ 258 BMS_ChargeRequest_Mode 0;
BA_ "GenSigInvalidValue" SG_ 258 BMS_StateOfEnergy 65535;
BA_ "GenSigStartValue" SG_ 258 BMS_StateOfEnergy 65535;
BA_ "GenSigSendType" SG_ 258 BMS_StateOfEnergy 0;
BA_ "GenSigSendType" SG_ 258 BMS_1_CRC6 0;
BA_ "GenSigSendType" SG_ 258 BMS_1_RollgCntr6 0;
BA_ "GenSigSendType" SG_ 258 BMS_1_Resd6 0;
BA_ "GenSigSendType" SG_ 258 BMS_StateOfHealth 0;
BA_ "GenSigSendType" SG_ 258 BMS_BlanceState 0;
BA_ "GenSigSendType" SG_ 258 BMS_IsolationFault 0;
BA_ "GenSigSendType" SG_ 258 BMS_HVILFault_DC 0;
BA_ "GenSigInvalidValue" SG_ 258 BMS_SOCDis 16383;
BA_ "GenSigStartValue" SG_ 258 BMS_SOCDis 16383;
BA_ "GenSigSendType" SG_ 258 BMS_SOCDis 0;
BA_ "GenSigStartValue" SG_ 258 BMS_InfraDcIActDcMin 16383;
BA_ "GenSigSendType" SG_ 258 BMS_InfraDcIActDcMin 0;
BA_ "GenSigSendType" SG_ 369 VCU_1_CRC1 0;
BA_ "GenSigSendType" SG_ 369 VCU_1_RollgCntr1 0;
BA_ "GenSigSendType" SG_ 369 VCU_1_Resd1 0;
BA_ "GenSigSendType" SG_ 369 VCU_BMSPreheatKeepWarmAllow 0;
BA_ "GenSigSendType" SG_ 369 VCU_BMSAcChrgPerm 0;
BA_ "GenSigSendType" SG_ 369 VCU_BMSStsReq_Reserved 0;
BA_ "GenSigSendType" SG_ 369 VCU_ElectronicLockReq 0;
BA_ "GenSigSendType" SG_ 369 VCU_ErrLvl 0;
BA_ "GenSigSendType" SG_ 369 VCU_PwtCoolingLvl_171h 0;
BA_ "GenSigInvalidValue" SG_ 369 HCU_BMSVehDcChrgnIDmd_171h 16383;
BA_ "GenSigStartValue" SG_ 369 HCU_BMSVehDcChrgnIDmd_171h 10240;
BA_ "GenSigSendType" SG_ 369 HCU_BMSVehDcChrgnIDmd_171h 0;
BA_ "GenSigSendType" SG_ 385 VCU_2_CRC1 0;
BA_ "GenSigSendType" SG_ 385 VCU_2_RollgCntr1 0;
BA_ "GenSigSendType" SG_ 385 VCU_2_Resd1 0;
BA_ "GenSigInvalidValue" SG_ 385 VCU_BMSVehDcChrgnIDmd 16383;
BA_ "GenSigStartValue" SG_ 385 VCU_BMSVehDcChrgnIDmd 10240;
BA_ "GenSigSendType" SG_ 385 VCU_BMSVehDcChrgnIDmd 0;
BA_ "GenSigSendType" SG_ 385 VCU_BMSHVreq 0;
BA_ "GenSigInvalidValue" SG_ 385 VCU_BMSVehDcChrgnUDmd 16383;
BA_ "GenSigSendType" SG_ 385 VCU_BMSVehDcChrgnUDmd 0;
BA_ "GenSigInvalidValue" SG_ 385 VCU_TargetSOC 1023;
BA_ "GenSigSendType" SG_ 385 VCU_TargetSOC 0;
BA_ "GenSigSendType" SG_ 385 VCU_BMSDcChrgPerm 0;
BA_ "GenSigSendType" SG_ 401 VCU_3_CRC1 0;
BA_ "GenSigSendType" SG_ 401 VCU_3_RollgCntr1 0;
BA_ "GenSigSendType" SG_ 401 VCU_3_Resd1 0;
BA_ "GenSigStartValue" SG_ 401 VCU_DCDCVoltageSetPoint 135;
BA_ "GenSigSendType" SG_ 401 VCU_DCDCVoltageSetPoint 0;
BA_ "GenSigSendType" SG_ 401 VCU_DCDCPwrLimit 0;
BA_ "GenSigSendType" SG_ 401 VCU_DCDCEnable 0;
BA_ "ASIL" SG_ 513 MFSL_UP_SW 2;
BA_ "GenSigSendType" SG_ 513 MFSL_UP_SW 0;
BA_ "ASIL" SG_ 513 MFSL_DW_SW 2;
BA_ "GenSigSendType" SG_ 513 MFSL_DW_SW 0;
BA_ "GenSigSendType" SG_ 513 MFSL_OK_SW 0;
BA_ "GenSigSendType" SG_ 515 EVCC_1_CRC1 0;
BA_ "GenSigSendType" SG_ 515 EVCC_1_RollgCntr1 0;
BA_ "GenSigSendType" SG_ 515 EVCC_1_Resd1 0;
BA_ "GenSigSendType" SG_ 515 EVCC_ElectronicLockSts 0;
BA_ "GenSigInvalidValue" SG_ 515 EVCC_GunConnectSt_203h 3;
BA_ "GenSigSendType" SG_ 515 EVCC_GunConnectSt_203h 0;
BA_ "GenSigSendType" SG_ 515 EVCC_CC_RCR4_Sts 0;
BA_ "GenSigSendType" SG_ 515 EVCC_COUNTRY_SUPPORT 0;
BA_ "GenSigSendType" SG_ 515 EVCC_CP_DutyCycleFault 0;
BA_ "GenSigInvalidValue" SG_ 515 EVCC_CC_ConnectSts 3;
BA_ "GenSigSendType" SG_ 515 EVCC_CC_ConnectSts 0;
BA_ "GenSigSendType" SG_ 515 EVCC_S2Swtsts 0;
BA_ "GenSigSendType" SG_ 515 EVCC_CPSts 0;
BA_ "GenSigSendType" SG_ 515 EVCC_ChargeType 0;
BA_ "GenSigSendType" SG_ 515 EVCC_CC2_Alarm 0;
BA_ "GenSigInvalidValue" SG_ 515 EVCC_CC2_ConnectSts 3;
BA_ "GenSigSendType" SG_ 515 EVCC_CC2_ConnectSts 0;
BA_ "GenSigInvalidValue" SG_ 515 EVCC_CC_ConnectDischarSts 3;
BA_ "GenSigSendType" SG_ 515 EVCC_CC_ConnectDischarSts 0;
BA_ "GenSigSendType" SG_ 515 EVCC_1_CRC2 0;
BA_ "GenSigSendType" SG_ 515 EVCC_1_RollgCntr2 0;
BA_ "GenSigSendType" SG_ 515 EVCC_1_Resd2 0;
BA_ "GenSigInvalidValue" SG_ 515 EVCC_CPMaxVolt 1023;
BA_ "GenSigSendType" SG_ 515 EVCC_CPMaxVolt 0;
BA_ "GenSigSendType" SG_ 515 EVCC_FaultLevel 0;
BA_ "GenSigInvalidValue" SG_ 515 EVCC_DCPlusTemp 255;
BA_ "GenSigStartValue" SG_ 515 EVCC_DCPlusTemp 254;
BA_ "GenSigSendType" SG_ 515 EVCC_DCPlusTemp 0;
BA_ "GenSigInvalidValue" SG_ 515 EVCC_DCMinusTemp 255;
BA_ "GenSigStartValue" SG_ 515 EVCC_DCMinusTemp 254;
BA_ "GenSigSendType" SG_ 515 EVCC_DCMinusTemp 0;
BA_ "GenSigSendType" SG_ 515 EVCC_TotalFaultNum 0;
BA_ "GenSigSendType" SG_ 515 EVCC_FaultNum1 0;
BA_ "GenSigSendType" SG_ 515 EVCC_FaultNum2 0;
BA_ "GenSigSendType" SG_ 520 BMS_2_CRC1 0;
BA_ "GenSigSendType" SG_ 520 BMS_2_RollgCntr1 0;
BA_ "GenSigSendType" SG_ 520 BMS_2_Resd1 0;
BA_ "GenSigInvalidValue" SG_ 520 BMS_C2Target_Chg_Voltage 65535;
BA_ "GenSigSendType" SG_ 520 BMS_C2Target_Chg_Voltage 0;
BA_ "GenSigInvalidValue" SG_ 520 BMS_CHGstation_MAXPwr 255;
BA_ "GenSigSendType" SG_ 520 BMS_CHGstation_MAXPwr 0;
BA_ "GenSigSendType" SG_ 520 BMS_2_CRC2 0;
BA_ "GenSigSendType" SG_ 520 BMS_2_RollgCntr2 0;
BA_ "GenSigSendType" SG_ 520 BMS_2_Resd2 0;
BA_ "GenSigSendType" SG_ 520 BMS_HvBattThermReqLevel 0;
BA_ "GenSigSendType" SG_ 520 BMS_NV_relay_Sts 0;
BA_ "GenSigSendType" SG_ 520 BMS_PV_relay_Sts 0;
BA_ "GenSigSendType" SG_ 520 BMS_QCP_relay_Sts 0;
BA_ "GenSigSendType" SG_ 520 BMS_QCN_relay_Sts 0;
BA_ "GenSigSendType" SG_ 520 BMS_Prechage_relay_Sts 0;
BA_ "GenSigSendType" SG_ 520 BMS_HvBattThermReqMode 0;
BA_ "GenSigStartValue" SG_ 520 BMS_ClntTHvBattIn 254;
BA_ "GenSigSendType" SG_ 520 BMS_ClntTHvBattIn 0;
BA_ "GenSigStartValue" SG_ 520 BMS_ClntTHvBattOut 254;
BA_ "GenSigSendType" SG_ 520 BMS_ClntTHvBattOut 0;
BA_ "GenSigStartValue" SG_ 520 BMS_HvBattClntInTReq 126;
BA_ "GenSigSendType" SG_ 520 BMS_HvBattClntInTReq 0;
BA_ "GenSigSendType" SG_ 520 BMS_2_CRC3 0;
BA_ "GenSigSendType" SG_ 520 BMS_2_RollgCntr3 0;
BA_ "GenSigSendType" SG_ 520 BMS_2_Resd3 0;
BA_ "GenSigStartValue" SG_ 520 BMS_HvBattClntFlowReq 126;
BA_ "GenSigSendType" SG_ 520 BMS_HvBattClntFlowReq 0;
BA_ "GenSigStartValue" SG_ 520 BMS_HvBattAvgT 254;
BA_ "GenSigSendType" SG_ 520 BMS_HvBattAvgT 0;
BA_ "GenSigInvalidValue" SG_ 520 BMS_HvBattMaxT 255;
BA_ "GenSigStartValue" SG_ 520 BMS_HvBattMaxT 255;
BA_ "GenSigSendType" SG_ 520 BMS_HvBattMaxT 0;
BA_ "GenSigInvalidValue" SG_ 520 BMS_HvBattMinT 255;
BA_ "GenSigStartValue" SG_ 520 BMS_HvBattMinT 255;
BA_ "GenSigSendType" SG_ 520 BMS_HvBattMinT 0;
BA_ "GenSigStartValue" SG_ 520 BMS_HvBattTdiff 126;
BA_ "GenSigSendType" SG_ 520 BMS_HvBattTdiff 0;
BA_ "GenSigSendType" SG_ 520 BMS_2_CRC4 0;
BA_ "GenSigSendType" SG_ 520 BMS_2_RollgCntr4 0;
BA_ "GenSigSendType" SG_ 520 BMS_2_Resd4 0;
BA_ "GenSigInvalidValue" SG_ 520 BMS_OutPosU 16383;
BA_ "GenSigStartValue" SG_ 520 BMS_OutPosU 16382;
BA_ "GenSigSendType" SG_ 520 BMS_OutPosU 0;
BA_ "GenSigInvalidValue" SG_ 520 BMS_OutNegU 16383;
BA_ "GenSigStartValue" SG_ 520 BMS_OutNegU 16382;
BA_ "GenSigSendType" SG_ 520 BMS_OutNegU 0;
BA_ "GenSigSendType" SG_ 520 BMS_2_CRC5 0;
BA_ "GenSigSendType" SG_ 520 BMS_2_RollgCntr5 0;
BA_ "GenSigSendType" SG_ 520 BMS_2_Resd5 0;
BA_ "GenSigInvalidValue" SG_ 520 BMS_outQCPosU 16383;
BA_ "GenSigStartValue" SG_ 520 BMS_outQCPosU 16382;
BA_ "GenSigSendType" SG_ 520 BMS_outQCPosU 0;
BA_ "GenSigInvalidValue" SG_ 520 BMS_outQCNegU 16383;
BA_ "GenSigStartValue" SG_ 520 BMS_outQCNegU 16382;
BA_ "GenSigSendType" SG_ 520 BMS_outQCNegU 0;
BA_ "GenSigSendType" SG_ 520 BMS_Middlesplit_relay_Sts 0;
BA_ "GenSigSendType" SG_ 523 BMS_3_CRC1 0;
BA_ "GenSigSendType" SG_ 523 BMS_3_RollgCntr1 0;
BA_ "GenSigSendType" SG_ 523 BMS_3_Resd1 0;
BA_ "GenSigStartValue" SG_ 523 BMS_HvBattPMaxReChrgLim 16382;
BA_ "GenSigSendType" SG_ 523 BMS_HvBattPMaxReChrgLim 0;
BA_ "GenSigSendType" SG_ 523 BMS_3_CRC2 0;
BA_ "GenSigSendType" SG_ 523 BMS_3_RollgCntr2 0;
BA_ "GenSigSendType" SG_ 523 BMS_3_Resd2 0;
BA_ "GenSigStartValue" SG_ 523 BMS_HvBattIMaxReChrgLim 2047;
BA_ "GenSigSendType" SG_ 523 BMS_HvBattIMaxReChrgLim 0;
BA_ "GenSigStartValue" SG_ 523 BMS_HvBattPMaxDchaLim 16382;
BA_ "GenSigSendType" SG_ 523 BMS_HvBattPMaxDchaLim 0;
BA_ "GenSigSendType" SG_ 523 BMS_3_CRC3 0;
BA_ "GenSigSendType" SG_ 523 BMS_3_RollgCntr3 0;
BA_ "GenSigSendType" SG_ 523 BMS_3_Resd3 0;
BA_ "GenSigStartValue" SG_ 523 BMS_HvBattIMaxDchaLim 2047;
BA_ "GenSigSendType" SG_ 523 BMS_HvBattIMaxDchaLim 0;
BA_ "GenSigSendType" SG_ 523 BMS_3_CRC4 0;
BA_ "GenSigSendType" SG_ 523 BMS_3_RollgCntr4 0;
BA_ "GenSigSendType" SG_ 523 BMS_3_Resd4 0;
BA_ "GenSigSendType" SG_ 523 BMS_3_CRC5 0;
BA_ "GenSigSendType" SG_ 523 BMS_3_RollgCntr5 0;
BA_ "GenSigSendType" SG_ 523 BMS_3_Resd5 0;
BA_ "GenSigInvalidValue" SG_ 523 BMS_KL30Volt 2047;
BA_ "GenSigSendType" SG_ 523 BMS_KL30Volt 0;
BA_ "GenSigInvalidValue" SG_ 523 BMS_kL87Volt 2047;
BA_ "GenSigSendType" SG_ 523 BMS_kL87Volt 0;
BA_ "GenSigStartValue" SG_ 523 BMS_HvBattUDchaLim 16382;
BA_ "GenSigSendType" SG_ 523 BMS_HvBattUDchaLim 0;
BA_ "GenSigSendType" SG_ 523 BMS_3_CRC6 0;
BA_ "GenSigSendType" SG_ 523 BMS_3_RollgCntr6 0;
BA_ "GenSigSendType" SG_ 523 BMS_3_Resd6 0;
BA_ "GenSigInvalidValue" SG_ 523 BMSH_MaxChgPwrPeak 4095;
BA_ "GenSigSendType" SG_ 523 BMSH_MaxChgPwrPeak 0;
BA_ "GenSigInvalidValue" SG_ 523 BMSH_MaxDchgPwrPeak 4095;
BA_ "GenSigSendType" SG_ 523 BMSH_MaxDchgPwrPeak 0;
BA_ "GenSigSendType" SG_ 563 VCU_6_G_CRC 0;
BA_ "GenSigSendType" SG_ 563 VCU_6_G_RollgCntr 0;
BA_ "GenSigSendType" SG_ 563 VCU_6_G_Resd 0;
BA_ "GenSigSendType" SG_ 563 VCU_6_G_GasPedalPosition 0;
BA_ "GenSigSendType" SG_ 563 VCU_6_G_PRNDGearAct 0;
BA_ "GenSigSendType" SG_ 563 VCU_6_G_GasPedalPositionInVD 0;
BA_ "ASIL" SG_ 638 FRZCU_HoodSts 1;
BA_ "GenSigSendType" SG_ 638 FRZCU_HoodSts 0;
BA_ "GenSigSendType" SG_ 644 ICM_5_FuelLevel_284h 0;
BA_ "ASIL" SG_ 683 PassDoorSts_2ABh 1;
BA_ "GenSigSendType" SG_ 683 PassDoorSts_2ABh 0;
BA_ "ASIL" SG_ 683 PassRearDoorSts_2ABh 1;
BA_ "GenSigSendType" SG_ 683 PassRearDoorSts_2ABh 0;
BA_ "GenSigSendType" SG_ 745 DCB_1_HVILSts 0;
BA_ "GenSigSendType" SG_ 745 DCB_1_BoostNegRelaySts 0;
BA_ "GenSigSendType" SG_ 745 DCB_1_WorkingSts 0;
BA_ "GenSigSendType" SG_ 745 DCB_1_NegFastChgRelaySts 0;
BA_ "GenSigSendType" SG_ 745 DCB_1_C2RelaySts 0;
BA_ "GenSigSendType" SG_ 745 DCB_1_ErrorLevel 0;
BA_ "GenSigSendType" SG_ 745 DCB_1_PosFastChgRelaySts 0;
BA_ "GenSigInvalidValue" SG_ 745 DCB_1_ChrgDerate 255;
BA_ "GenSigSendType" SG_ 745 DCB_1_ChrgDerate 0;
BA_ "GenSigInvalidValue" SG_ 745 DCB_1_C2RearVolt 65535;
BA_ "GenSigSendType" SG_ 745 DCB_1_C2RearVolt 0;
BA_ "GenSigInvalidValue" SG_ 745 DCB_1_InputVolt 65535;
BA_ "GenSigSendType" SG_ 745 DCB_1_InputVolt 0;
BA_ "GenSigInvalidValue" SG_ 745 DCB_1_BoostNegFrontVolt 65535;
BA_ "GenSigSendType" SG_ 745 DCB_1_BoostNegFrontVolt 0;
BA_ "GenSigInvalidValue" SG_ 745 DCB_1_NegFastChgFrontVolt 65535;
BA_ "GenSigSendType" SG_ 745 DCB_1_NegFastChgFrontVolt 0;
BA_ "GenSigInvalidValue" SG_ 745 DCB_1_BoostPosFastChgRearVolt 65535;
BA_ "GenSigSendType" SG_ 745 DCB_1_BoostPosFastChgRearVolt 0;
BA_ "GenSigSendType" SG_ 745 DCB_1_BoostPosRelaySts 0;
BA_ "GenSigSendType" SG_ 789 ATCM_DriveModeSw 2;
BA_ "GenSigSendType" SG_ 789 ATCM_XModeSw 2;
BA_ "GenSigSendType" SG_ 789 ATCM_PowerModeSw 2;
BA_ "GenSigSendType" SG_ 789 ACTM_4LModeSW 2;
BA_ "GenSigSendType" SG_ 789 ATCM_CCOSwtReq 2;
BA_ "GenSigSendType" SG_ 789 ATCM_SwitchUTurnModeSet 2;
BA_ "GenSigSendType" SG_ 789 ATCM_FrontEDL 2;
BA_ "GenSigSendType" SG_ 789 ATCM_RearEDL 2;
BA_ "GenSigSendType" SG_ 789 ATCM_ASU_LiftSet 2;
BA_ "GenSigSendType" SG_ 789 ATCM_ASU_LowerSet 2;
BA_ "GenSigSendType" SG_ 789 ATCM_TABSwtReq 2;
BA_ "GenSigSendType" SG_ 789 ATCM_EngyRec_SW 2;
BA_ "GenSigSendType" SG_ 859 FLZCU_IRCHV_Req 0;
BA_ "GenSigSendType" SG_ 961 IMMO_Auth_VCU 1;
BA_ "GenSigSendType" SG_ 962 VCU_Chall_IMMO 1;
BA_ "GenSigSendType" SG_ 964 IMMO_Teach_VCU 1;
BA_ "GenSigSendType" SG_ 966 VCU_Teach_IMMO 1;
BA_ "GenSigSendType" SG_ 991 ErrorLevel 0;
BA_ "GenSigSendType" SG_ 991 TMS_HV_Req 0;
BA_ "GenSigSendType" SG_ 991 TMS_EngingstartReq 0;
BA_ "GenSigSendType" SG_ 1024 FRZCU_OnekeyHVoffSwtst 0;
BA_ "GenSigInvalidValue" SG_ 1029 LBMS_PackExtU 32767;
BA_ "GenSigStartValue" SG_ 1029 LBMS_PackExtU 32766;
BA_ "GenSigSendType" SG_ 1029 LBMS_PackExtU 0;
BA_ "GenSigInvalidValue" SG_ 1029 LBMS_PackT1 255;
BA_ "GenSigStartValue" SG_ 1029 LBMS_PackT1 254;
BA_ "GenSigSendType" SG_ 1029 LBMS_PackT1 0;
BA_ "GenSigSendType" SG_ 1029 LBMS_PackExtUVld 0;
BA_ "GenSigInvalidValue" SG_ 1029 LBMS_PackT2 255;
BA_ "GenSigStartValue" SG_ 1029 LBMS_PackT2 254;
BA_ "GenSigSendType" SG_ 1029 LBMS_PackT2 0;
BA_ "GenSigInvalidValue" SG_ 1029 LBMS_PackT3 255;
BA_ "GenSigStartValue" SG_ 1029 LBMS_PackT3 254;
BA_ "GenSigSendType" SG_ 1029 LBMS_PackT3 0;
BA_ "GenSigSendType" SG_ 1029 LBMS_PackTVld 0;
BA_ "GenSigSendType" SG_ 1034 HCU_1_G_CRC1 0;
BA_ "GenSigSendType" SG_ 1034 HCU_1_G_RollgCntr1 0;
BA_ "GenSigSendType" SG_ 1034 HCU_1_G_Resd1 0;
BA_ "GenSigInvalidValue" SG_ 1034 HCU_EmPwr 255;
BA_ "GenSigStartValue" SG_ 1034 HCU_EmPwr 128;
BA_ "GenSigSendType" SG_ 1034 HCU_EmPwr 0;
BA_ "ASIL" SG_ 1034 HCU_VehicleState 1;
BA_ "GenSigSendType" SG_ 1034 HCU_VehicleState 0;
BA_ "GenSigSendType" SG_ 1034 HCU_RunMode 0;
BA_ "GenSigSendType" SG_ 1034 HCU_TMNumber 0;
BA_ "GenSigSendType" SG_ 1034 HCU_PwrTrnModeDisp 0;
BA_ "GenSigSendType" SG_ 1034 HCU_IntelligentPowerSupply 0;
BA_ "ASIL" SG_ 1034 HCU_PowerModeFed 1;
BA_ "GenSigSendType" SG_ 1034 HCU_PowerModeFed 0;
BA_ "ASIL" SG_ 1034 HCU_LimpHomeMode 1;
BA_ "GenSigSendType" SG_ 1034 HCU_LimpHomeMode 0;
BA_ "GenSigSendType" SG_ 1034 HCU_ISGRegenerateSts 0;
BA_ "GenSigSendType" SG_ 1034 HCU_EmOverSpdWarn 0;
BA_ "GenSigSendType" SG_ 1034 HCU_PowertrainFault 0;
BA_ "ASIL" SG_ 1034 HCU_PrePTReady 1;
BA_ "GenSigSendType" SG_ 1034 HCU_PrePTReady 0;
BA_ "GenSigSendType" SG_ 1034 HCU_PowerModeChangeFail 0;
BA_ "GenSigSendType" SG_ 1034 BMSH_MILReq 0;
BA_ "ASIL" SG_ 1034 TMF_EngMilLampReq 1;
BA_ "GenSigSendType" SG_ 1034 TMF_EngMilLampReq 0;
BA_ "ASIL" SG_ 1034 TMR_EngMilLampReq 1;
BA_ "GenSigSendType" SG_ 1034 TMR_EngMilLampReq 0;
BA_ "ASIL" SG_ 1034 HCU_MILReq 1;
BA_ "GenSigSendType" SG_ 1034 HCU_MILReq 0;
BA_ "ASIL" SG_ 1034 HCU_HVReady 1;
BA_ "GenSigSendType" SG_ 1034 HCU_HVReady 0;
BA_ "ASIL" SG_ 1034 HCU_PTReady 1;
BA_ "GenSigSendType" SG_ 1034 HCU_PTReady 0;
BA_ "GenSigSendType" SG_ 1034 HCU_ChargingSts 0;
BA_ "GenSigSendType" SG_ 1034 HCU_PtSts 0;
BA_ "GenSigSendType" SG_ 1034 HCU_InHbStrtRes 0;
BA_ "GenSigSendType" SG_ 1035 VCC_1_OTASts 0;
BA_ "GenSigInvalidValue" SG_ 1038 LBMS_SOC 127;
BA_ "GenSigStartValue" SG_ 1038 LBMS_SOC 126;
BA_ "ASIL" SG_ 1038 LBMS_SOC 2;
BA_ "GenSigSendType" SG_ 1038 LBMS_SOC 0;
BA_ "GenSigInvalidValue" SG_ 1038 LBMS_ReChrgReq 7;
BA_ "ASIL" SG_ 1038 LBMS_ReChrgReq 2;
BA_ "GenSigSendType" SG_ 1038 LBMS_ReChrgReq 0;
BA_ "GenSigInvalidValue" SG_ 1038 LBMS_ReqChrgU 32767;
BA_ "GenSigStartValue" SG_ 1038 LBMS_ReqChrgU 32766;
BA_ "GenSigSendType" SG_ 1038 LBMS_ReqChrgU 0;
BA_ "GenSigInvalidValue" SG_ 1039 LBMS_ChargeSts 15;
BA_ "GenSigSendType" SG_ 1039 LBMS_ChargeSts 0;
BA_ "GenSigSendType" SG_ 1039 LBMS_ChargeFlt 0;
BA_ "GenSigSendType" SG_ 1039 LBMS_ChargeEnable 0;
BA_ "GenSigInvalidValue" SG_ 1043 EBS_U_BATT 16383;
BA_ "GenSigStartValue" SG_ 1043 EBS_U_BATT 16383;
BA_ "GenSigSendType" SG_ 1043 EBS_U_BATT 0;
BA_ "GenSigInvalidValue" SG_ 1044 HCU_RangeAval 2047;
BA_ "GenSigSendType" SG_ 1044 HCU_RangeAval 0;
BA_ "GenSigSendType" SG_ 1044 HCU_EnergyFlow 0;
BA_ "GenSigSendType" SG_ 1044 HCU_ReplaceWarmupCycle 0;
BA_ "GenSigSendType" SG_ 1044 HCU_CLMOBDClearReq 0;
BA_ "GenSigSendType" SG_ 1044 HCU_2_G_ChgIncOper 0;
BA_ "GenSigSendType" SG_ 1044 HCU_2_G_ChgDepOper 0;
BA_ "GenSigSendType" SG_ 1044 HCU_SocManageFed_414h 0;
BA_ "GenSigInvalidValue" SG_ 1044 HCU_SetSOCFed 255;
BA_ "GenSigSendType" SG_ 1044 HCU_SetSOCFed 0;
BA_ "GenSigSendType" SG_ 1044 VCU_BrakePedalStsValidData 0;
BA_ "ASIL" SG_ 1044 VCU_BrakePedalSts 2;
BA_ "GenSigSendType" SG_ 1044 VCU_BrakePedalSts 0;
BA_ "GenSigSendType" SG_ 1044 HCU_EnergyFlowREEV 0;
BA_ "GenSigSendType" SG_ 1044 HCU_EmissionDetection 0;
BA_ "GenSigSendType" SG_ 1044 HCU_2_G_IntrptGpfRgtvSt 0;
BA_ "GenSigSendType" SG_ 1044 HCU_2_G_LowBatteryInfo 0;
BA_ "GenSigSendType" SG_ 1044 HCU_2_G_LowBatteryLowFuelInfo 0;
BA_ "GenSigSendType" SG_ 1044 HCU_2_G_HighTempLimit 0;
BA_ "GenSigSendType" SG_ 1045 TBOX_OTAHV_Req_415h 0;
BA_ "GenSigSendType" SG_ 1055 BMS_4_CRC1 0;
BA_ "GenSigSendType" SG_ 1055 BMS_4_RollgCntr1 0;
BA_ "GenSigSendType" SG_ 1055 BMS_4_Resd1 0;
BA_ "GenSigSendType" SG_ 1055 BMS_ErrorNumber 0;
BA_ "GenSigSendType" SG_ 1055 BMS_ErrorCode 0;
BA_ "GenSigSendType" SG_ 1055 BMS_4_CRC2 0;
BA_ "GenSigSendType" SG_ 1055 BMS_4_RollgCntr2 0;
BA_ "GenSigSendType" SG_ 1055 BMS_4_Resd2 0;
BA_ "GenSigSendType" SG_ 1055 BMSH_MILReq_41Fh 0;
BA_ "GenSigSendType" SG_ 1055 BMS_HvBattUnderTemperature 0;
BA_ "GenSigSendType" SG_ 1055 BMS_ErrorLevel 0;
BA_ "GenSigSendType" SG_ 1055 BMS_ThermRunCode 0;
BA_ "GenSigSendType" SG_ 1055 BMS_DChrgEndCode 0;
BA_ "GenSigSendType" SG_ 1055 BMS_PwrDerateFlg 0;
BA_ "GenSigSendType" SG_ 1057 VCU_shfChk 0;
BA_ "GenSigSendType" SG_ 1057 VCU_PowerLimitSOCLow 0;
BA_ "GenSigSendType" SG_ 1057 VCU_MCU_MilLampReq 0;
BA_ "GenSigSendType" SG_ 1057 VCU_OPDinfo 0;
BA_ "GenSigInvalidValue" SG_ 1057 VCU_ePTDrvPowerPcent 255;
BA_ "GenSigSendType" SG_ 1057 VCU_ePTDrvPowerPcent 0;
BA_ "GenSigSendType" SG_ 1057 VCU_TowingMode 0;
BA_ "GenSigSendType" SG_ 1057 VCU_EgyRegenLevelHighAllowed 0;
BA_ "GenSigSendType" SG_ 1057 VCU_SportDriveModeAvailable 0;
BA_ "GenSigSendType" SG_ 1057 VCU_RainSnowDriveModeAvailable 0;
BA_ "GenSigSendType" SG_ 1057 VCU_OffRoadDriveModeAvailable 0;
BA_ "GenSigSendType" SG_ 1057 VCU_CampAvailable 0;
BA_ "GenSigInvalidValue" SG_ 1057 VCU_DisChgSOCHighLim 255;
BA_ "GenSigStartValue" SG_ 1057 VCU_DisChgSOCHighLim 255;
BA_ "GenSigSendType" SG_ 1057 VCU_DisChgSOCHighLim 0;
BA_ "GenSigInvalidValue" SG_ 1057 VCU_DisChgSOCLowLim 255;
BA_ "GenSigStartValue" SG_ 1057 VCU_DisChgSOCLowLim 255;
BA_ "GenSigSendType" SG_ 1057 VCU_DisChgSOCLowLim 0;
BA_ "GenSigInvalidValue" SG_ 1057 VCU_ChgSocSetFed 255;
BA_ "GenSigStartValue" SG_ 1057 VCU_ChgSocSetFed 255;
BA_ "GenSigSendType" SG_ 1057 VCU_ChgSocSetFed 0;
BA_ "GenSigInvalidValue" SG_ 1057 VCU_EngyConsuPer10Km 4095;
BA_ "GenSigSendType" SG_ 1057 VCU_EngyConsuPer10Km 0;
BA_ "GenSigInvalidValue" SG_ 1057 VCU_EngyConsuPer25Km 4095;
BA_ "GenSigSendType" SG_ 1057 VCU_EngyConsuPer25Km 0;
BA_ "GenSigInvalidValue" SG_ 1057 VCU_EngyConsuPer50Km 4095;
BA_ "GenSigSendType" SG_ 1057 VCU_EngyConsuPer50Km 0;
BA_ "GenSigInvalidValue" SG_ 1057 VCU_EngyConsuPer100m 4095;
BA_ "GenSigSendType" SG_ 1057 VCU_EngyConsuPer100m 0;
BA_ "GenSigInvalidValue" SG_ 1057 VCU_DisChrgPwr 255;
BA_ "GenSigSendType" SG_ 1057 VCU_DisChrgPwr 0;
BA_ "GenSigSendType" SG_ 1057 VCU_BookChrgSetFailRes 0;
BA_ "GenSigSendType" SG_ 1057 VCU_BookChrgFailRes 0;
BA_ "GenSigSendType" SG_ 1057 VCU_HVILFault 0;
BA_ "GenSigInvalidValue" SG_ 1057 VCUExtendRang 1023;
BA_ "GenSigSendType" SG_ 1057 VCUExtendRang 0;
BA_ "GenSigSendType" SG_ 1057 VCU_KeepWarmFailReason 0;
BA_ "GenSigSendType" SG_ 1057 VCU_ExtremeEnergySavingModeAv 0;
BA_ "GenSigSendType" SG_ 1057 VCU_TowModeAvailable 0;
BA_ "GenSigSendType" SG_ 1057 VCU_StopModeSWStsResp 0;
BA_ "GenSigSendType" SG_ 1057 VCU_StopModeSWAllowed 0;
BA_ "GenSigSendType" SG_ 1057 VCU_ChgDisChgLedCtrl 0;
BA_ "GenSigInvalidValue" SG_ 1057 VCU_CPMaxVolt 255;
BA_ "GenSigSendType" SG_ 1057 VCU_CPMaxVolt 0;
BA_ "GenSigSendType" SG_ 1057 VCUExtremeEnergySavingModeReq 0;
BA_ "GenSigSendType" SG_ 1057 VCU_EpedalModeSts 0;
BA_ "GenSigSendType" SG_ 1057 VCU_BookChrgStsFb 0;
BA_ "GenSigSendType" SG_ 1057 VCU_HVNM 0;
BA_ "GenSigStartValue" SG_ 1057 VCU_DriveMode 6;
BA_ "ASIL" SG_ 1057 VCU_DriveMode 2;
BA_ "GenSigSendType" SG_ 1057 VCU_DriveMode 0;
BA_ "GenSigSendType" SG_ 1057 HCU_EnterForceEVFailRes 0;
BA_ "GenSigSendType" SG_ 1057 HCU_EngineSelfMaintain 0;
BA_ "GenSigSendType" SG_ 1057 HCU_EnterForceChrgFailRes 0;
BA_ "GenSigSendType" SG_ 1057 HCU_InStartRes 0;
BA_ "GenSigSendType" SG_ 1057 HCU_EnergyRegSetFed 0;
BA_ "GenSigInvalidValue" SG_ 1078 PLG_LatchSts 3;
BA_ "GenSigStartValue" SG_ 1078 PLG_LatchSts 2;
BA_ "GenSigSendType" SG_ 1078 PLG_LatchSts 0;
BA_ "GenSigSendType" SG_ 1086 VCU_8_CRC1 0;
BA_ "GenSigSendType" SG_ 1086 VCU_8_RollgCntr1 0;
BA_ "GenSigSendType" SG_ 1086 VCU_8_Resd1 0;
BA_ "GenSigSendType" SG_ 1086 VCU_OBCChgCurrentReq 0;
BA_ "GenSigSendType" SG_ 1086 VCU_OBCChgVoltageReq 0;
BA_ "GenSigSendType" SG_ 1086 VCU_OBCDischgPwrLimit 0;
BA_ "GenSigSendType" SG_ 1086 VCU_OBCDischgReq 0;
BA_ "GenSigSendType" SG_ 1086 VCU_8_CRC2 0;
BA_ "GenSigSendType" SG_ 1086 VCU_8_RollgCntr2 0;
BA_ "GenSigSendType" SG_ 1086 VCU_8_Resd2 0;
BA_ "GenSigSendType" SG_ 1086 VCU_OBCInnerDischgPwrLimit 0;
BA_ "GenSigSendType" SG_ 1086 VCU_OBCInnerDischgAllow 0;
BA_ "GenSigSendType" SG_ 1086 VCU_CLMSystemPowerLimit_43Eh 0;
BA_ "GenSigSendType" SG_ 1086 VCU_CLMEACAllow_43Eh 0;
BA_ "GenSigSendType" SG_ 1086 VCU_CLMHVHAllow_43Eh 0;
BA_ "GenSigSendType" SG_ 1086 VCU_CLMHVReady_43Eh 0;
BA_ "GenSigSendType" SG_ 1092 BNCM_11_EVSEConnectSts 0;
BA_ "GenSigSendType" SG_ 1096 TMS_ICAstsFed_448h 0;
BA_ "GenSigSendType" SG_ 1096 TMS_RemotekeyReq 0;
BA_ "GenSigSendType" SG_ 1096 TMS_TimedVentilationReq 0;
BA_ "GenSigSendType" SG_ 1111 EAC_HVILSts 0;
BA_ "GenSigSendType" SG_ 1111 EAC_ErrorLevel 0;
BA_ "GenSigSendType" SG_ 1117 HVH_ErrorLevel 0;
BA_ "GenSigStartValue" SG_ 1122 HVH_DC_curr 255;
BA_ "GenSigSendType" SG_ 1122 HVH_DC_curr 0;
BA_ "GenSigStartValue" SG_ 1122 HVH_HV_voltage 255;
BA_ "GenSigSendType" SG_ 1122 HVH_HV_voltage 0;
BA_ "GenSigSendType" SG_ 1122 PTC_2_HVILSts 0;
BA_ "GenSigSendType" SG_ 1127 CDU_1_CRC1 0;
BA_ "GenSigSendType" SG_ 1127 CDU_1_RollgCntr1 0;
BA_ "GenSigSendType" SG_ 1127 CDU_1_Resd1 0;
BA_ "GenSigInvalidValue" SG_ 1127 DCDC_HvVolt 65535;
BA_ "GenSigSendType" SG_ 1127 DCDC_HvVolt 0;
BA_ "GenSigInvalidValue" SG_ 1127 DCDC_HVCurr 65535;
BA_ "GenSigSendType" SG_ 1127 DCDC_HVCurr 0;
BA_ "GenSigSendType" SG_ 1127 DCDC_FaultCode 0;
BA_ "GenSigSendType" SG_ 1127 CDU_1_CRC2 0;
BA_ "GenSigSendType" SG_ 1127 CDU_1_RollgCntr2 0;
BA_ "GenSigSendType" SG_ 1127 CDU_1_Resd2 0;
BA_ "GenSigInvalidValue" SG_ 1127 DCDC_LvSideCurr 4095;
BA_ "GenSigSendType" SG_ 1127 DCDC_LvSideCurr 0;
BA_ "GenSigSendType" SG_ 1127 DCDC_OverTemp 0;
BA_ "GenSigInvalidValue" SG_ 1127 DCDC_LvSideVolt 2047;
BA_ "ASIL" SG_ 1127 DCDC_LvSideVolt 2;
BA_ "GenSigSendType" SG_ 1127 DCDC_LvSideVolt 0;
BA_ "GenSigSendType" SG_ 1127 DCDC_EnableSts 0;
BA_ "ASIL" SG_ 1127 DCDC_FaultLevelSts 2;
BA_ "GenSigSendType" SG_ 1127 DCDC_FaultLevelSts 0;
BA_ "GenSigInvalidValue" SG_ 1127 DCDC_LvSideCurrMax 4095;
BA_ "GenSigSendType" SG_ 1127 DCDC_LvSideCurrMax 0;
BA_ "GenSigSendType" SG_ 1137 ICC_BookChrgSetReq 2;
BA_ "GenSigSendType" SG_ 1137 ICC_BkChrgStartTimeYear 0;
BA_ "GenSigStartValue" SG_ 1137 ICC_BkChrgStartTimeDay 1;
BA_ "GenSigSendType" SG_ 1137 ICC_BkChrgStartTimeDay 0;
BA_ "GenSigInvalidValue" SG_ 1137 ICC_BkChrgStartTimeHour 31;
BA_ "GenSigSendType" SG_ 1137 ICC_BkChrgStartTimeHour 2;
BA_ "GenSigInvalidValue" SG_ 1137 ICC_BkChrgStartTimemMin 63;
BA_ "GenSigSendType" SG_ 1137 ICC_BkChrgStartTimemMin 2;
BA_ "GenSigInvalidValue" SG_ 1137 ICC_BkChrgDuration 2047;
BA_ "GenSigSendType" SG_ 1137 ICC_BkChrgDuration 2;
BA_ "GenSigStartValue" SG_ 1137 ICC_BkChrgStartTimeMonth 1;
BA_ "GenSigSendType" SG_ 1137 ICC_BkChrgStartTimeMonth 0;
BA_ "GenSigSendType" SG_ 1137 ICC_BkChrgCycleMon 0;
BA_ "GenSigSendType" SG_ 1137 ICC_StopChrgReq 2;
BA_ "GenSigSendType" SG_ 1137 ICC_BkChrgCycleType 0;
BA_ "GenSigSendType" SG_ 1137 ICC_BkChrgCycleFri 0;
BA_ "GenSigSendType" SG_ 1137 ICC_BkChrgCycleThur 0;
BA_ "GenSigSendType" SG_ 1137 ICC_BkChrgCycleWen 0;
BA_ "GenSigSendType" SG_ 1137 ICC_BkChrgCycleTues 0;
BA_ "GenSigSendType" SG_ 1137 ICC_BkChrgCycleSun 0;
BA_ "GenSigSendType" SG_ 1137 ICC_BkChrgCycleSat 0;
BA_ "GenSigStartValue" SG_ 1137 ICC_KeepWarmStrt 1;
BA_ "GenSigSendType" SG_ 1137 ICC_KeepWarmStrt 0;
BA_ "GenSigInvalidValue" SG_ 1137 ICC_KeepWarmStrtHour 31;
BA_ "GenSigSendType" SG_ 1137 ICC_KeepWarmStrtHour 2;
BA_ "GenSigInvalidValue" SG_ 1137 ICC_KeepWarmStrtMin 63;
BA_ "GenSigSendType" SG_ 1137 ICC_KeepWarmStrtMin 2;
BA_ "GenSigInvalidValue" SG_ 1137 ICC_PetmodeFb 3;
BA_ "GenSigSendType" SG_ 1137 ICC_PetmodeFb 0;
BA_ "GenSigSendType" SG_ 1137 ICC_SentinelModeFaultSts 0;
BA_ "GenSigSendType" SG_ 1137 ICC_SentinelModeWorkingSts 0;
BA_ "GenSigSendType" SG_ 1137 ICC_SentinelModeSwitchSts 0;
BA_ "GenSigSendType" SG_ 1137 ICC_SentinelModeExitReason 0;
BA_ "GenSigSendType" SG_ 1137 ICC_SentinelModeAlarmSts 0;
BA_ "GenSigSendType" SG_ 1137 ICC_PetModeWarn_2 0;
BA_ "GenSigSendType" SG_ 1137 ICM_FuelLevel 0;
BA_ "GenSigSendType" SG_ 1137 ICM_AverageVehicleSpeed 0;
BA_ "GenSigInvalidValue" SG_ 1137 ICM_DistenceToEmpty_Km 2047;
BA_ "GenSigSendType" SG_ 1137 ICM_DistenceToEmpty_Km 0;
BA_ "GenSigSendType" SG_ 1137 ICM_Maintenance_tips 0;
BA_ "GenSigSendType" SG_ 1137 ICM_FuelLevelFailSts 0;
BA_ "GenSigSendType" SG_ 1137 ICM_SumTrip 0;
BA_ "GenSigInvalidValue" SG_ 1142 HCU_4_G_AvgFuCns 499;
BA_ "GenSigSendType" SG_ 1142 HCU_4_G_AvgFuCns 0;
BA_ "GenSigInvalidValue" SG_ 1142 HCU_4_G_AvgEnergyCns 499;
BA_ "GenSigSendType" SG_ 1142 HCU_4_G_AvgEnergyCns 0;
BA_ "GenSigSendType" SG_ 1142 HCU_4_G_EDrvOnly 0;
BA_ "GenSigSendType" SG_ 1142 HCU_4_G_ForcedPrkgChrg 0;
BA_ "GenSigInvalidValue" SG_ 1142 HCU_4_G_SumEgyCns 511;
BA_ "GenSigSendType" SG_ 1142 HCU_4_G_SumEgyCns 0;
BA_ "GenSigInvalidValue" SG_ 1142 HCU_4_G_EngRunFuCns 511;
BA_ "GenSigSendType" SG_ 1142 HCU_4_G_EngRunFuCns 0;
BA_ "GenSigSendType" SG_ 1143 CDU_2_CRC1 0;
BA_ "GenSigSendType" SG_ 1143 CDU_2_RollgCntr1 0;
BA_ "GenSigSendType" SG_ 1143 CDU_2_Resd1 0;
BA_ "GenSigSendType" SG_ 1143 OBC_CC_ConnectSts 0;
BA_ "ASIL" SG_ 1143 DCDC_WorkingMode 2;
BA_ "GenSigSendType" SG_ 1143 DCDC_WorkingMode 0;
BA_ "GenSigSendType" SG_ 1143 OBC_InnerDischgReq 0;
BA_ "GenSigSendType" SG_ 1143 CDU_HVILFault 0;
BA_ "GenSigInvalidValue" SG_ 1144 ICC_HvBattKeepWarmSet 3;
BA_ "GenSigStartValue" SG_ 1144 ICC_HvBattKeepWarmSet 3;
BA_ "GenSigSendType" SG_ 1144 ICC_HvBattKeepWarmSet 2;
BA_ "GenSigSendType" SG_ 1144 ICC_CarSickRelfModeReq 2;
BA_ "GenSigSendType" SG_ 1144 ICC_HvBattKeepWarmActiveReq 2;
BA_ "GenSigSendType" SG_ 1155 ASU_3_LvlAdj_Restriction 0;
BA_ "GenSigSendType" SG_ 1167 ICC_KeyDriveModememory 2;
BA_ "GenSigSendType" SG_ 1167 ICC_DriveModeSet 2;
BA_ "GenSigSendType" SG_ 1167 ICC_DRIFTModeSetReq 2;
BA_ "GenSigSendType" SG_ 1167 ICC_EXPERTEIPBESPSet 2;
BA_ "GenSigSendType" SG_ 1167 ICC_EXPERTEcoSet 2;
BA_ "GenSigSendType" SG_ 1167 ICC_EXPERTNormSet 2;
BA_ "GenSigSendType" SG_ 1167 ICC_EXPERTSportSet 2;
BA_ "GenSigSendType" SG_ 1167 ICC_CrossaxisSet 2;
BA_ "GenSigSendType" SG_ 1167 ICC_EXPERTRWDSet 2;
BA_ "GenSigSendType" SG_ 1167 ICC_EXPERTAWDSet 2;
BA_ "GenSigSendType" SG_ 1167 ICC_EXPERTAutoSet 2;
BA_ "GenSigSendType" SG_ 1167 ICC_CLIMBSet 2;
BA_ "GenSigSendType" SG_ 1167 ICC_DriveModeExitSet 2;
BA_ "GenSigSendType" SG_ 1167 ICC_CCOSwtReq 2;
BA_ "GenSigSendType" SG_ 1167 ICC_TABSwtReq 2;
BA_ "GenSigInvalidValue" SG_ 1167 ICC_Confidencelevel 127;
BA_ "GenSigSendType" SG_ 1167 ICC_Confidencelevel 2;
BA_ "GenSigSendType" SG_ 1167 ICC_V2L_IntlDisChg 2;
BA_ "GenSigSendType" SG_ 1167 ICC_ExhibitionModeSwitch 2;
BA_ "GenSigSendType" SG_ 1167 ICC_TrailerMode 2;
BA_ "GenSigSendType" SG_ 1167 ICC_V2L_DisChgMem 2;
BA_ "GenSigSendType" SG_ 1167 ICC_DrivePowerDispSet 2;
BA_ "GenSigSendType" SG_ 1167 ICC_WLTC_to_CLTC_Mode 2;
BA_ "GenSigSendType" SG_ 1167 ICC_StopChrgnSwitch 2;
BA_ "GenSigSendType" SG_ 1167 ICC_StopChrgnMode 2;
BA_ "GenSigSendType" SG_ 1167 ICC_RegenerateLevelCtrl 2;
BA_ "GenSigSendType" SG_ 1167 ICC_SinglePedalMem 2;
BA_ "GenSigSendType" SG_ 1167 ICC_FuelDetnSwt 2;
BA_ "GenSigSendType" SG_ 1167 ICC_FuelDetnState 2;
BA_ "GenSigSendType" SG_ 1167 ICC_FuelDetnOpDefeated 2;
BA_ "GenSigSendType" SG_ 1167 ICC_HVDownRepairMode 2;
BA_ "GenSigSendType" SG_ 1167 ICC_UTURNSnowSet 2;
BA_ "GenSigSendType" SG_ 1167 ICC_UTURNSandSet 2;
BA_ "GenSigSendType" SG_ 1167 ICC_UTURNMudSet 2;
BA_ "GenSigSendType" SG_ 1167 ICC_UTURNGrassSet 2;
BA_ "GenSigSendType" SG_ 1167 ICC_DeepSnowSet_48Fh 2;
BA_ "GenSigSendType" SG_ 1167 ICC_LTCDispSet2 2;
BA_ "GenSigSendType" SG_ 1167 ICC_SetSocManage 2;
BA_ "GenSigSendType" SG_ 1167 ICC_WadeModeSet_48Fh 2;
BA_ "GenSigSendType" SG_ 1167 ICC_LightSandSet_48Fh 2;
VAL_ 258 BMS_PackVoltage 65534 "Abnormal" 65535 "Invalid";
VAL_ 258 BMS_PackCurrent 65534 "Abnormal" 65535 "Invalid";
VAL_ 258 BMS_HvBattSts 0 "Init" 1 "standby" 2 "Precharge" 3 "HVOn" 4 "AC charge Mode" 5 "DC charge Mode" 6 "Boost charging mode" 7 "PreHeat Mode" 8 "keep warm" 9 "powerdown" 10 "emergencypowerdown" 11 "fault" 12 "afterrun" 13 "Keep warm complete Mode" 14 "PreHeat complete Mode";
VAL_ 258 BMS_SysSelfCheck 1 "self_checking" 2 "flaut" 3 "no fault";
VAL_ 258 BMS_HVBattThermRunaway 0 "normal" 1 "warning" 2 "invalid";
VAL_ 258 BMS_ChargeVoltageReq 16382 "Error" 16383 "Init";
VAL_ 258 BMS_ChgCurrReq 16382 "Error" 16383 "Init";
VAL_ 258 BMS_InfraDcUActDc 16382 "Error" 16383 "Init";
VAL_ 258 BMS_InfraDcIActDc 16382 "Error" 16383 "Init";
VAL_ 258 BMS_HvBattDynChrgnILim 16382 "Error" 16383 "Init";
VAL_ 258 BMS_HvBattUChrgnLim 16382 "Error" 16383 "Init";
VAL_ 258 BMS_ChrgDcIAvl 16382 "Error" 16383 "Init";
VAL_ 258 BMS_DChrgAPlusSt 0 "not active" 1 "active";
VAL_ 258 BMS_ChrgDcCnctrDetd 0 "Init" 1 "Connector not detected" 2 "Connector detected" 3 "SNS/Fault";
VAL_ 258 BMS_DCChgMode 0 "Default" 1 "HandOver" 2 "ParaConfig" 3 "Chging" 4 "ChgEnd" 5 "ChgWaring" 6 "ChgFault";
VAL_ 258 BMS_ChrgDcChrgnFltStopReas 0 "no fault" 1 "End by Infrastructure fault" 2 "BMS fault" 3 "CC2 fault" 4 "DC charge not allowd because low temperature" 5 "VCU fault" 6 "Boost fault" 7 "Other fault";
VAL_ 258 BMS_ChgRemTime 2046 "SNA/Fault" 2047 "Init";
VAL_ 258 BMS_ChargeRequest_Mode 0 "No request" 1 "AC Charging request" 2 "Boost Charging request" 3 "DC Fast Charging request" 4 "Charge precharge request" 5 "Reserved" 6 "Reserved" 7 "Reserved" 8 "Reserved" 9 "Reserved" 10 "Reserved" 11 "Reserved" 12 "Reserved" 13 "Reserved" 14 "Reserved" 15 "init";
VAL_ 258 BMS_StateOfEnergy 65534 "Abnormal" 65535 "Invalid";
VAL_ 258 BMS_BlanceState 0 "Balance OFF" 1 "Balance ON";
VAL_ 258 BMS_IsolationFault 0 "no fault" 1 "Fault L1" 2 "Fault L2" 3 "Fault L3";
VAL_ 258 BMS_HVILFault_DC 0 "No fault" 1 "fault";
VAL_ 258 BMS_SOCDis 16382 "Abnormal" 16383 "Invalid";
VAL_ 258 BMS_InfraDcIActDcMin 16382 "Error" 16383 "Init";
VAL_ 369 VCU_BMSPreheatKeepWarmAllow 0 "None" 1 "Allow AC preheat" 2 "Allow AC preheat exit" 3 "Allow keep warm" 4 "Allow keep warm exit" 5 "Allow DC Preheat" 6 "Allow DC Preheat Exit";
VAL_ 369 VCU_BMSAcChrgPerm 0 "Not Allow" 1 "Allow";
VAL_ 369 VCU_BMSStsReq_Reserved 0 "None" 1 "Allow AC preheat" 2 "Allow AC preheat exit" 3 "Allow keep warm" 4 "Allow keep warm exit" 5 "Allow DC charge" 6 "Allow AC charge" 7 "Reserved" 8 "Reserved" 9 "Reserved" 10 "Reserved" 11 "Reserved" 12 "Reserved" 13 "Reserved" 14 "Reserved" 15 "Reserved";
VAL_ 369 VCU_ElectronicLockReq 0 "Unlock" 1 "Lock" 2 "No request";
VAL_ 369 VCU_ErrLvl 0 "No Error" 1 "Err_level1" 2 "Err_level2" 3 "Err_level3" 4 "Err_level4" 5 "Err_level5" 6 "Err_level6" 7 "Err_level7" 8 "Err_level8" 9 "Err_level9" 10 "Err_level10" 11 "Err_level11" 12 "Err_level12" 13 "Err_level13" 14 "Err_level14" 15 "Err_level15";
VAL_ 369 VCU_PwtCoolingLvl_171h 0 "L0" 1 "L1" 2 "L2" 3 "L3" 4 "L4" 5 "Reserved" 6 "Reserved" 7 "Reserved";
VAL_ 385 VCU_BMSVehDcChrgnIDmd 16382 "Error" 16383 "Invalid";
VAL_ 385 VCU_BMSHVreq 0 "Disconnect" 1 "Connect" 2 "Reserved" 3 "Reserved";
VAL_ 385 VCU_BMSVehDcChrgnUDmd 16382 "Error" 16383 "Invalid";
VAL_ 385 VCU_TargetSOC 1022 "Error" 1023 "Invalid";
VAL_ 385 VCU_BMSDcChrgPerm 0 "Not Allow" 1 "Allow";
VAL_ 401 VCU_DCDCEnable 0 "Disable" 1 "Enable";
VAL_ 513 MFSL_UP_SW 0 "Not_action" 1 "Pressed" 2 "Stuck" 3 "invalid";
VAL_ 513 MFSL_DW_SW 0 "Not_action" 1 "Pressed" 2 "Stuck" 3 "invalid";
VAL_ 513 MFSL_OK_SW 0 "Not_action" 1 "Pressed" 2 "Stuck" 3 "invalid";
VAL_ 515 EVCC_ElectronicLockSts 0 "Unlock" 1 "Lock" 2 "Lock error" 3 "Unlock error" 4 "Elock error";
VAL_ 515 EVCC_GunConnectSt_203h 0 "Disconnect" 1 "Connect" 2 "The connection is abnormal." 3 "Invalid";
VAL_ 515 EVCC_COUNTRY_SUPPORT 0 "init" 1 "EU" 2 "USA" 3 "EU+USA";
VAL_ 515 EVCC_CP_DutyCycleFault 0 "No fault" 1 "Fault";
VAL_ 515 EVCC_CC_ConnectSts 0 "Not connected" 1 "Connected" 2 "Partial connected" 3 "Invalid";
VAL_ 515 EVCC_S2Swtsts 0 "open" 1 "close" 2 "reserved" 3 "Error";
VAL_ 515 EVCC_CPSts 0 "no CP signal" 1 "CP is 12V high level" 2 "CP is 9V high level" 3 "CP is 9V PWM" 4 "CP is 6V PWM" 5 "CP is 6V high level" 6 "CP is 12V PWM" 7 "CP signal is abnormal";
VAL_ 515 EVCC_ChargeType 0 "Unknown" 1 "AC charge ( basic signal )" 2 "AC charge ( ISO15118 )" 3 "DC charge ( ISO15118 )" 4 "DC charge ( DIN70121 )" 5 "V2L( AC )";
VAL_ 515 EVCC_CC2_Alarm 0 "Normal" 1 "Fault";
VAL_ 515 EVCC_CC2_ConnectSts 0 "Not connected" 1 "Connected" 2 "Partial connected" 3 "Invalid";
VAL_ 515 EVCC_CC_ConnectDischarSts 0 "Not connected" 1 "Connected" 2 "Partial connected" 3 "Invalid";
VAL_ 515 EVCC_CPMaxVolt 1023 "Invalid";
VAL_ 515 EVCC_FaultLevel 0 "Normal" 1 "Level1" 2 "Level2" 3 "Level3" 4 "Reseverd" 5 "Reseverd" 6 "Reseverd" 7 "Reseverd";
VAL_ 515 EVCC_DCPlusTemp 255 "Invalid";
VAL_ 515 EVCC_DCMinusTemp 255 "Invalid";
VAL_ 520 BMS_C2Target_Chg_Voltage 65535 "Invalid";
VAL_ 520 BMS_HvBattThermReqLevel 0 "No request" 1 "Battery  heating L1" 2 "Battery heating L2" 3 "Battery heating L3" 4 "Battery cooling L1" 5 "Battery cooling L2" 6 "Battery cooling L3" 7 "Battery heating L4" 8 "Battery cooling L4" 9 "reserved" 10 "reserved" 11 "reserved" 12 "reserved" 13 "reserved" 14 "reserved" 15 "reserved";
VAL_ 520 BMS_NV_relay_Sts 0 "open" 1 "closed" 2 "Stuck Open" 3 "Stuck Closed" 4 "SCB" 5 "SCG" 6 "OpenLoad";
VAL_ 520 BMS_PV_relay_Sts 0 "open" 1 "closed" 2 "Stuck Open" 3 "Stuck Closed" 4 "SCB" 5 "SCG" 6 "OpenLoad";
VAL_ 520 BMS_QCP_relay_Sts 0 "open" 1 "closed" 2 "Stuck Open" 3 "Stuck Closed" 4 "SCB" 5 "SCG" 6 "OpenLoad";
VAL_ 520 BMS_QCN_relay_Sts 0 "open" 1 "closed" 2 "Stuck Open" 3 "Stuck Closed" 4 "SCB" 5 "SCG" 6 "OpenLoad";
VAL_ 520 BMS_Prechage_relay_Sts 0 "open" 1 "closed" 2 "Stuck Open" 3 "Stuck Closed" 4 "SCB" 5 "SCG" 6 "OpenLoad";
VAL_ 520 BMS_HvBattThermReqMode 0 "No request" 1 "Battery  heating request" 2 "Balancing request" 3 "Battery cooling request" 4 "Battery cooling MAX request" 5 "KeepWarm  Heating request" 6 "Exit KeepWarm  Heating request" 7 "AC preheating request" 8 "AC exit preheating request" 9 "DC preheating request" 10 "DC exit preheating request" 11 "reserved" 12 "reserved" 13 "reserved" 14 "reserved";
VAL_ 520 BMS_ClntTHvBattIn 254 "Init" 255 "Error";
VAL_ 520 BMS_ClntTHvBattOut 254 "Init" 255 "Error";
VAL_ 520 BMS_HvBattClntInTReq 126 "Init" 127 "Error";
VAL_ 520 BMS_HvBattClntFlowReq 126 "Init" 127 "Error";
VAL_ 520 BMS_HvBattAvgT 254 "Init" 255 "Error";
VAL_ 520 BMS_HvBattMaxT 254 "Abnormal" 255 "Invalid";
VAL_ 520 BMS_HvBattMinT 254 "Abnormal" 255 "Invalid";
VAL_ 520 BMS_OutPosU 16382 "Abnormal" 16383 "Invalid";
VAL_ 520 BMS_OutNegU 16382 "Abnormal" 16383 "Invalid";
VAL_ 520 BMS_outQCPosU 16382 "Abnormal" 16383 "Invalid";
VAL_ 520 BMS_outQCNegU 16382 "Abnormal" 16383 "Invalid";
VAL_ 520 BMS_Middlesplit_relay_Sts 0 "open" 1 "closed" 2 "Stuck Open" 3 "Stuck Closed" 4 "SCB" 5 "SCG" 6 "OpenLoad";
VAL_ 523 BMS_HvBattPMaxReChrgLim 16382 "Error" 16383 "Init";
VAL_ 523 BMS_HvBattPMaxDchaLim 16382 "Error" 16383 "Init";
VAL_ 523 BMS_KL30Volt 2047 "Invalid";
VAL_ 523 BMS_kL87Volt 2047 "Invalid";
VAL_ 523 BMS_HvBattUDchaLim 16382 "Error" 16383 "Init";
VAL_ 523 BMSH_MaxChgPwrPeak 4095 "Invalid";
VAL_ 523 BMSH_MaxDchgPwrPeak 4095 "Invalid";
VAL_ 563 VCU_6_G_PRNDGearAct 0 "Init" 1 "P" 2 "R" 3 "N" 4 "D" 5 "Reserved" 6 "Reserved" 7 "Reserved";
VAL_ 563 VCU_6_G_GasPedalPositionInVD 0 "Valid" 1 "Invalid";
VAL_ 638 FRZCU_HoodSts 0 "Close" 1 "Ajar" 2 "full_open" 3 "Reserved";
VAL_ 683 PassDoorSts_2ABh 0 "Close" 1 "Ajar" 2 "full_open" 3 "Reserved";
VAL_ 683 PassRearDoorSts_2ABh 0 "Close" 1 "Ajar" 2 "full_open" 3 "Reserved";
VAL_ 745 DCB_1_HVILSts 0 "Not Fault" 1 "Fault";
VAL_ 745 DCB_1_BoostNegRelaySts 0 "Open" 1 "Close" 2 "Stuck Open" 3 "Stuck Close" 4 "Reserved" 5 "Reserved" 6 "Reserved" 7 "Reserved";
VAL_ 745 DCB_1_WorkingSts 0 "INIT" 1 "Standby" 2 "DCCharge" 3 "BoostCharge" 4 "Fault" 5 "Reserved" 6 "Reserved" 7 "Reserved";
VAL_ 745 DCB_1_NegFastChgRelaySts 0 "Open" 1 "Close" 2 "Stuck Open" 3 "Stuck Close" 4 "Reserved" 5 "Reserved" 6 "Reserved" 7 "Reserved";
VAL_ 745 DCB_1_C2RelaySts 0 "Open" 1 "Close" 2 "Stuck Open" 3 "Stuck Close" 4 "Reserved" 5 "Reserved" 6 "Reserved" 7 "Reserved";
VAL_ 745 DCB_1_ErrorLevel 0 "Normal" 1 "Level1" 2 "Level2" 3 "Level3" 4 "Level4" 5 "Reseverd" 6 "Reseverd" 7 "Reseverd";
VAL_ 745 DCB_1_PosFastChgRelaySts 0 "Open" 1 "Close" 2 "Stuck Open" 3 "Stuck Close" 4 "Reserved" 5 "Reserved" 6 "Reserved" 7 "Reserved";
VAL_ 745 DCB_1_BoostPosRelaySts 0 "Open" 1 "Close" 2 "Stuck Open" 3 "Stuck Close" 4 "Reserved" 5 "Reserved" 6 "Reserved" 7 "Reserved";
VAL_ 789 ATCM_DriveModeSw 0 "Not Active" 1 "Plus" 2 "Minus" 3 "Reserved";
VAL_ 789 ATCM_XModeSw 0 "Not_Active" 1 "ON" 2 "OFF" 3 "Reserved";
VAL_ 789 ATCM_PowerModeSw 0 "Not_Active" 1 "EV" 2 "HEV" 3 "EV+";
VAL_ 789 ACTM_4LModeSW 0 "Release" 1 "Press";
VAL_ 789 ATCM_CCOSwtReq 0 "Release" 1 "Press";
VAL_ 789 ATCM_SwitchUTurnModeSet 0 "Release" 1 "Press";
VAL_ 789 ATCM_FrontEDL 0 "Release" 1 "Press";
VAL_ 789 ATCM_RearEDL 0 "Release" 1 "Press";
VAL_ 789 ATCM_ASU_LiftSet 0 "Release" 1 "Plus";
VAL_ 789 ATCM_ASU_LowerSet 0 "Not Active" 1 "Minus";
VAL_ 789 ATCM_TABSwtReq 0 "Release" 1 "Press";
VAL_ 789 ATCM_EngyRec_SW 0 "Release" 1 "Press";
VAL_ 859 FLZCU_IRCHV_Req 0 "not_active" 1 "HVON" 2 "HVOFF" 3 "Reserved";
VAL_ 991 ErrorLevel 0 "No_Error" 1 "Reset" 2 "Inhibit_Operation" 3 "Shutdown";
VAL_ 991 TMS_HV_Req 0 "Not_active" 1 "HVON" 2 "HVOFF" 3 "Reserved";
VAL_ 991 TMS_EngingstartReq 0 "NO_request" 1 "start_request";
VAL_ 1024 FRZCU_OnekeyHVoffSwtst 0 "Not Pressed" 1 "Pressed" 2 "Stuck" 3 "Not Used";
VAL_ 1029 LBMS_PackExtUVld 0 "Invalid" 1 "Valid";
VAL_ 1029 LBMS_PackTVld 0 "Invalid" 1 "Valid";
VAL_ 1034 HCU_VehicleState 0 "Init" 1 "Sleep" 2 "PowerUp" 3 "Charging" 4 "Reserved" 5 "Reserved" 6 "Reserved" 7 "Reserved" 8 "Reserved" 9 "Reserved" 10 "Reserved" 11 "Reserved" 12 "Reserved" 13 "Reserved" 14 "Reserved" 15 "Reserved";
VAL_ 1034 HCU_RunMode 0 "EV" 1 "HEV" 2 "ICE" 3 "Reserved";
VAL_ 1034 HCU_PwrTrnModeDisp 0 "Static" 1 "Regenerating" 2 "ICE Only" 3 "EV Only" 4 "Hybrid Mode" 5 "REEV" 6 "Reserved" 7 "Reserved";
VAL_ 1034 HCU_IntelligentPowerSupply 0 "Charge Inhibit" 1 "No Request" 2 "Charging" 3 "Charge Complete" 4 "Reserved" 5 "Reserved" 6 "Reserved" 7 "Reserved";
VAL_ 1034 HCU_PowerModeFed 0 "Not Active" 1 "EV" 2 "HEV" 3 "EV+";
VAL_ 1034 HCU_LimpHomeMode 0 "Normal Mode" 1 "E-Drive Only" 2 "ICE-Drive Only" 3 "REEV Only";
VAL_ 1034 HCU_ISGRegenerateSts 0 "Not Active" 1 "Active";
VAL_ 1034 HCU_EmOverSpdWarn 0 "Not Warn" 1 "Warn";
VAL_ 1034 HCU_PowertrainFault 0 "No Fault" 1 "Fault";
VAL_ 1034 HCU_PrePTReady 0 "OFF" 1 "ON";
VAL_ 1034 HCU_PowerModeChangeFail 0 "NOT FAIL" 1 "FAIL";
VAL_ 1034 BMSH_MILReq 0 "No request" 1 "Request";
VAL_ 1034 TMF_EngMilLampReq 0 "No request" 1 "Request";
VAL_ 1034 TMR_EngMilLampReq 0 "No request" 1 "Request";
VAL_ 1034 HCU_MILReq 0 "No request" 1 "Request";
VAL_ 1034 HCU_HVReady 0 "LmpOFF" 1 "LmpON";
VAL_ 1034 HCU_PTReady 0 "LmpOFF" 1 "LmpON";
VAL_ 1034 HCU_ChargingSts 0 "No Charging" 1 "Stop Charging" 2 "Run Charging" 3 "Charge Complete";
VAL_ 1034 HCU_PtSts 0 "Powertrain Not Active" 1 "Park Engine Off" 2 "E Drive" 3 "Engine Starting" 4 "Engine Stopping" 5 "Series Charging" 6 "Idle Charging" 7 "Idle No Charging" 8 "Motor Drag Engine" 9 "Reserved" 10 "Reserved" 11 "Reserved" 12 "Reserved" 13 "Reserved" 14 "Reserved" 15 "Reserved";
VAL_ 1034 HCU_InHbStrtRes 0 "default" 1 "PT fault" 2 "Hood open" 3 "fuel door open" 4 "Insufficient torque" 5 "out of fuel" 6 "out of speed" 7 "third start failed" 8 "gun connect" 9 "reserve" 10 "reserve" 11 "reserve" 12 "reserve" 13 "reserve" 14 "reserve" 15 "reserve";
VAL_ 1035 VCC_1_OTASts 0 "Normal Status" 1 "OTA Status";
VAL_ 1038 LBMS_SOC 126 "Initial Value" 127 "invalid";
VAL_ 1038 LBMS_ReChrgReq 0 "Initial/Default" 1 "SOCChar Req" 2 "VoltChar Req" 3 "InvalidSOCChar Req" 4 "CharQuit Req" 5 "Reserved" 6 "Reserved" 7 "Invalid";
VAL_ 1039 LBMS_ChargeSts 0 "Initial" 1 "Replenishing power" 2 "Recharge fault" 3 "Complete recharge" 4 "Reserved" 5 "Reserved" 6 "Reserved" 7 "Reserved" 8 "Reserved" 9 "Reserved" 10 "Reserved" 11 "Reserved" 12 "Reserved" 13 "Reserved" 14 "Reserved" 15 "Invalid";
VAL_ 1039 LBMS_ChargeFlt 0 "No Fault" 1 "Fault";
VAL_ 1039 LBMS_ChargeEnable 0 "Disable" 1 "Enable";
VAL_ 1044 HCU_RangeAval 2047 "Invalid";
VAL_ 1044 HCU_EnergyFlow 0 "OFF" 1 "Ready" 2 "2WD_EV" 3 "4WD_EV" 4 "2WD_ExtendRangeDisCharge" 5 "2WD_ExtendRangeCharge" 6 "4WD_ExtendRangeDisCharge" 7 "4WD_ExtendRangeCharge" 8 "2WD_Parallel" 9 "4WD_Parallel" 10 "Engine" 11 "Running_Generate" 12 "Parking_Generate" 13 "2WD_ReGenerateBrake" 14 "4WD_ReGenerateBrake" 15 "Charge";
VAL_ 1044 HCU_ReplaceWarmupCycle 0 "Not Active" 1 "Active";
VAL_ 1044 HCU_CLMOBDClearReq 0 "No Request" 1 "Request";
VAL_ 1044 HCU_2_G_ChgIncOper 0 "Not Active" 1 "active";
VAL_ 1044 HCU_2_G_ChgDepOper 0 "Not Active" 1 "active";
VAL_ 1044 HCU_SocManageFed_414h 0 "Default" 1 "Pure electricity priority mode" 2 "Fuel priority mode" 3 "SOC hold mode" 4 "Reserved" 5 "Reserved" 6 "Reserved" 7 "Reserved";
VAL_ 1044 HCU_SetSOCFed 255 "Invalid";
VAL_ 1044 VCU_BrakePedalStsValidData 0 "Valid" 1 "Not_Valid";
VAL_ 1044 VCU_BrakePedalSts 0 "Not_applied" 1 "Applied";
VAL_ 1044 HCU_EnergyFlowREEV 0 "OFF" 1 "during Start" 2 "Idle" 3 "Running_Generate" 4 "Reserved" 5 "Reserved" 6 "Reserved" 7 "Reserved" 8 "Reserved" 9 "Reserved" 10 "Reserved" 11 "Reserved" 12 "Reserved" 13 "Reserved" 14 "Reserved" 15 "Reserved" 16 "Reserved" 17 "Reserved" 18 "Reserved" 19 "Reserved" 20 "Reserved" 21 "Reserved" 22 "Reserved" 23 "Reserved" 24 "Reserved" 25 "Reserved" 26 "Reserved" 27 "Reserved" 28 "Reserved" 29 "Reserved" 30 "Reserved" 31 "Reserved";
VAL_ 1044 HCU_EmissionDetection 0 "Not Active" 1 "Active";
VAL_ 1044 HCU_2_G_IntrptGpfRgtvSt 0 "Not Active" 1 "Interrupt" 2 "Reserved" 3 "Reserved";
VAL_ 1044 HCU_2_G_LowBatteryInfo 0 "Not Active" 1 "NoRequest" 2 "Request" 3 "Sail Request";
VAL_ 1044 HCU_2_G_LowBatteryLowFuelInfo 0 "Not Active" 1 "NoRequest" 2 "Request" 3 "Reserved";
VAL_ 1044 HCU_2_G_HighTempLimit 0 "Not Active" 1 "Nolimit" 2 "limit" 3 "Reserved";
VAL_ 1045 TBOX_OTAHV_Req_415h 0 "Not active" 1 "HVON" 2 "HVOFF" 3 "Reserved";
VAL_ 1055 BMSH_MILReq_41Fh 0 "Inactive" 1 "Active";
VAL_ 1055 BMS_HvBattUnderTemperature 0 "no fault" 1 "Fault";
VAL_ 1055 BMS_ErrorLevel 0 "No_HvBattError" 1 "HvBattFaultLevel 1" 2 "HvBattFaultLevel 2" 3 "HvBattFaultLevel 3" 4 "HvBattFaultLevel 4" 5 "HvBattFaultLevel 5" 6 "HvBattFaultLevel 6" 7 "HvBattFaultLevel 7" 8 "HvBattFaultLevel 8";
VAL_ 1055 BMS_PwrDerateFlg 0 "inactive" 1 "Vtg_100 active" 2 "Vtg_0 active";
VAL_ 1057 VCU_shfChk 0 "LampOff" 1 "LampON";
VAL_ 1057 VCU_PowerLimitSOCLow 0 "NoLimit" 1 "DrvPwLimit" 2 "AcPwLimit" 3 "PTCPwLimit" 4 "DCDCPwLimit" 5 "Reserved";
VAL_ 1057 VCU_MCU_MilLampReq 0 "No request" 1 "Request";
VAL_ 1057 VCU_OPDinfo 0 "No request" 1 "OPD Inactive" 2 "OPD Not Allowed" 3 "Stop Mode Inactive" 4 "Stop Not Allowed" 5 "Reserved" 6 "Reserved" 7 "Reserved";
VAL_ 1057 VCU_ePTDrvPowerPcent 255 "Invalid";
VAL_ 1057 VCU_TowingMode 0 "NotActive" 1 "Active" 2 "Reserved";
VAL_ 1057 VCU_EgyRegenLevelHighAllowed 0 "Not Allowed" 1 "Allowed" 2 "High" 3 "Reserved";
VAL_ 1057 VCU_SportDriveModeAvailable 0 "Available" 1 "NotAvailable";
VAL_ 1057 VCU_RainSnowDriveModeAvailable 0 "Available" 1 "NotAvailable";
VAL_ 1057 VCU_OffRoadDriveModeAvailable 0 "Available" 1 "NotAvailable";
VAL_ 1057 VCU_CampAvailable 0 "Not Available" 1 "Available";
VAL_ 1057 VCU_DisChgSOCHighLim 255 "Invalid";
VAL_ 1057 VCU_DisChgSOCLowLim 255 "Invalid";
VAL_ 1057 VCU_EngyConsuPer10Km 4095 "Invalid";
VAL_ 1057 VCU_EngyConsuPer25Km 4095 "Invalid";
VAL_ 1057 VCU_EngyConsuPer50Km 4095 "Invalid";
VAL_ 1057 VCU_EngyConsuPer100m 4095 "Invalid";
VAL_ 1057 VCU_BookChrgSetFailRes 0 "Default" 1 "OBC Fault" 2 "HvBatt Fault" 3 "DCDC Fault" 4 "Vehicle Fault" 5 "Reserved" 6 "Reserved" 7 "Reserved";
VAL_ 1057 VCU_BookChrgFailRes 0 "Default" 1 "OBC Fault" 2 "HvBatt Fault" 3 "DCDC Fault" 4 "Vehicle Fault" 5 "ChargeStationFault" 6 "BNCMfault" 7 "EVSEandBNCMConnectFault" 8 "Reserved";
VAL_ 1057 VCU_HVILFault 0 "No fault" 1 "Fault";
VAL_ 1057 VCUExtendRang 1023 "Invalid";
VAL_ 1057 VCU_KeepWarmFailReason 0 "default" 1 "ChargeLineNotConnect" 2 "WarmNoNeed" 3 "VehicleFault" 4 "ChargeStationFault" 5 "BNCM fault" 6 "EVSEAuthrizeFail" 7 "Charging" 8 "PreHeating" 9 "Reserved" 10 "Reserved";
VAL_ 1057 VCU_ExtremeEnergySavingModeAv 0 "Unavailable" 1 "Available";
VAL_ 1057 VCU_TowModeAvailable 0 "Available" 1 "NotAvailable";
VAL_ 1057 VCU_StopModeSWStsResp 0 "Reserved" 1 "Creep" 2 "stop" 3 "Reserved";
VAL_ 1057 VCU_StopModeSWAllowed 0 "Not Allowed" 1 "Allowed";
VAL_ 1057 VCU_ChgDisChgLedCtrl 0 "Default(PortClose)" 1 "PortOpen" 2 "WaitingStart" 3 "BookChrgWaiting" 4 "PreHeat" 5 "KeepWarm" 6 "Charging" 7 "ChargePause" 8 "DisCharging" 9 "ChargeComplete" 10 "ChargeFault" 11 "ErrorConnection";
VAL_ 1057 VCU_CPMaxVolt 255 "Invalid";
VAL_ 1057 VCUExtremeEnergySavingModeReq 0 "NoRequest" 1 "Request_ADSoff" 2 "Request_ADSon";
VAL_ 1057 VCU_EpedalModeSts 0 "OFF" 1 "ON";
VAL_ 1057 VCU_BookChrgStsFb 0 "Default" 1 "Charging" 2 "ChargeFinished" 3 "Reserved";
VAL_ 1057 VCU_HVNM 0 "No Request" 1 "Request";
VAL_ 1057 VCU_DriveMode 0 "ECO" 1 "NORMAL" 2 "SPORT" 3 "RainSNOW" 4 "MUD(Res)" 5 "Offroad" 6 "Individual(Res)" 7 "SAND(Res)";
VAL_ 1057 HCU_EnterForceEVFailRes 0 "defaut" 1 "SOC Low" 2 "HVBattPwrLow" 3 "EngineAutoStrt" 4 "Reserved" 5 "Reserved" 6 "Reserved" 7 "Reserved";
VAL_ 1057 HCU_EngineSelfMaintain 0 "Not Active" 1 "Active" 2 "Reserved" 3 "Reserved";
VAL_ 1057 HCU_EnterForceChrgFailRes 0 "defaut" 1 "Fuel Empty" 2 "Engine Fault" 3 "ISG Fault" 4 "HVBattFault" 5 "SOC High" 6 "PTFault" 7 "Reserved";
VAL_ 1057 HCU_InStartRes 0 "defaut" 1 "Fuel Empty" 2 "Engine Fault" 3 "ISG Fault" 4 "BMSFault" 5 "PTFault" 6 "Reserved" 7 "Reserved";
VAL_ 1078 PLG_LatchSts 0 "Open" 1 "Secondary" 2 "Latched" 3 "Initializing";
VAL_ 1086 VCU_OBCDischgReq 0 "No Req" 1 "Req";
VAL_ 1086 VCU_OBCInnerDischgAllow 0 "Not Allow" 1 "Allow";
VAL_ 1086 VCU_CLMEACAllow_43Eh 0 "Unable" 1 "Enable";
VAL_ 1086 VCU_CLMHVHAllow_43Eh 0 "Unable" 1 "Enable";
VAL_ 1086 VCU_CLMHVReady_43Eh 0 "LmpOFF" 1 "LmpON";
VAL_ 1092 BNCM_11_EVSEConnectSts 0 "NotConnect" 1 "ConnectButAuthrizeFail" 2 "ConnectAndAuthrized" 3 "Reserved";
VAL_ 1096 TMS_ICAstsFed_448h 0 "Not Active" 1 "Open" 2 "Close" 3 "Fault";
VAL_ 1096 TMS_RemotekeyReq 0 "Not Active" 1 "Request" 2 "No Request" 3 "Failed to turn on" 4 "Function terminated" 5 "Reserved" 6 "Reserved" 7 "Reserved";
VAL_ 1096 TMS_TimedVentilationReq 0 "Not Active" 1 "Request" 2 "No Request" 3 "Failed to turn on" 4 "Function terminated" 5 "Reserved" 6 "Reserved" 7 "Reserved";
VAL_ 1111 EAC_HVILSts 0 "No Fault" 1 "Fault";
VAL_ 1111 EAC_ErrorLevel 0 "No Fault" 1 "Level_1" 2 "Level_2" 3 "Level_3" 4 "Level_4";
VAL_ 1117 HVH_ErrorLevel 0 "No Fault" 1 "Level_1" 2 "Level_2" 3 "Level_3" 4 "Level_4";
VAL_ 1122 PTC_2_HVILSts 0 "No Fault" 1 "Fault";
VAL_ 1127 DCDC_HvVolt 65535 "Invalid";
VAL_ 1127 DCDC_HVCurr 65535 "Invalid";
VAL_ 1127 DCDC_LvSideCurr 4095 "Invalid";
VAL_ 1127 DCDC_OverTemp 0 "No fault" 1 "Fault";
VAL_ 1127 DCDC_LvSideVolt 2047 "Invalid";
VAL_ 1127 DCDC_EnableSts 0 "Disable" 1 "Enable";
VAL_ 1127 DCDC_FaultLevelSts 0 "No fault" 1 "Lever1 fault" 2 "Lever2 fault" 3 "Lever3 fault" 4 "Lever4 fault" 5 "Reserved" 6 "Reserved" 7 "Reserved";
VAL_ 1127 DCDC_LvSideCurrMax 4095 "Invalid";
VAL_ 1137 ICC_BookChrgSetReq 0 "default" 1 "BookSet" 2 "CancellBook" 3 "Reserved";
VAL_ 1137 ICC_BkChrgCycleMon 0 "Not active" 1 "Active";
VAL_ 1137 ICC_StopChrgReq 0 "Not Active" 1 "Active";
VAL_ 1137 ICC_BkChrgCycleType 0 "default" 1 "Once" 2 "EveryDay" 3 "WorkDay" 4 "Reserved" 5 "Reserved";
VAL_ 1137 ICC_BkChrgCycleFri 0 "Not active" 1 "Active";
VAL_ 1137 ICC_BkChrgCycleThur 0 "Not active" 1 "Active";
VAL_ 1137 ICC_BkChrgCycleWen 0 "Not active" 1 "Active";
VAL_ 1137 ICC_BkChrgCycleTues 0 "Not active" 1 "Active";
VAL_ 1137 ICC_BkChrgCycleSun 0 "Not active" 1 "Active";
VAL_ 1137 ICC_BkChrgCycleSat 0 "Not active" 1 "Active";
VAL_ 1137 ICC_PetmodeFb 0 "Not active" 1 "ON" 2 "OFF" 3 "Invalid";
VAL_ 1137 ICC_SentinelModeFaultSts 0 "Not Warming" 1 "Artificial occlusion" 2 "Rain and snow cover" 3 "Reserved";
VAL_ 1137 ICC_SentinelModeWorkingSts 0 "Not Active" 1 "Active" 2 "LowSOC" 3 "HVNotReady" 4 "HVFault" 5 "MirrorUnFold" 6 "CameraFault" 7 "LowBatVolt" 8 "OTA";
VAL_ 1137 ICC_SentinelModeSwitchSts 0 "Not active" 1 "ON" 2 "OFF" 3 "Reserved";
VAL_ 1137 ICC_SentinelModeExitReason 0 "Normal" 1 "LowSOC" 2 "HVNotReady" 3 "HVFault" 4 "MirrorUnFold" 5 "CameraFault" 6 "LowBatVolt" 7 "OTA";
VAL_ 1137 ICC_SentinelModeAlarmSts 0 "Not Alarm" 1 "Level 1" 2 "Level 2" 3 "Level 3";
VAL_ 1137 ICC_PetModeWarn_2 0 "Not Active" 1 "High Voltage Battery Low" 2 "TMS Abnormal" 3 "High Pressure Abnormal" 4 "Low Voltage Battery Low" 5 "High Voltage Battery Less Than 15%" 6 "High Voltage Battery Less Than 12%" 7 "Time Long Warning" 8 "Vehicle charging" 9 "Vehicle Disarming" 10 "Gear is non-p";
VAL_ 1137 ICM_Maintenance_tips 0 "Tip_Not_Present" 1 "Tip_Present";
VAL_ 1137 ICM_FuelLevelFailSts 0 "Fail_Not_Present" 1 "Fail_Present";
VAL_ 1142 HCU_4_G_EDrvOnly 0 "Not Active" 1 "NoRequest" 2 "Request" 3 "Reserved";
VAL_ 1142 HCU_4_G_ForcedPrkgChrg 0 "Not Active" 1 "NoRequest" 2 "Request" 3 "Reserved";
VAL_ 1142 HCU_4_G_SumEgyCns 511 "Invalid";
VAL_ 1142 HCU_4_G_EngRunFuCns 511 "Invalid";
VAL_ 1143 OBC_CC_ConnectSts 0 "Not connected" 1 "Charge Connected" 2 "V2V" 3 "V2L" 4 "Half Connection" 5 "Error" 6 "Reserved" 7 "Reserved";
VAL_ 1143 DCDC_WorkingMode 0 "Init" 1 "Standby" 2 "Buck" 3 "Fault" 4 "Reserve" 5 "Reserve" 6 "Reserve" 7 "Reserve" 8 "Reserve" 9 "Reserve" 10 "Reserve" 11 "Reserve" 12 "Reserve" 13 "Reserve" 14 "Reserve" 15 "Reserve";
VAL_ 1143 OBC_InnerDischgReq 0 "No Req" 1 "Req";
VAL_ 1143 CDU_HVILFault 0 "No fault" 1 "Fault";
VAL_ 1144 ICC_HvBattKeepWarmSet 0 "Not active" 1 "active";
VAL_ 1144 ICC_CarSickRelfModeReq 0 "Not Active" 1 "ON" 2 "OFF" 3 "Reserved";
VAL_ 1144 ICC_HvBattKeepWarmActiveReq 0 "Not active" 1 "StartWarm" 2 "EndWarm" 3 "Not Used";
VAL_ 1155 ASU_3_LvlAdj_Restriction 0 "Initializing" 1 "inhibit" 2 "Not inhibit" 3 "invalid";
VAL_ 1167 ICC_KeyDriveModememory 0 "Not Active" 1 "ON" 2 "OFF" 3 "Reserved";
VAL_ 1167 ICC_DriveModeSet 0 "Not Active" 1 "ECO" 2 "NORMAL" 3 "SPORT" 4 "SNOW" 5 "MUD" 6 "OffRoad" 7 "SAND" 8 "ROCK" 9 "EXPERT" 10 "X" 11 "WADE" 12 "UTURN" 13 "DRIFT" 14 "TOW" 15 "OffroadRace" 16 "CRAWL" 17 "Reserved" 18 "Reserved" 19 "Reserved" 20 "Reserved" 21 "Reserved" 22 "Reserved" 23 "Reserved" 24 "Reserved" 25 "Reserved" 26 "Reserved" 27 "Reserved" 28 "Reserved" 29 "Reserved" 30 "Reserved" 31 "Reserved";
VAL_ 1167 ICC_DRIFTModeSetReq 0 "Not active" 1 "Entry Mode" 2 "Master mode" 3 "Expert mode";
VAL_ 1167 ICC_EXPERTEIPBESPSet 0 "Not Active" 1 "TCS_VDC_OFF" 2 "ALL_ON" 3 "ALL_OFF";
VAL_ 1167 ICC_EXPERTEcoSet 0 "Not Active" 1 "ON" 2 "OFF" 3 "Reserved";
VAL_ 1167 ICC_EXPERTNormSet 0 "NotActive" 1 "ON" 2 "OFF" 3 "Reserved";
VAL_ 1167 ICC_EXPERTSportSet 0 "Not Active" 1 "ON" 2 "OFF" 3 "Reserved";
VAL_ 1167 ICC_CrossaxisSet 0 "Not Active" 1 "ON" 2 "OFF" 3 "Reserved";
VAL_ 1167 ICC_EXPERTRWDSet 0 "Not Active" 1 "ON" 2 "OFF" 3 "Reserved";
VAL_ 1167 ICC_EXPERTAWDSet 0 "Not Active" 1 "ON" 2 "OFF" 3 "Reserved";
VAL_ 1167 ICC_EXPERTAutoSet 0 "Not Active" 1 "ON" 2 "OFF" 3 "Reserved";
VAL_ 1167 ICC_CLIMBSet 0 "Not Active" 1 "ON" 2 "OFF" 3 "Reserved";
VAL_ 1167 ICC_DriveModeExitSet 0 "Not Active" 1 "ON" 2 "OFF" 3 "Reserved";
VAL_ 1167 ICC_CCOSwtReq 0 "Not Active" 1 "ON" 2 "OFF" 3 "Reserved";
VAL_ 1167 ICC_TABSwtReq 0 "Not Active" 1 "ON" 2 "OFF" 3 "Reserved";
VAL_ 1167 ICC_V2L_IntlDisChg 0 "Not Active" 1 "OFF" 2 "IntelV2L ON" 3 "Reserved";
VAL_ 1167 ICC_ExhibitionModeSwitch 0 "Not Active" 1 "ON" 2 "OFF" 3 "Reserved";
VAL_ 1167 ICC_TrailerMode 0 "Not Active" 1 "ON" 2 "OFF" 3 "Reserved";
VAL_ 1167 ICC_V2L_DisChgMem 0 "Not Active" 1 "Remember" 2 "No Remember" 3 "Reserved";
VAL_ 1167 ICC_DrivePowerDispSet 0 "Not Active" 1 "PercentDisp" 2 "kWDisp" 3 "Reserved";
VAL_ 1167 ICC_WLTC_to_CLTC_Mode 0 "Not Active" 1 "CLTC" 2 "WLTC" 3 "Reserved";
VAL_ 1167 ICC_StopChrgnSwitch 0 "Not Active" 1 "ON" 2 "OFF" 3 "Reserved";
VAL_ 1167 ICC_StopChrgnMode 0 "Not Active" 1 "Silence" 2 "Quick" 3 "Reserved";
VAL_ 1167 ICC_RegenerateLevelCtrl 0 "Not Active" 1 "Low" 2 "High" 3 "middle" 4 "SinglePedl" 5 "Reserved" 6 "Reserved" 7 "Reserved";
VAL_ 1167 ICC_SinglePedalMem 0 "Not Active" 1 "ON" 2 "OFF" 3 "Reserved";
VAL_ 1167 ICC_FuelDetnSwt 0 "Not Active" 1 "ON" 2 "OFF" 3 "Reserved";
VAL_ 1167 ICC_FuelDetnState 0 "Not Active" 1 "High Idle" 2 "Low Idle" 3 "Reserved";
VAL_ 1167 ICC_FuelDetnOpDefeated 0 "No Prompt" 1 "Prompt";
VAL_ 1167 ICC_HVDownRepairMode 0 "Not Active" 1 "ON" 2 "OFF" 3 "Reserved";
VAL_ 1167 ICC_UTURNSnowSet 0 "Not Active" 1 "ON" 2 "OFF" 3 "Reserved";
VAL_ 1167 ICC_UTURNSandSet 0 "Not Active" 1 "ON" 2 "OFF" 3 "Reserved";
VAL_ 1167 ICC_UTURNMudSet 0 "Not Active" 1 "ON" 2 "OFF" 3 "Reserved";
VAL_ 1167 ICC_UTURNGrassSet 0 "Not Active" 1 "ON" 2 "OFF" 3 "Reserved";
VAL_ 1167 ICC_DeepSnowSet_48Fh 0 "Not_Active" 1 "ON" 2 "OFF";
VAL_ 1167 ICC_LTCDispSet2 0 "Not Active" 1 "WLTC" 2 "CLTC" 3 "Reserved";
VAL_ 1167 ICC_SetSocManage 0 "NotActive" 1 "Default" 2 "SAVE" 3 "Auto" 4 "Charge" 5 "Reserved" 6 "Reserved" 7 "Reserved";
VAL_ 1167 ICC_WadeModeSet_48Fh 0 "Not Active" 1 "Convenmod" 2 "WadeSts" 3 "SailingFunc" 4 "UpbeachSts" 5 "EmerfloatingSts";
VAL_ 1167 ICC_LightSandSet_48Fh 0 "Not Active" 1 "ON" 2 "OFF" 3 "reserved";
